VERSION "$Format:%h$"

NS_ :

BS_:

BU_: APB APP APS BCCEN BDY DAS DBG EAS EPAS EPAS2 EPAS3S EPB EPBM ESP GTW GTWU IBST IC MCU OCS PARK PARK3 RADAR RCM RT3000 SCCM SDM SEC TAS TAS2 TAS2DBG TOOL TPMS VCSEATD VCSEATP

BO_ 1497 DAS_carLog: 8 DAS
 SG_ DAS_carLogMultiplexer M : 0|4@1+ (1,0) [0|15] "" GTW
 SG_ DAS_autosteerUnavailableReason m0 : 4|6@1+ (1,0) [0|63] "" GTW
 SG_ DAS_alcBehaviorAbortReason m0 : 10|4@1+ (1,0) [0|15] "" GTW
 SG_ DAS_alcBehaviorState m0 : 14|3@1+ (1,0) [0|7] "" GTW
 SG_ DAS_radarTarget5_dx m1 : 4|12@1+ (0.0625,0) [0|255.9375] "m" GTW
 SG_ DAS_radarTarget1_dx m1 : 16|12@1+ (0.0625,0) [0|255.9375] "m" GTW
 SG_ DAS_radarTarget1_VxRel m1 : 28|8@1+ (0.2,-25.6) [-25.6|25.4] "m/s" GTW
 SG_ DAS_mobileyeVehAebFlag m2 : 4|1@1+ (1,0) [0|1] "" GTW
 SG_ DAS_mobileyePedAebFlag m2 : 5|1@1+ (1,0) [0|1] "" GTW
 SG_ DAS_mobileyeIPSOapproved m2 : 6|1@1+ (1,0) [0|1] "" GTW
 SG_ DAS_fcmSteeringOverride m2 : 7|1@1+ (1,0) [0|1] "" GTW
 SG_ DAS_fcmCollisionStage3Checks m2 : 8|8@1+ (1,0) [0|255] "" GTW
 SG_ DAS_fcmThreatAssesmentMode m2 : 16|3@1+ (1,0) [0|7] "" GTW
 SG_ DAS_constructionArea m2 : 19|2@1+ (1,0) [0|3] "" GTW
 SG_ DAS_associated_rad_object m2 : 22|2@1+ (1,0) [0|3] "" GTW
 SG_ DAS_LC_handsOnReason m2 : 24|6@1+ (1,0) [0|31] "" GTW
 SG_ DAS_ACC_camStatus m2 : 30|2@1+ (1,0) [0|3] "" GTW
 SG_ DAS_aeb_not_activating_reason m2 : 32|5@1+ (1,0) [0|31] "" GTW
 SG_ DAS_handsOnDetected m2 : 38|2@1+ (1,0) [0|2] "" GTW
 SG_ DAS_driveOnNavUnavailableReason m2 : 40|6@1+ (1,0) [0|63] "" GTW
 SG_ DAS_accUnavailableReason m2 : 46|6@1+ (1,0) [0|63] "" GTW
 SG_ DAS_desiredTarget_dx m3 : 16|8@1+ (0.5,0) [0|127] "m" GTW
 SG_ DAS_radarTarget2_dx m3 : 24|12@1+ (0.0625,0) [0|255.9375] "m" GTW
 SG_ DAS_radarTarget3_dx m3 : 36|12@1+ (0.0625,0) [0|255.9375] "m" GTW
 SG_ DAS_radarTarget4_dx m3 : 48|12@1+ (0.0625,0) [0|255.9375] "m" GTW

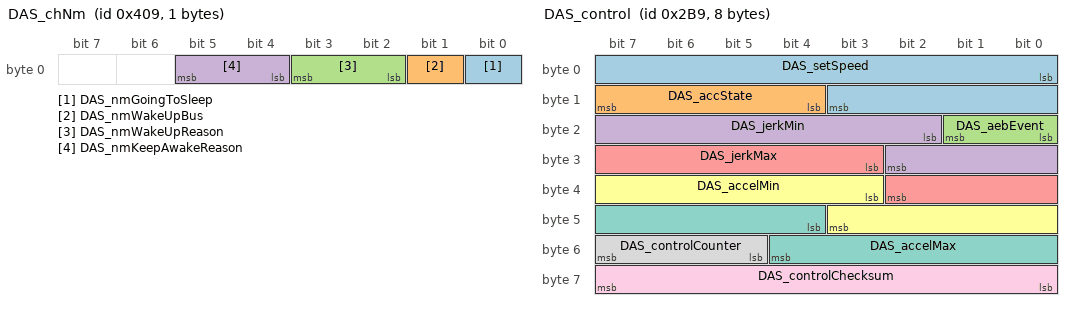
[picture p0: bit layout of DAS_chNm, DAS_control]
BO_ 1033 DAS_chNm: 1 DAS
 SG_ DAS_nmGoingToSleep : 0|1@1+ (1,0) [0|0] "" GTW,APS
 SG_ DAS_nmWakeUpBus : 1|1@1+ (1,0) [0|0] "" GTW,APS
 SG_ DAS_nmWakeUpReason : 2|2@1+ (1,0) [0|0] "" GTW,APS
 SG_ DAS_nmKeepAwakeReason : 4|2@1+ (1,0) [0|0] "" GTW,APS

BO_ 697 DAS_control: 8 DAS
 SG_ DAS_setSpeed : 0|12@1+ (0.1,0) [0|409.4] "kph" GTW,EPB,EPBM,APS
 SG_ DAS_accState : 12|4@1+ (1,0) [0|0] "" GTW,EPB,EPBM,APS
 SG_ DAS_aebEvent : 16|2@1+ (1,0) [0|3] "" GTW,APS
 SG_ DAS_jerkMin : 18|9@1+ (0.03,-15.232) [-15.232|0.098] "m/s^3" GTW,APS
 SG_ DAS_jerkMax : 27|8@1+ (0.059,0) [0|15.045] "m/s^3" GTW,APS
 SG_ DAS_accelMin : 35|9@1+ (0.04,-15) [-15|5.44] "m/s^2" GTW,APS
 SG_ DAS_accelMax : 44|9@1+ (0.04,-15) [-15|5.44] "m/s^2" GTW,APS
 SG_ DAS_controlCounter : 53|3@1+ (1,0) [0|0] "" GTW,APS
 SG_ DAS_controlChecksum : 56|8@1+ (1,0) [0|0] "" GTW,APS

BO_ 1529 DAS_dataLog: 8 DAS
 SG_ DAS_logMltplxr M : 0|8@1+ (1,0) [0|0] "" GTW
 SG_ DAS_init_version m10 : 8|8@1+ (1,0) [0|255] "" Vector__XXX
 SG_ DAS_leftWheel m10 : 16|8@1+ (0.01,0) [0|100] "m" Vector__XXX
 SG_ DAS_RightWheel m10 : 24|8@1+ (0.01,0) [0|100] "m" Vector__XXX
 SG_ DAS_cameraHeight m10 : 32|8@1+ (0.01,0) [0|150] "m" Vector__XXX
 SG_ DAS_focalLength m10 : 40|16@1+ (1,0) [0|500] "" Vector__XXX
 SG_ DAS_horizonFull m10 : 56|8@1+ (1,0) [0|255] "" Vector__XXX
 SG_ DAS_yawFull m11 : 8|8@1- (1,0) [-128|127] "" Vector__XXX
 SG_ DAS_init_autofixHorizon m11 : 16|8@1- (1,0) [-128|127] "" Vector__XXX
 SG_ DAS_init_autofixYaw m11 : 24|8@1- (1,0) [-128|127] "" Vector__XXX
 SG_ DAS_bottom m11 : 32|8@1- (1,0) [-128|127] "" Vector__XXX
 SG_ DAS_top m11 : 40|8@1+ (1,0) [0|255] "" Vector__XXX
 SG_ DAS_minHorizon m11 : 48|8@1- (1,0) [-128|127] "" Vector__XXX
 SG_ DAS_maxHorizon m11 : 56|8@1- (1,0) [-128|127] "" Vector__XXX
 SG_ DAS_maxYaw m12 : 8|8@1+ (1,0) [0|255] "" Vector__XXX
 SG_ DAS_rollAngle m12 : 16|16@1- (0.001,0) [-1500|1500] "rads" Vector__XXX
 SG_ DAS_regionCode m12 : 32|8@1+ (1,0) [0|11] "" Vector__XXX
 SG_ DAS_drivingSide m12 : 40|2@1+ (1,0) [0|3] "" Vector__XXX
 SG_ DAS_refPointX m12 : 48|8@1+ (0.1,0) [0|0] "m" Vector__XXX
 SG_ DAS_refPointY m12 : 56|8@1+ (0.1,0) [0|255] "m" Vector__XXX
 SG_ DAS_roadEdgeWarningEnabled m13 : 8|8@1+ (1,0) [0|255] "" Vector__XXX
 SG_ DAS_detectConstructionArea m13 : 16|8@1+ (1,0) [0|255] "" Vector__XXX
 SG_ DAS_corridor_outer_boundary m13 : 24|8@1+ (0.01,0) [0|255] "m" Vector__XXX
 SG_ DAS_pos_warn_dist_thresh m13 : 32|8@1+ (0.01,0) [0|255] "m" Vector__XXX
 SG_ DAS_outer_dist_term_warn m13 : 40|8@1+ (0.01,0) [0|255] "m" Vector__XXX
 SG_ DAS_narrow_lane_width m13 : 48|8@1+ (0.1,0) [0|255] "m" Vector__XXX
 SG_ DAS_min_lane_width m13 : 56|8@1+ (0.1,0) [0|255] "m" Vector__XXX
 SG_ DAS_speed_turn_off m14 : 8|8@1+ (0.1,0) [0|255] "m/s" Vector__XXX
 SG_ DAS_speed_turn_on m14 : 16|8@1+ (0.1,0) [0|255] "m/s" Vector__XXX
 SG_ DAS_t_max_wrn m14 : 24|8@1+ (1,0) [0|255] "" Vector__XXX
 SG_ DAS_t_min_wrn m14 : 32|8@1+ (1,0) [0|255] "" Vector__XXX
 SG_ DAS_enableLaneCenterPred m14 : 40|8@1+ (1,0) [0|255] "" Vector__XXX
 SG_ DAS_OC_REDUCED_SENSITIVITY m14 : 48|8@1+ (0.1,0) [0|255] "smth" Vector__XXX
 SG_ DAS_Reserved_1 m14 : 56|8@1+ (1,0) [0|255] "" Vector__XXX
 SG_ DAS_HilMode m15 : 8|8@1+ (1,0) [0|255] "" Vector__XXX
 SG_ DAS_StartupFrameIndex m15 : 16|8@1+ (1,0) [0|255] "" Vector__XXX
 SG_ DAS_forcedNonParallel m15 : 24|8@1+ (1,0) [0|255] "" Vector__XXX
 SG_ DAS_disableRectangular m15 : 32|8@1+ (1,0) [0|255] "" Vector__XXX
 SG_ DAS_Reserved_2 m15 : 40|8@1+ (1,0) [0|255] "" Vector__XXX
 SG_ DAS_calib_reply_ret m16 : 8|8@1+ (1,0) [0|255] "" Vector__XXX
 SG_ DAS_calib_reply_ct_type m16 : 16|8@1+ (1,0) [0|255] "" Vector__XXX
 SG_ DAS_calib_reply_ct_ver m16 : 24|8@1+ (1,0) [0|255] "" Vector__XXX
 SG_ DAS_mesp_health_error_code m16 : 32|8@1+ (1,0) [0|255] "" Vector__XXX
 SG_ DAS_mesp_health_error_details m16 : 40|8@1+ (1,0) [0|255] "" Vector__XXX
 SG_ DAS_mesp_health_main_state m16 : 48|8@1+ (1,0) [0|255] "" Vector__XXX
 SG_ DAS_mesp_health_sub_state m16 : 56|8@1+ (1,0) [0|255] "" Vector__XXX
 SG_ DAS_mesp_health_diag_flag_0 m17 : 8|16@1+ (1,0) [0|255] "" Vector__XXX
 SG_ DAS_mesp_health_diag_flag_1 m17 : 24|16@1+ (1,0) [0|255] "" Vector__XXX
 SG_ DAS_mesp_health_state_data_1 m17 : 40|8@1+ (1,0) [0|255] "" Vector__XXX
 SG_ DAS_mesp_health_state_data_2 m17 : 48|8@1+ (1,0) [0|255] "" Vector__XXX
 SG_ DAS_bootmsg_testResults m18 : 8|16@1+ (1,0) [0|255] "" Vector__XXX
 SG_ DAS_bootmsg_EyeQST_Test m18 : 24|32@1+ (1,0) [0|255] "" Vector__XXX
 SG_ DAS_bootmsg_EyeQ_Temp_CPU m18 : 56|8@1- (1,0) [-128|127] "" Vector__XXX
 SG_ DAS_bootmsg_EyeQ_Temp_VMP m19 : 8|8@1+ (1,0) [0|255] "" Vector__XXX
 SG_ DAS_bootmsg_LPDDR2_temp_status m19 : 16|8@1+ (1,0) [0|255] "" Vector__XXX
 SG_ DAS_bootmsg_BootVersion m19 : 24|32@1+ (1,0) [0|255] "" Vector__XXX
 SG_ DAS_bootmsg_BoardRevision m19 : 56|8@1+ (1,0) [0|255] "" Vector__XXX
 SG_ DAS_bootmsg_ApplicationtVersion m20 : 8|32@1+ (1,0) [0|255] "" Vector__XXX
 SG_ DAS_bootmsg_EyeQ_LotNumber m20 : 40|24@1+ (1,0) [0|255] "" Vector__XXX
 SG_ DAS_bootmsg_DDR_MfgCode m21 : 8|8@1+ (1,0) [0|255] "" Vector__XXX
 SG_ DAS_bootmsg_Flash_MfgCode m21 : 16|8@1+ (1,0) [0|255] "" Vector__XXX
 SG_ DAS_bootmsg_BoardProjectCode m21 : 24|8@1+ (1,0) [0|255] "" Vector__XXX
 SG_ DAS_bootmsg_Flash_2_MfgCode m21 : 32|8@1+ (1,0) [0|255] "" Vector__XXX
 SG_ DAS_bootmsg_DDR_Size m21 : 40|8@1+ (1,0) [0|255] "" Vector__XXX
 SG_ DAS_bootmsg_FlashSize m21 : 48|8@1+ (1,0) [0|255] "" Vector__XXX
 SG_ DAS_bootmsg_Flash_2_Size m21 : 56|8@1+ (1,0) [0|255] "" Vector__XXX
 SG_ DAS_scaLogVersion m22 : 8|3@1+ (1,0) [0|15] "" Vector__XXX
 SG_ DAS_scaLogType m22 : 11|3@1+ (1,0) [0|3] "" Vector__XXX
 SG_ DAS_scaLDWstatus m22 : 14|2@1+ (1,0) [0|3] "" Vector__XXX
 SG_ DAS_scaLeftLaneChange m22 : 16|1@1+ (1,0) [0|1] "" Vector__XXX
 SG_ DAS_scaRightLaneChange m22 : 17|1@1+ (1,0) [0|1] "" Vector__XXX
 SG_ DAS_scaMinLeftUltraDist m22 : 18|9@1+ (0.01,0) [0|5.11] "m" Vector__XXX
 SG_ DAS_scaMinRightUltraDist m22 : 27|9@1+ (0.01,0) [0|5.11] "m" Vector__XXX
 SG_ DAS_scaMaxTorsionBarTorque m22 : 36|12@1+ (0.01,-20.5) [-20.5|20.45] "Nm" Vector__XXX
 SG_ DAS_scaMinTTC m22 : 48|4@1+ (0.1,0) [0|1.6] "s" Vector__XXX
 SG_ DAS_scaMaxSteeringWheelAngleRate m22 : 52|7@1+ (1,-63) [-64|63] "deg/s" Vector__XXX
 SG_ DAS_scaOnHighway m22 : 59|1@1+ (1,0) [0|1] "" Vector__XXX
 SG_ DAS_scaTTCDuration m22 : 60|4@1+ (0.1,0) [0|1.6] "s" Vector__XXX
 SG_ DAS_radarTarg5_dx m23 : 8|8@1+ (0.0625,0) [0|15.9375] "m" Vector__XXX
 SG_ DAS_radarTarg1_dx m23 : 16|8@1+ (0.0625,0) [0|15.9375] "m" Vector__XXX
 SG_ DAS_camGenObj_dx m23 : 24|8@1+ (0.05,0) [0|10] "m" Vector__XXX
 SG_ DAS_camCipv_dx m23 : 32|8@1+ (0.2,0) [0|51] "m" Vector__XXX
 SG_ DAS_camPed_dx m23 : 40|8@1+ (0.2,0) [0|51] "m" Vector__XXX
 SG_ DAS_stwAngle m23 : 48|8@1- (1,0) [-128|127] "deg" Vector__XXX
 SG_ DAS_yawRate m23 : 56|8@1+ (0.015625,-2) [-2|2] "rad/s" Vector__XXX

BO_ 1824 DAS_debug: 8 DAS
 SG_ DAS_debugMultiplexer M : 0|8@1+ (1,0) [0|0] "" Vector__XXX
 SG_ DAS_eyeQMode m0 : 8|8@1+ (1,0) [0|0] "" Vector__XXX
 SG_ DAS_absoluteFrame m0 : 16|32@1+ (1,0) [0|0] "" Vector__XXX
 SG_ DAS_pp_offset_desired m0 : 48|8@1- (0.01,0) [-1.28|1.27] "m" Vector__XXX
 SG_ DAS_appMobileyeStatus m0 : 56|8@1+ (1,0) [0|255] "" Vector__XXX
 SG_ DAS_autofixStatus m1 : 8|2@1+ (1,0) [0|0] "" Vector__XXX
 SG_ DAS_calType m1 : 12|4@1+ (1,0) [0|0] "" Vector__XXX
 SG_ DAS_autofixHorizon m1 : 16|8@1- (1,0) [-30|30] "" Vector__XXX
 SG_ DAS_autofixYaw m1 : 24|8@1- (1,0) [-40|40] "" Vector__XXX
 SG_ DAS_freespaceLeftC0 m2 : 8|8@1+ (0.1,-12.8) [-12.8|12.7] "m" Vector__XXX
 SG_ DAS_freespaceLeftC1 m2 : 16|8@1+ (0.0016,-0.2) [-0.2|0.2] "rad" Vector__XXX
 SG_ DAS_freespaceRightC0 m2 : 24|8@1+ (0.1,-12.8) [-12.8|12.7] "m" Vector__XXX
 SG_ DAS_freespaceRightC1 m2 : 32|8@1+ (0.0016,-0.2) [-0.2|0.2] "rad" Vector__XXX
 SG_ DAS_freespaceLeftFarZ m2 : 40|4@1+ (4,0) [0|60] "m" Vector__XXX
 SG_ DAS_freespaceRightFarZ m2 : 44|4@1+ (4,0) [0|60] "m" Vector__XXX
 SG_ DAS_rawLDW m2 : 48|2@1+ (1,0) [0|2] "" Vector__XXX
 SG_ DAS_freespaceLDW m2 : 50|2@1+ (1,0) [0|2] "" Vector__XXX
 SG_ DAS_lanesValid m2 : 52|1@1+ (1,0) [0|1] "" Vector__XXX
 SG_ DAS_eldw m2 : 53|1@1+ (1,0) [0|1] "" Vector__XXX
 SG_ DAS_laneMerge m2 : 54|2@1+ (1,0) [0|4] "" Vector__XXX
 SG_ DAS_freespaceLeftNearZ m2 : 56|4@1+ (4,0) [0|60] "m" Vector__XXX
 SG_ DAS_freespaceRightNearZ m2 : 60|4@1+ (4,0) [0|60] "m" Vector__XXX
 SG_ DAS_highestSeqRcvd m3 : 8|12@1+ (1,0) [0|0] "" Vector__XXX
 SG_ DAS_errorFrameNum m3 : 20|12@1+ (1,0) [0|0] "" Vector__XXX
 SG_ DAS_numOfOldPktErrs m3 : 32|8@1+ (1,0) [0|0] "" Vector__XXX
 SG_ DAS_numOfSeqErrs m3 : 40|8@1+ (1,0) [0|0] "" Vector__XXX
 SG_ DAS_numOfCrcErrs m3 : 48|8@1+ (1,0) [0|0] "" Vector__XXX
 SG_ DAS_unusedW0 m3 : 56|8@1+ (1,0) [0|0] "" Vector__XXX
 SG_ DAS_Stop_Sign_dist m4 : 8|11@1+ (0.1,-50) [-50|102.3] "m" Vector__XXX
 SG_ DAS_Stop_Sign_detected m4 : 19|1@1+ (1,0) [0|1] "" Vector__XXX
 SG_ DAS_Stop_Sign_warning m4 : 20|1@1+ (1,0) [0|1] "" Vector__XXX
 SG_ DAS_TFL_jnc_status m4 : 21|3@1+ (1,0) [0|1] "" Vector__XXX
 SG_ DAS_TFL_jnc_dist m4 : 24|10@1+ (0.25,-50) [-50|205.75] "m" Vector__XXX
 SG_ DAS_TFL_stop_line_dist m4 : 34|11@1+ (0.1,-50) [-50|102.3] "m" Vector__XXX
 SG_ DAS_TFL_ttc m4 : 45|9@1+ (0.01,0) [0|5.11] "seconds" Vector__XXX
 SG_ DAS_TFL_warning m4 : 54|1@1+ (1,0) [0|1] "" Vector__XXX
 SG_ DAS_TFL_mainID m4 : 56|8@1+ (1,0) [0|255] "" Vector__XXX
 SG_ DAS_tbt_filtered m5 : 8|12@1+ (0.01,-20.5) [-20.5|20.45] "Nm" Vector__XXX
 SG_ DAS_apcIntState m6 : 8|4@1+ (1,0) [0|15] "" Vector__XXX
 SG_ DAS_SP_distance m6 : 12|12@1+ (1,0) [0|4095] "cm" Vector__XXX
 SG_ DAS_SP_instruction m6 : 24|4@1+ (1,0) [0|15] "" Vector__XXX
 SG_ DAS_SP_status m6 : 28|4@1+ (1,0) [0|15] "" Vector__XXX
 SG_ DAS_SP_autoSummonRequest m6 : 32|1@1+ (1,0) [0|1] "" Vector__XXX
 SG_ DAS_estimatedSpeedLimitType m6 : 33|3@1+ (1,0) [0|7] "" Vector__XXX
 SG_ DAS_rampType m6 : 39|2@1+ (1,0) [0|3] "" Vector__XXX
 SG_ DAS_estimatedSpeedLimit m6 : 41|10@1+ (0.2,0) [0|102.2] "mph" Vector__XXX
 SG_ DAS_resumeSpeed m6 : 51|10@1+ (0.2,0) [0|102.2] "mph" Vector__XXX
 SG_ DAS_accTimeGap m6 : 61|3@1+ (0.2,0.8) [0.8|2.2] "s" Vector__XXX
 SG_ DAS_SP_cMin m7 : 8|8@1+ (0.0025,-0.32) [-0.32|0.31] "1/m" Vector__XXX
 SG_ DAS_SP_cMax m7 : 16|8@1+ (0.0025,-0.32) [-0.32|0.31] "1/m" Vector__XXX
 SG_ DAS_SP_interCMin m7 : 24|8@1+ (0.0025,-0.32) [-0.32|0.31] "1/m" Vector__XXX
 SG_ DAS_SP_interCMax m7 : 32|8@1+ (0.0025,-0.32) [-0.32|0.31] "1/m" Vector__XXX
 SG_ DAS_SP_cDesired m7 : 40|8@1+ (0.0025,-0.32) [-0.32|0.31] "1/m" Vector__XXX
 SG_ DAS_SP_vehPosX m8 : 8|12@1+ (0.01,-20.48) [-20.48|20.48] "m" Vector__XXX
 SG_ DAS_SP_vehPosY m8 : 20|12@1+ (0.01,-20.48) [-20.48|20.48] "m" Vector__XXX
 SG_ DAS_SP_endPosX m8 : 32|12@1+ (0.01,-20.48) [-20.48|20.48] "m" Vector__XXX
 SG_ DAS_SP_endPosY m8 : 44|12@1+ (0.01,-20.48) [-20.48|20.48] "m" Vector__XXX
 SG_ DAS_SP_sprecordX m9 : 8|12@1+ (0.01,-20.48) [-20.48|20.48] "m" Vector__XXX
 SG_ DAS_SP_sprecordY m9 : 20|12@1+ (0.01,-20.48) [-20.48|20.48] "m" Vector__XXX
 SG_ DAS_SP_collisionDist m9 : 32|12@1+ (0.01,-20.48) [-20.48|20.48] "m" Vector__XXX
 SG_ DAS_dbg_msg_count m10 : 8|8@1+ (1,0) [0|0] "" Vector__XXX
 SG_ DAS_dbg_image_data m10 : 16|48@1+ (1,0) [0|0] "" Vector__XXX
 SG_ DAS_PMM_ussConfidence m11 : 8|8@1+ (1,0) [0|255] "" Vector__XXX
 SG_ DAS_PMM_ussDistance m11 : 16|8@1+ (1,0) [0|255] "cm" Vector__XXX
 SG_ DAS_PMM_radarConfidence m11 : 24|8@1+ (1,0) [0|255] "" Vector__XXX
 SG_ DAS_PMM_radarDistance m11 : 32|8@1+ (1,0) [0|255] "cm" Vector__XXX
 SG_ DAS_PMM_totalThreat m11 : 40|8@1+ (1,0) [0|255] "" Vector__XXX
 SG_ DAS_PMM_frontThreat m11 : 48|2@1+ (1,0) [0|3] "" Vector__XXX
 SG_ DAS_PMM_rearThreat m11 : 50|2@1+ (1,0) [0|3] "" Vector__XXX
 SG_ DAS_i2c_dev_reg m12 : 8|8@1+ (1,0) [0|255] "" Vector__XXX
 SG_ DAS_i2c_dev_data m12 : 16|8@1+ (1,0) [0|255] "" Vector__XXX
 SG_ DAS_i2c_cmd_idx m12 : 24|16@1+ (1,0) [0|255] "" Vector__XXX
 SG_ DAS_i2c_bytes_written m12 : 40|8@1+ (1,0) [0|255] "" Vector__XXX
 SG_ DAS_i2c_sensor_cmd m12 : 48|16@1+ (1,0) [0|255] "" Vector__XXX
 SG_ DAS_ACC_intState m20 : 8|4@1+ (1,0) [0|0] "" Vector__XXX
 SG_ DAS_ACC_camCIPVStatus m20 : 12|3@1+ (1,0) [0|0] "" Vector__XXX
 SG_ DAS_ACC_radCIPVStatus m20 : 15|3@1+ (1,0) [0|0] "" Vector__XXX
 SG_ DAS_ACC_radObstacleRelevant m20 : 18|1@1+ (1,0) [0|0] "" Vector__XXX
 SG_ DAS_ACC_pedestrianStatus m20 : 19|2@1+ (1,0) [0|0] "" Vector__XXX
 SG_ DAS_ACC_drivingOnHighway m20 : 21|1@1+ (1,0) [0|0] "" Vector__XXX
 SG_ DAS_ACC_Ego_speed m20 : 26|10@1+ (0.05,0) [0|51.15] "m/s" Vector__XXX
 SG_ DAS_ACC_Ego_accel m20 : 36|8@1+ (0.06,-10) [-10|5.3] "m/s^2" Vector__XXX
 SG_ DAS_ACC_deadbandMultiplier m20 : 44|7@1+ (0.008,0) [0|1.016] "1" Vector__XXX
 SG_ DAS_ACC_leftLaneExists m20 : 51|1@1+ (1,0) [0|0] "" Vector__XXX
 SG_ DAS_ACC_rightLaneExists m20 : 52|1@1+ (1,0) [0|0] "" Vector__XXX
 SG_ DAS_ACC_camInFrontOfCIPVRel m20 : 53|1@1+ (1,0) [0|0] "" Vector__XXX
 SG_ DAS_ACC_radInFrontOfCIPVRel m20 : 54|1@1+ (1,0) [0|0] "" Vector__XXX
 SG_ DAS_ACC_controlType m20 : 56|3@1+ (1,0) [0|4] "" Vector__XXX
 SG_ DAS_ACC_overtakeMode m20 : 59|2@1+ (1,0) [0|3] "" Vector__XXX
 SG_ DAS_ACC_BCW_decelCheck m20 : 62|1@1+ (1,0) [0|0] "" Vector__XXX
 SG_ DAS_ACC_BCW m20 : 63|1@1+ (1,0) [0|0] "" Vector__XXX
 SG_ DAS_ACC_camCIPVRadObjID m21 : 8|8@1+ (1,0) [0|0] "" Vector__XXX
 SG_ DAS_ACC_camCIPVRadMatchConf m21 : 16|4@1+ (1,0) [0|0] "" Vector__XXX
 SG_ DAS_ACC_camCIPVClass m21 : 20|4@1+ (1,0) [0|0] "" Vector__XXX
 SG_ DAS_ACC_camCIPVRelevancy m21 : 24|4@1+ (1,0) [0|0] "" Vector__XXX
 SG_ DAS_ACC_camCIPVLane m21 : 28|4@1+ (1,0) [0|0] "" Vector__XXX
 SG_ DAS_ACC_camCIPVLaneStatus m21 : 32|4@1+ (1,0) [0|0] "" Vector__XXX
 SG_ DAS_ACC_camCIPVBrakeLight m21 : 36|4@1+ (1,0) [0|0] "" Vector__XXX
 SG_ DAS_ACC_camCIPVMotionStatus m21 : 40|4@1+ (1,0) [0|0] "" Vector__XXX
 SG_ DAS_ACC_camCIPVLost m21 : 44|2@1+ (1,0) [0|0] "" Vector__XXX
 SG_ DAS_ACC_camCIPVFreeSpace m21 : 46|2@1+ (1,0) [0|0] "" Vector__XXX
 SG_ DAS_ACC_camStopAndGoStatus m21 : 48|2@1+ (1,0) [0|0] "" Vector__XXX
 SG_ DAS_ACC_camLeftCloseCutin m21 : 50|1@1+ (1,0) [0|0] "" Vector__XXX
 SG_ DAS_ACC_camRightCloseCutin m21 : 51|1@1+ (1,0) [0|0] "" Vector__XXX
 SG_ DAS_ACC_camPedestriansPresent m21 : 52|1@1+ (1,0) [0|0] "" Vector__XXX
 SG_ DAS_ACC_pathOverlapWTarget m21 : 53|5@1+ (0.2,-2) [-2|4.2] "m" Vector__XXX
 SG_ DAS_ACC_tgt_cipv_dist m22 : 8|10@1+ (0.2,0) [0|204.6] "m" Vector__XXX
 SG_ DAS_ACC_tgt_cipv_camID m22 : 18|6@1+ (1,0) [0|0] "" Vector__XXX
 SG_ DAS_ACC_tgt_cipv_speed m22 : 24|8@1+ (0.2,-5) [-5|46] "m/s" Vector__XXX
 SG_ DAS_ACC_tgt_cipv_radID m22 : 32|6@1+ (1,0) [0|0] "" Vector__XXX
 SG_ DAS_ACC_tgt_cipv_accel m22 : 38|8@1+ (0.06,-10) [-10|5.3] "m/s^2" Vector__XXX
 SG_ DAS_ACC_tgt_cipv_controlState m22 : 46|4@1+ (1,0) [0|0] "" Vector__XXX
 SG_ DAS_ACC_tgt_cipv_type m22 : 50|4@1+ (1,0) [0|0] "" Vector__XXX
 SG_ DAS_ACC_tgt_cipv_valid m22 : 54|1@1+ (1,0) [0|0] "" Vector__XXX
 SG_ DAS_ACC_tgt_cipv_new m22 : 55|1@1+ (1,0) [0|0] "" Vector__XXX
 SG_ DAS_ACC_tgt_cipv_copied m22 : 56|1@1+ (1,0) [0|0] "" Vector__XXX
 SG_ DAS_ACC_tgt_cipv_brakeLights m22 : 57|1@1+ (1,0) [0|0] "" Vector__XXX
 SG_ DAS_ACC_tgt_cipv_blinkerLeft m22 : 58|1@1+ (1,0) [0|0] "" Vector__XXX
 SG_ DAS_ACC_tgt_cipv_blinkerRight m22 : 59|1@1+ (1,0) [0|0] "" Vector__XXX
 SG_ DAS_ACC_tgt_cipv_delay m22 : 60|4@1+ (20,0) [0|300] "ms" Vector__XXX
 SG_ DAS_ACC_tgt_cipv2_dist m23 : 8|10@1+ (0.2,0) [0|204.6] "m" Vector__XXX
 SG_ DAS_ACC_tgt_cipv2_camID m23 : 18|6@1+ (1,0) [0|0] "" Vector__XXX
 SG_ DAS_ACC_tgt_cipv2_speed m23 : 24|8@1+ (0.2,-5) [-5|46] "m/s" Vector__XXX
 SG_ DAS_ACC_tgt_cipv2_radID m23 : 32|6@1+ (1,0) [0|0] "" Vector__XXX
 SG_ DAS_ACC_tgt_cipv2_accel m23 : 38|8@1+ (0.06,-10) [-10|5.3] "m/s^2" Vector__XXX
 SG_ DAS_ACC_tgt_cipv2_controlState m23 : 46|4@1+ (1,0) [0|0] "" Vector__XXX
 SG_ DAS_ACC_tgt_cipv2_type m23 : 50|4@1+ (1,0) [0|0] "" Vector__XXX
 SG_ DAS_ACC_tgt_cipv2_valid m23 : 54|1@1+ (1,0) [0|0] "" Vector__XXX
 SG_ DAS_ACC_tgt_cipv2_new m23 : 55|1@1+ (1,0) [0|0] "" Vector__XXX
 SG_ DAS_ACC_tgt_cipv2_copied m23 : 56|1@1+ (1,0) [0|0] "" Vector__XXX
 SG_ DAS_ACC_tgt_cipv2_brakeLights m23 : 57|1@1+ (1,0) [0|0] "" Vector__XXX
 SG_ DAS_ACC_tgt_cipv2_blinkerLeft m23 : 58|1@1+ (1,0) [0|0] "" Vector__XXX
 SG_ DAS_ACC_tgt_cipv2_blinkerRight m23 : 59|1@1+ (1,0) [0|0] "" Vector__XXX
 SG_ DAS_ACC_tgt_cipv2_delay m23 : 60|4@1+ (20,0) [0|300] "ms" Vector__XXX
 SG_ DAS_ACC_tgt_mcvl_dist m24 : 8|10@1+ (0.2,0) [0|204.6] "m" Vector__XXX
 SG_ DAS_ACC_tgt_mcvl_camID m24 : 18|6@1+ (1,0) [0|0] "" Vector__XXX
 SG_ DAS_ACC_tgt_mcvl_speed m24 : 24|8@1+ (0.2,-5) [-5|46] "m/s" Vector__XXX
 SG_ DAS_ACC_tgt_mcvl_radID m24 : 32|6@1+ (1,0) [0|0] "" Vector__XXX
 SG_ DAS_ACC_tgt_mcvl_accel m24 : 38|8@1+ (0.06,-10) [-10|5.3] "m/s^2" Vector__XXX
 SG_ DAS_ACC_tgt_mcvl_controlState m24 : 46|4@1+ (1,0) [0|0] "" Vector__XXX
 SG_ DAS_ACC_tgt_mcvl_type m24 : 50|4@1+ (1,0) [0|0] "" Vector__XXX
 SG_ DAS_ACC_tgt_mcvl_valid m24 : 54|1@1+ (1,0) [0|0] "" Vector__XXX
 SG_ DAS_ACC_tgt_mcvl_new m24 : 55|1@1+ (1,0) [0|0] "" Vector__XXX
 SG_ DAS_ACC_tgt_mcvl_copied m24 : 56|1@1+ (1,0) [0|0] "" Vector__XXX
 SG_ DAS_ACC_tgt_mcvl_brakeLights m24 : 57|1@1+ (1,0) [0|0] "" Vector__XXX
 SG_ DAS_ACC_tgt_mcvl_blinkerLeft m24 : 58|1@1+ (1,0) [0|0] "" Vector__XXX
 SG_ DAS_ACC_tgt_mcvl_blinkerRight m24 : 59|1@1+ (1,0) [0|0] "" Vector__XXX
 SG_ DAS_ACC_tgt_mcvl_delay m24 : 60|4@1+ (20,0) [0|300] "ms" Vector__XXX
 SG_ DAS_ACC_tgt_mcvr_dist m25 : 8|10@1+ (0.2,0) [0|204.6] "m" Vector__XXX
 SG_ DAS_ACC_tgt_mcvr_camID m25 : 18|6@1+ (1,0) [0|0] "" Vector__XXX
 SG_ DAS_ACC_tgt_mcvr_speed m25 : 24|8@1+ (0.2,-5) [-5|46] "m/s" Vector__XXX
 SG_ DAS_ACC_tgt_mcvr_radID m25 : 32|6@1+ (1,0) [0|0] "" Vector__XXX
 SG_ DAS_ACC_tgt_mcvr_accel m25 : 38|8@1+ (0.06,-10) [-10|5.3] "m/s^2" Vector__XXX
 SG_ DAS_ACC_tgt_mcvr_controlState m25 : 46|4@1+ (1,0) [0|0] "" Vector__XXX
 SG_ DAS_ACC_tgt_mcvr_type m25 : 50|4@1+ (1,0) [0|0] "" Vector__XXX
 SG_ DAS_ACC_tgt_mcvr_valid m25 : 54|1@1+ (1,0) [0|0] "" Vector__XXX
 SG_ DAS_ACC_tgt_mcvr_new m25 : 55|1@1+ (1,0) [0|0] "" Vector__XXX
 SG_ DAS_ACC_tgt_mcvr_copied m25 : 56|1@1+ (1,0) [0|0] "" Vector__XXX
 SG_ DAS_ACC_tgt_mcvr_brakeLights m25 : 57|1@1+ (1,0) [0|0] "" Vector__XXX
 SG_ DAS_ACC_tgt_mcvr_blinkerLeft m25 : 58|1@1+ (1,0) [0|0] "" Vector__XXX
 SG_ DAS_ACC_tgt_mcvr_blinkerRight m25 : 59|1@1+ (1,0) [0|0] "" Vector__XXX
 SG_ DAS_ACC_tgt_mcvr_delay m25 : 60|4@1+ (20,0) [0|300] "ms" Vector__XXX
 SG_ DAS_ACC_tgt_cutin_dist m26 : 8|10@1+ (0.2,0) [0|204.6] "m" Vector__XXX
 SG_ DAS_ACC_tgt_cutin_camID m26 : 18|6@1+ (1,0) [0|0] "" Vector__XXX
 SG_ DAS_ACC_tgt_cutin_speed m26 : 24|8@1+ (0.2,-5) [-5|46] "m/s" Vector__XXX
 SG_ DAS_ACC_tgt_cutin_radID m26 : 32|6@1+ (1,0) [0|0] "" Vector__XXX
 SG_ DAS_ACC_tgt_cutin_accel m26 : 38|8@1+ (0.06,-10) [-10|5.3] "m/s^2" Vector__XXX
 SG_ DAS_ACC_tgt_cutin_controlState m26 : 46|4@1+ (1,0) [0|0] "" Vector__XXX
 SG_ DAS_ACC_tgt_cutin_type m26 : 50|4@1+ (1,0) [0|0] "" Vector__XXX
 SG_ DAS_ACC_tgt_cutin_valid m26 : 54|1@1+ (1,0) [0|0] "" Vector__XXX
 SG_ DAS_ACC_tgt_cutin_new m26 : 55|1@1+ (1,0) [0|0] "" Vector__XXX
 SG_ DAS_ACC_tgt_cutin_copied m26 : 56|1@1+ (1,0) [0|0] "" Vector__XXX
 SG_ DAS_ACC_tgt_cutin_brakeLights m26 : 57|1@1+ (1,0) [0|0] "" Vector__XXX
 SG_ DAS_ACC_tgt_cutin_blinkerLeft m26 : 58|1@1+ (1,0) [0|0] "" Vector__XXX
 SG_ DAS_ACC_tgt_cutin_blinkerRight m26 : 59|1@1+ (1,0) [0|0] "" Vector__XXX
 SG_ DAS_ACC_tgt_cutin_delay m26 : 60|4@1+ (20,0) [0|300] "ms" Vector__XXX
 SG_ DAS_ACC_Target6_dist m27 : 8|10@1+ (0.2,0) [0|204.6] "m" Vector__XXX
 SG_ DAS_ACC_Target6_camID m27 : 18|6@1+ (1,0) [0|0] "" Vector__XXX
 SG_ DAS_ACC_Target6_speed m27 : 24|8@1+ (0.2,-5) [-5|46] "m/s" Vector__XXX
 SG_ DAS_ACC_Target6_radID m27 : 34|6@1+ (1,0) [0|0] "" Vector__XXX
 SG_ DAS_ACC_Target6_accel m27 : 40|8@1+ (0.06,-10) [-10|5.3] "m/s^2" Vector__XXX
 SG_ DAS_ACC_Target6_controlState m27 : 48|4@1+ (1,0) [0|0] "" Vector__XXX
 SG_ DAS_ACC_Target6_type m27 : 52|4@1+ (1,0) [0|0] "" Vector__XXX
 SG_ DAS_ACC_Target6_valid m27 : 56|1@1+ (1,0) [0|0] "" Vector__XXX
 SG_ DAS_ACC_Target6_new m27 : 57|1@1+ (1,0) [0|0] "" Vector__XXX
 SG_ DAS_ACC_Target6_stop_line_raw m27 : 58|1@1+ (1,0) [0|0] "" Vector__XXX
 SG_ DAS_ACC_Target6_delay m27 : 59|4@1+ (20,0) [0|300] "ms" Vector__XXX
 SG_ DAS_ACC_Control_targetID m28 : 8|4@1+ (1,0) [0|0] "" Vector__XXX
 SG_ DAS_ACC_Control_sl_d m28 : 12|10@1+ (0.2,0) [0|204.6] "m" Vector__XXX
 SG_ DAS_ACC_Control_ve_d m28 : 22|10@1+ (0.05,0) [0|51.15] "m/s" Vector__XXX
 SG_ DAS_ACC_Control_severity m28 : 32|10@1+ (0.005,-2.56) [-2.56|2.555] "1" Vector__XXX
 SG_ DAS_ACC_Control_deltaV_deriv m28 : 42|10@1+ (0.01,-5) [-5|5.23] "m/s^2" Vector__XXX
 SG_ DAS_ACC_Activate_healthy m28 : 52|1@1+ (1,0) [0|0] "" Vector__XXX
 SG_ DAS_ACC_Activate_travel_dist m28 : 53|1@1+ (1,0) [0|0] "" Vector__XXX
 SG_ DAS_ACC_Activate_road_class m28 : 54|1@1+ (1,0) [0|0] "" Vector__XXX
 SG_ DAS_ACC_Activate_stw_angle m28 : 55|1@1+ (1,0) [0|0] "" Vector__XXX
 SG_ DAS_ACC_Activate_rad_tar_5 m28 : 56|1@1+ (1,0) [0|0] "" Vector__XXX
 SG_ DAS_ACC_Activate_ultra_obs m28 : 57|1@1+ (1,0) [0|0] "" Vector__XXX
 SG_ DAS_ACC_Activate_freespace m28 : 58|1@1+ (1,0) [0|0] "" Vector__XXX
 SG_ DAS_ACC_Activate_pedestrian m28 : 59|1@1+ (1,0) [0|0] "" Vector__XXX
 SG_ DAS_ACC_Restrict_targetID m29 : 8|4@1+ (1,0) [0|0] "" Vector__XXX
 SG_ DAS_ACC_Restrict_sl_d m29 : 12|10@1+ (0.2,0) [0|204.6] "m" Vector__XXX
 SG_ DAS_ACC_Restrict_ve_d m29 : 22|10@1+ (0.05,0) [0|51.15] "m/s" Vector__XXX
 SG_ DAS_ACC_Restrict_severity m29 : 32|10@1+ (0.005,-2.56) [-2.56|2.555] "1" Vector__XXX
 SG_ DAS_ACC_Restrict_deltaV_deriv m29 : 42|10@1+ (0.01,-5) [-5|5.23] "m/s^2" Vector__XXX
 SG_ DAS_LC_EgoPitchMotionRate m29 : 52|10@1+ (0.05,-25) [-25|25] "deg/s" Vector__XXX
 SG_ DAS_FCM_CIPV_distance m30 : 8|12@1+ (0.0625,0) [0|255.9375] "m" Vector__XXX
 SG_ DAS_FCM_CIPV_latDistance m30 : 20|12@1- (0.05,0) [-102.4|102.35] "m" Vector__XXX
 SG_ DAS_FCM_CIPV_width m30 : 32|7@1+ (0.05,0) [0|6.35] "m" Vector__XXX
 SG_ DAS_FCM_CIPV_relSpeed m30 : 39|12@1+ (0.0625,-128) [-128|127.9375] "m/s" Vector__XXX
 SG_ DAS_FCM_CIPV_relAccel m30 : 51|10@1+ (0.03125,-16) [-16|15.96875] "m/s^2" Vector__XXX
 SG_ DAS_FCM_CIPV_valid m30 : 61|1@1+ (1,0) [0|0] "" Vector__XXX
 SG_ DAS_FCM_CIPV_radarMatchConfOK m30 : 62|1@1+ (1,0) [0|0] "" Vector__XXX
 SG_ DAS_FCM_MCP_distance m31 : 8|12@1+ (0.0625,0) [0|255.9375] "m" Vector__XXX
 SG_ DAS_FCM_MCP_latDistance m31 : 20|12@1- (0.05,0) [-102.4|102.35] "m" Vector__XXX
 SG_ DAS_FCM_MCP_width m31 : 32|7@1+ (0.05,0) [0|6.35] "m" Vector__XXX
 SG_ DAS_FCM_MCP_relSpeed m31 : 39|12@1+ (0.0625,-128) [-128|127.9375] "m/s" Vector__XXX
 SG_ DAS_FCM_MCP_relAccel m31 : 51|10@1+ (0.03125,-16) [-16|15.96875] "m/s^2" Vector__XXX
 SG_ DAS_FCM_MCP_valid m31 : 61|1@1+ (1,0) [0|0] "" Vector__XXX
 SG_ DAS_FCM_MCP_radarMatchConfOK m31 : 62|1@1+ (1,0) [0|0] "" Vector__XXX
 SG_ DAS_FCM_SL_distance m32 : 8|12@1+ (0.0625,0) [0|255.9375] "m" Vector__XXX
 SG_ DAS_FCM_SL_latDistance m32 : 20|12@1- (0.05,0) [-102.4|102.35] "m" Vector__XXX
 SG_ DAS_FCM_SL_width m32 : 32|7@1+ (0.05,0) [0|6.35] "m" Vector__XXX
 SG_ DAS_FCM_SL_relSpeed m32 : 39|12@1+ (0.0625,-128) [-128|127.9375] "m/s" Vector__XXX
 SG_ DAS_FCM_SL_relAccel m32 : 51|10@1+ (0.03125,-16) [-16|15.96875] "m/s^2" Vector__XXX
 SG_ DAS_FCM_SL_valid m32 : 61|1@1+ (1,0) [0|0] "" Vector__XXX
 SG_ DAS_FCM_SL_radarMatchConfOK m32 : 62|1@1+ (1,0) [0|0] "" Vector__XXX
 SG_ DAS_FCM_TA_collisionStage m33 : 8|2@1+ (1,0) [0|0] "" Vector__XXX
 SG_ DAS_FCM_TA_collisionOverlap m33 : 10|6@1+ (0.1,0) [0|6.3] "m" Vector__XXX
 SG_ DAS_FCM_state m33 : 16|8@1+ (1,0) [0|0] "" Vector__XXX
 SG_ DAS_FCM_TA_rstCollStRsn m33 : 24|8@1+ (1,0) [0|255] "" Vector__XXX
 SG_ DAS_FCM_TA_reqAccelDrvr m33 : 32|7@1+ (0.1,-12.7) [-12.7|0] "m/s^2" Vector__XXX
 SG_ DAS_FCM_TA_reqAccelAeb m33 : 39|7@1+ (0.1,-12.7) [-12.7|0] "m/s^2" Vector__XXX
 SG_ DAS_FCM_TA_distDiffSteerDrvr m33 : 46|8@1+ (0.1,0) [0|25.5] "m" Vector__XXX
 SG_ DAS_FCM_TA_distDiffSteerAeb m33 : 54|8@1+ (0.1,0) [0|25.5] "m" Vector__XXX
 SG_ DAS_FCM_TA_mode m33 : 62|2@1+ (1,0) [0|3] "" Vector__XXX
 SG_ DAS_FCM_TA_stage2Checks m34 : 24|8@1+ (1,0) [0|255] "" Vector__XXX
 SG_ DAS_FCM_TA_stage3Checks m34 : 32|8@1+ (1,0) [0|255] "" Vector__XXX
 SG_ DAS_FCM_DBG_suppressed m34 : 40|1@1+ (1,0) [0|1] "" Vector__XXX
 SG_ DAS_FCM_DBG_me_flag m34 : 41|1@1+ (1,0) [0|1] "" Vector__XXX
 SG_ DAS_FCM_DBG_aeb_cancel m34 : 43|1@1+ (1,0) [0|1] "" Vector__XXX
 SG_ DAS_FCM_DBG_aeb_fault m34 : 44|1@1+ (1,0) [0|1] "" Vector__XXX
 SG_ DAS_FCM_DBG_ACC1_fused m34 : 45|1@1+ (1,0) [0|1] "" Vector__XXX
 SG_ DAS_FCM_DBG_ACC5_fused m34 : 46|1@1+ (1,0) [0|1] "" Vector__XXX
 SG_ DAS_FCM_DBG_ID m34 : 47|16@1+ (1,0) [0|65534] "" Vector__XXX
 SG_ DAS_FCM_DBG_cam_dist m35 : 8|12@1+ (0.0625,0) [0|255.9375] "m" Vector__XXX
 SG_ DAS_FCM_DBG_cam_relvel m35 : 20|12@1+ (0.0625,-128) [-128|127.9375] "m/s" Vector__XXX
 SG_ DAS_FCM_DBG_probability m35 : 32|6@1+ (0.05,0) [0|3.15] "prob" Vector__XXX
 SG_ DAS_FCM_DBG_trust m35 : 38|6@1+ (0.05,0) [0|3.15] "prob" Vector__XXX
 SG_ DAS_FCM_DBG_rvl_check m35 : 44|6@1+ (0.05,0) [0|3.15] "prob" Vector__XXX
 SG_ DAS_FCM_DBG_dist_check m35 : 50|6@1+ (0.05,0) [0|3.15] "prob" Vector__XXX
 SG_ DAS_FCM_DBG_ass_age m35 : 56|6@1+ (100,0) [0|6300] "" Vector__XXX
 SG_ DAS_IDF_checkSensors m36 : 8|1@1+ (1,0) [0|1] "" Vector__XXX
 SG_ DAS_IDF_checkClass m36 : 9|1@1+ (1,0) [0|1] "" Vector__XXX
 SG_ DAS_IDF_checkOverlap m36 : 10|1@1+ (1,0) [0|1] "" Vector__XXX
 SG_ DAS_IDF_checkTimeToCollision m36 : 11|1@1+ (1,0) [0|1] "" Vector__XXX
 SG_ DAS_IDF_checkTargetProbability m36 : 12|1@1+ (1,0) [0|1] "" Vector__XXX
 SG_ DAS_IDF_checkSteeringAvoidance m36 : 13|1@1+ (1,0) [0|1] "" Vector__XXX
 SG_ DAS_IDF_checkBrakingAvoidance m36 : 14|1@1+ (1,0) [0|1] "" Vector__XXX
 SG_ DAS_IDF_checkEgoSpeed m36 : 15|1@1+ (1,0) [0|1] "" Vector__XXX
 SG_ DAS_IDF_timeToCollision m36 : 16|8@1+ (10,0) [0|2550] "ms" Vector__XXX
 SG_ DAS_IDF_objectClass m36 : 24|3@1+ (1,0) [0|7] "" Vector__XXX
 SG_ DAS_IDF_predictedImpactVelocity m36 : 27|7@1+ (0.5,0) [0|63.5] "m/s" GTW
 SG_ DAS_IDF_predictedOverlap m36 : 34|8@1+ (0.5,0) [0|127.5] "%" GTW
 SG_ DAS_IDF_checkImpactVelocity m36 : 42|1@1+ (1,0) [0|1] "" Vector__XXX
 SG_ DAS_IDF_checkCameraTTC m36 : 43|1@1+ (1,0) [0|1] "" Vector__XXX
 SG_ DAS_IDF_checkLateralAcceleration m36 : 44|1@1+ (1,0) [0|1] "" Vector__XXX
 SG_ DAS_IDF_measurementState m36 : 45|2@1+ (1,0) [0|3] "" Vector__XXX
 SG_ DAS_LCM_aeb_unavailable_reason m36 : 47|5@1+ (1,0) [0|31] "" Vector__XXX
 SG_ DAS_LCM_fcw_unavailable_reason m36 : 52|5@1+ (1,0) [0|31] "" Vector__XXX
 SG_ DAS_LCM_CIPV_dx m37 : 8|12@1+ (0.0625,0) [0|255.9375] "m" Vector__XXX
 SG_ DAS_LCM_CIPV_dy m37 : 20|12@1- (0.05,0) [-102.4|102.35] "m" Vector__XXX
 SG_ DAS_LCM_CIPV_width m37 : 32|8@1+ (0.05,0) [0|12.7] "m" Vector__XXX
 SG_ DAS_LCM_CIPV_vx m37 : 40|12@1+ (0.0625,-128) [-128|127.9375] "m/s" Vector__XXX
 SG_ DAS_LCM_CIPV_vy m37 : 52|8@1+ (0.1,-12.8) [-12.8|12.7] "m/s" Vector__XXX
 SG_ DAS_LCM_CIPV_type m37 : 60|2@1+ (1,0) [0|3] "" Vector__XXX
 SG_ DAS_LCM_CIPV_valid m37 : 62|1@1+ (1,0) [0|1] "" Vector__XXX
 SG_ DAS_LCM_CIPV_ax m38 : 8|8@1+ (0.1,-12.8) [-12.8|12.7] "m/s^2" Vector__XXX
 SG_ DAS_LCM_CIPV_ay m38 : 16|8@1+ (0.1,-12.8) [-12.8|12.7] "m/s^2" Vector__XXX
 SG_ DAS_LCM_CIPV_id m38 : 24|8@1+ (1,0) [0|255] "" Vector__XXX
 SG_ DAS_LCM_CIPV_track_age m38 : 32|12@1+ (0.01,0) [0|40.95] "s" Vector__XXX
 SG_ DAS_LCM_CIPV_overlap m38 : 44|8@1+ (0.05,-6.3) [-6.3|6.4] "m" Vector__XXX
 SG_ DAS_LCM_CIPV_ttc m38 : 52|6@1+ (0.05,0) [0|3.15] "s" Vector__XXX
 SG_ DAS_LCM_CIPV_headway_time m38 : 58|6@1+ (0.1,0) [0|6.3] "s" Vector__XXX
 SG_ DAS_LCM_driver_reaction_time m39 : 8|4@1+ (0.1,0.8) [0.8|2.3] "s" Vector__XXX
 SG_ DAS_LCM_override_stw_angle m39 : 12|1@1+ (1,0) [0|1] "" Vector__XXX
 SG_ DAS_LCM_override_stw_rate m39 : 13|1@1+ (1,0) [0|1] "" Vector__XXX
 SG_ DAS_LCM_override_accelerator m39 : 14|1@1+ (1,0) [0|1] "" Vector__XXX
 SG_ DAS_LCM_override_brake m39 : 15|1@1+ (1,0) [0|1] "" Vector__XXX
 SG_ DAS_LCM_override_blinker m39 : 16|1@1+ (1,0) [0|1] "" Vector__XXX
 SG_ DAS_LCM_override_accelerator_aeb m39 : 17|1@1+ (1,0) [0|1] "" Vector__XXX
 SG_ DAS_LCM_override_brake_aeb m39 : 18|1@1+ (1,0) [0|1] "" Vector__XXX
 SG_ DAS_LCM_aeb_abs_accel m39 : 19|1@1+ (1,0) [0|1] "" Vector__XXX
 SG_ DAS_LCM_aeb_overlap m39 : 20|1@1+ (1,0) [0|1] "" Vector__XXX
 SG_ DAS_LCM_aeb_current_accel m39 : 21|1@1+ (1,0) [0|1] "" Vector__XXX
 SG_ DAS_LCM_aeb_delayed_accel m39 : 22|1@1+ (1,0) [0|1] "" Vector__XXX
 SG_ DAS_LCM_aeb_evading_dist m39 : 23|1@1+ (1,0) [0|1] "" Vector__XXX
 SG_ DAS_LCM_aeb_rel_vel m39 : 24|1@1+ (1,0) [0|1] "" Vector__XXX
 SG_ DAS_LCM_jerk_abs_accel m39 : 25|1@1+ (1,0) [0|1] "" Vector__XXX
 SG_ DAS_LCM_jerk_overlap m39 : 26|1@1+ (1,0) [0|1] "" Vector__XXX
 SG_ DAS_LCM_jerk_current_accel m39 : 27|1@1+ (1,0) [0|1] "" Vector__XXX
 SG_ DAS_LCM_jerk_delayed_accel m39 : 28|1@1+ (1,0) [0|1] "" Vector__XXX
 SG_ DAS_LCM_jerk_evading_dist m39 : 29|1@1+ (1,0) [0|1] "" Vector__XXX
 SG_ DAS_LCM_jerk_rel_vel m39 : 30|1@1+ (1,0) [0|1] "" Vector__XXX
 SG_ DAS_LCM_fcw_abs_accel m39 : 31|1@1+ (1,0) [0|1] "" Vector__XXX
 SG_ DAS_LCM_fcw_overlap m39 : 32|1@1+ (1,0) [0|1] "" Vector__XXX
 SG_ DAS_LCM_fcw_current_accel m39 : 33|1@1+ (1,0) [0|1] "" Vector__XXX
 SG_ DAS_LCM_fcw_delayed_accel m39 : 34|1@1+ (1,0) [0|1] "" Vector__XXX
 SG_ DAS_LCM_fcw_evading_dist m39 : 35|1@1+ (1,0) [0|1] "" Vector__XXX
 SG_ DAS_LCM_fcw_rel_vel m39 : 36|1@1+ (1,0) [0|1] "" Vector__XXX
 SG_ DAS_LCM_state m39 : 37|4@1+ (1,0) [0|15] "" Vector__XXX
 SG_ DAS_LCM_required_system_accel m39 : 41|7@1+ (0.1,-12.7) [-12.7|0] "m/s^2" Vector__XXX
 SG_ DAS_LCM_aeb_evading_distance m39 : 48|8@1+ (0.1,-12.7) [-12.7|12.8] "m" Vector__XXX
 SG_ DAS_LCM_required_driver_accel m39 : 56|8@1+ (0.1,-12.7) [-12.7|0] "m/s^2" Vector__XXX
 SG_ DAS_LC_VirtualLaneViewRange m40 : 8|10@1+ (0.5,0) [0|511.5] "m" Vector__XXX
 SG_ DAS_LC_VirtualLaneWidth m40 : 18|8@1+ (0.025,0) [0|6.375] "m" Vector__XXX
 SG_ DAS_LC_AutopilotInternalState m40 : 26|4@1+ (1,0) [0|15] "" Vector__XXX
 SG_ DAS_LC_Speed_Ctrl_Active m40 : 30|1@1+ (1,0) [0|1] "" Vector__XXX
 SG_ DAS_LC_Crit_Left_Lane m40 : 31|8@1+ (0.2,-25.5) [-25.5|25.5] "m" Vector__XXX
 SG_ DAS_LC_Crit_Right_Lane m40 : 47|8@1+ (0.2,-25.5) [-25.5|25.5] "m" Vector__XXX
 SG_ DAS_LC_Hands_On_Caused_By_Curve m40 : 63|1@1+ (1,0) [0|1] "" Vector__XXX
 SG_ DAS_HmViewRangeActivationCtr m41 : 8|7@1+ (1,0) [0|127] "" Vector__XXX
 SG_ DAS_HmGeneralActivationCtr m41 : 16|7@1+ (1,0) [0|127] "" Vector__XXX
 SG_ DAS_HmSecondaryVlInput m41 : 23|1@1+ (1,0) [0|1] "" Vector__XXX
 SG_ DAS_PF_Navigation_STW m41 : 24|13@1+ (0.1,-409.6) [-409.6|409.5] "deg" Vector__XXX
 SG_ DAS_PF_VirtualLane_STW m41 : 37|13@1+ (0.1,-409.6) [-409.6|409.5] "deg" Vector__XXX
 SG_ DAS_PF_PercentConsistency m41 : 50|14@1+ (0.01,0) [0|163.83] "%" Vector__XXX
 SG_ DAS_LC_SteeringOffsetEstimate m42 : 8|8@1- (0.1,0) [-12.8|12.7] "deg" Vector__XXX
 SG_ DAS_LC_PathFollowerAngle m42 : 24|13@1- (0.1,0) [-409.6|409.5] "deg" Vector__XXX
 SG_ DAS_HmLaneViewRangeOAL m42 : 40|3@1+ (1,0) [0|5] "" Vector__XXX
 SG_ DAS_HmVlNoInputsOAL m42 : 61|3@1+ (1,0) [0|5] "" Vector__XXX
 SG_ DAS_VWall_Left_ultra_dist m43 : 8|9@1+ (0.01,0) [0|5.11] "m" Vector__XXX
 SG_ DAS_VWall_Right_type m44 : 8|3@1+ (1,0) [0|7] "" Vector__XXX
 SG_ DAS_VWall_Right_ultra_dist m44 : 16|9@1+ (0.01,0) [0|5.11] "m" Vector__XXX
 SG_ DAS_VWall_Right_c0 m44 : 32|8@1+ (0.035,0) [0|7] "m" Vector__XXX
 SG_ DAS_VWall_Right_c1 m44 : 40|8@1+ (0.0016,-0.2) [-0.2|0.2] "rad" Vector__XXX
 SG_ DAS_VWall_Right_c2 m44 : 48|8@1+ (2E-05,-0.0025) [-0.0025|0.0025] "m-1" Vector__XXX
 SG_ DAS_VWall_Right_c3 m44 : 56|8@1+ (2.4E-07,-3E-05) [-3E-05|3E-05] "m-2" Vector__XXX
 SG_ DAS_SCA_state m45 : 8|4@1+ (1,0) [0|15] "" Vector__XXX
 SG_ DAS_SCA_angleActive m45 : 12|1@1+ (1,0) [0|1] "" Vector__XXX
 SG_ DAS_SCA_egoRightOfCenter m45 : 13|1@1+ (1,0) [0|1] "" Vector__XXX
 SG_ DAS_SCA_egoLeftOfCenter m45 : 14|1@1+ (1,0) [0|1] "" Vector__XXX
 SG_ DAS_SCA_egoMovingLeft m45 : 15|1@1+ (1,0) [0|1] "" Vector__XXX
 SG_ DAS_SCA_TWC_Left m45 : 16|8@1+ (0.01,0) [0|2.55] "s" Vector__XXX
 SG_ DAS_SCA_TWC_Right m45 : 24|8@1+ (0.01,0) [0|2.55] "s" Vector__XXX
 SG_ DAS_torque_filt_0p5Hz m45 : 32|12@1+ (0.01,-20.5) [-20.5|20.45] "Nm" Vector__XXX
 SG_ DAS_hands_on_detected m45 : 44|1@1+ (1,0) [0|1] "" Vector__XXX
 SG_ DAS_TBT_offset m45 : 45|11@1+ (0.001,-1) [-1|1] "Nm" Vector__XXX
 SG_ DAS_hands_on_warning_cipv_valid m45 : 59|1@1+ (1,0) [0|1] "" Vector__XXX
 SG_ DAS_SCA_egoMovingRight m45 : 60|1@1+ (1,0) [0|1] "" Vector__XXX
 SG_ DAS_SCA_polyValid m45 : 61|1@1+ (1,0) [0|1] "" Vector__XXX
 SG_ DAS_SCA_egoCentered m45 : 62|1@1+ (1,0) [0|1] "" Vector__XXX
 SG_ DAS_driver_interaction_detected m45 : 63|1@1+ (1,0) [0|1] "" Vector__XXX
 SG_ DAS_Planner_viewRange m46 : 8|9@1+ (0.5,0) [0|255.5] "m" Vector__XXX
 SG_ DAS_Planner_internalstate m46 : 17|4@1+ (1,0) [0|12] "" Vector__XXX
 SG_ DAS_Planner_externalstate m46 : 21|4@1+ (1,0) [0|15] "" Vector__XXX
 SG_ DAS_Planner_c0 m46 : 32|8@1- (0.1,0) [-12.8|12.7] "m" Vector__XXX
 SG_ DAS_Planner_c1 m46 : 40|8@1+ (0.0016,-0.2) [-0.2|0.2] "rad" Vector__XXX
 SG_ DAS_Planner_c2 m46 : 48|8@1+ (2E-05,-0.0025) [-0.0025|0.0025] "m-1" Vector__XXX
 SG_ DAS_Planner_c3 m46 : 56|8@1+ (2.4E-07,-3E-05) [-3E-05|3E-05] "m-2" Vector__XXX
 SG_ DAS_csa_accel_max m47 : 8|8@1+ (0.08,-10.24) [-10.24|10] "m/s^2" Vector__XXX
 SG_ DAS_csa_predictedLatAccel m47 : 16|8@1+ (0.08,-10.24) [-10.24|10] "m/s^2" Vector__XXX
 SG_ DAS_csa_filteredCurvature m47 : 24|16@1- (1E-06,0) [-0.032768|0.032767] "1/m" Vector__XXX
 SG_ DAS_csa_desiredVelPred m47 : 40|8@1+ (0.29,15) [15|88.95] "MPH" Vector__XXX
 SG_ DAS_csa_measuredLatAccel m47 : 48|8@1+ (0.08,-10.24) [-10.24|10] "m/s^2" Vector__XXX
 SG_ DAS_csa_desiredVelMeas m47 : 56|8@1+ (0.29,15) [15|88.95] "MPH" Vector__XXX
 SG_ DAS_csa_internal_state m48 : 8|4@1+ (1,0) [0|7] "" Vector__XXX
 SG_ DAS_pp_lanechange_fwdObst m48 : 12|1@1+ (1,0) [0|1] "" Vector__XXX
 SG_ DAS_pp_lanechange_inputsValid m48 : 13|1@1+ (1,0) [0|1] "" Vector__XXX
 SG_ DAS_pp_lanechange_side m48 : 14|2@1+ (1,0) [0|1] "" Vector__XXX
 SG_ DAS_pp_laneChange_destLanesValid m48 : 16|1@1+ (1,0) [0|1] "" Vector__XXX
 SG_ DAS_pp_laneChange_egoLaneValid m48 : 17|1@1+ (1,0) [0|1] "" Vector__XXX
 SG_ DAS_pp_laneChange_anyObstacle m48 : 18|1@1+ (1,0) [0|1] "" Vector__XXX
 SG_ DAS_pp_laneChange_closeObstacle m48 : 19|1@1+ (1,0) [0|1] "" Vector__XXX
 SG_ DAS_pp_laneChange_LC_healthy m48 : 20|1@1+ (1,0) [0|1] "" Vector__XXX
 SG_ DAS_pp_laneChange_blinkerCheck m48 : 21|1@1+ (1,0) [0|1] "" Vector__XXX
 SG_ DAS_torque_filt_0p05Hz m48 : 22|12@1+ (0.01,-20.5) [-20.5|20.45] "Nm" Vector__XXX
 SG_ DAS_csa_using_offramp m48 : 34|1@1+ (1,0) [0|1] "" Vector__XXX
 SG_ DAS_csa_using_frozen_offramp m48 : 35|1@1+ (1,0) [0|1] "" Vector__XXX
 SG_ DAS_csa_mpp_jumped_up m48 : 36|1@1+ (1,0) [0|1] "" Vector__XXX
 SG_ DAS_csa_mpp_jump_up_distance m48 : 37|8@1+ (10,0) [0|2550] "m" Vector__XXX
 SG_ DAS_csa_offramp_usage_duration m48 : 45|8@1+ (256,0) [0|65535] "" Vector__XXX
 SG_ DAS_pp_laneChange_freesp_avail_l m48 : 61|1@1+ (1,0) [0|1] "" Vector__XXX
 SG_ DAS_pp_laneChange_freesp_avail_r m48 : 62|1@1+ (1,0) [0|1] "" Vector__XXX
 SG_ DAS_pp_offset_objectStateLeft m49 : 16|3@1+ (1,0) [0|7] "" Vector__XXX
 SG_ DAS_pp_offset_objectStateRight m49 : 19|3@1+ (1,0) [0|7] "" Vector__XXX
 SG_ DAS_pp_offset_activeLeft m49 : 22|1@1+ (1,0) [0|1] "" Vector__XXX
 SG_ DAS_pp_offset_activeRight m49 : 23|1@1+ (1,0) [0|1] "" Vector__XXX
 SG_ DAS_pp_offset_offsetObjectLeft m49 : 24|8@1- (0.01,0) [-1.28|1.27] "m" Vector__XXX
 SG_ DAS_pp_offset_offsetObjectRight m49 : 32|8@1- (0.01,0) [-1.28|1.27] "m" Vector__XXX
 SG_ DAS_pp_offset_objDurationLeft m49 : 40|8@1+ (4,0) [0|1000] "s" Vector__XXX
 SG_ DAS_pp_offset_objDurationRight m49 : 48|8@1+ (4,0) [0|1000] "s" Vector__XXX
 SG_ DAS_VL_HPP_rejectCounter m50 : 8|1@1+ (1,0) [0|1] "" Vector__XXX
 SG_ DAS_VL_leftFsParallelLeftLane m50 : 13|1@1+ (1,0) [0|1] "" Vector__XXX
 SG_ DAS_VL_leftFsParallelRightLane m50 : 14|1@1+ (1,0) [0|1] "" Vector__XXX
 SG_ DAS_VL_rightFsParallelLeftLane m50 : 15|1@1+ (1,0) [0|1] "" Vector__XXX
 SG_ DAS_VL_rightFsParallelRightLane m50 : 16|1@1+ (1,0) [0|1] "" Vector__XXX
 SG_ DAS_VL_LL_quality m50 : 17|1@1+ (1,0) [0|1] "" Vector__XXX
 SG_ DAS_VL_RL_quality m50 : 18|1@1+ (1,0) [0|1] "" Vector__XXX
 SG_ DAS_VL_HPP_quality m50 : 19|1@1+ (1,0) [0|1] "" Vector__XXX
 SG_ DAS_VL_NAV_quality m50 : 20|1@1+ (1,0) [0|1] "" Vector__XXX
 SG_ DAS_VL_V1_quality m50 : 21|1@1+ (1,0) [0|1] "" Vector__XXX
 SG_ DAS_VL_WidthMeasType m50 : 22|3@1+ (1,0) [0|1] "" Vector__XXX
 SG_ DAS_VL_Reinitialized m50 : 25|1@1+ (1,0) [0|1] "" Vector__XXX
 SG_ DAS_VL_LL_rejectQuality m50 : 26|1@1+ (1,0) [0|1] "" Vector__XXX
 SG_ DAS_VL_LL_rejectType m50 : 27|1@1+ (1,0) [0|1] "" Vector__XXX
 SG_ DAS_VL_LL_rejectRange m50 : 28|1@1+ (1,0) [0|1] "" Vector__XXX
 SG_ DAS_VL_LL_rejectFreespace m50 : 29|1@1+ (1,0) [0|1] "" Vector__XXX
 SG_ DAS_VL_LL_rejectDyingLine m50 : 30|1@1+ (1,0) [0|1] "" Vector__XXX
 SG_ DAS_VL_LL_rejectLatDiffAtCP m50 : 31|1@1+ (1,0) [0|1] "" Vector__XXX
 SG_ DAS_VL_LL_rejectPrediction m50 : 32|1@1+ (1,0) [0|1] "" Vector__XXX
 SG_ DAS_VL_LL_rejectHWExit m50 : 33|1@1+ (1,0) [0|1] "" Vector__XXX
 SG_ DAS_VL_LL_rejectCounter m50 : 34|1@1+ (1,0) [0|1] "" Vector__XXX
 SG_ DAS_VL_RL_rejectQuality m50 : 35|1@1+ (1,0) [0|1] "" Vector__XXX
 SG_ DAS_VL_RL_rejectType m50 : 36|1@1+ (1,0) [0|1] "" Vector__XXX
 SG_ DAS_VL_RL_rejectRange m50 : 37|1@1+ (1,0) [0|1] "" Vector__XXX
 SG_ DAS_VL_RL_rejectFreespace m50 : 38|1@1+ (1,0) [0|1] "" Vector__XXX
 SG_ DAS_VL_RL_rejectDyingLine m50 : 39|1@1+ (1,0) [0|1] "" Vector__XXX
 SG_ DAS_VL_RL_rejectLatDiffAtCP m50 : 40|1@1+ (1,0) [0|1] "" Vector__XXX
 SG_ DAS_VL_RL_rejectPrediction m50 : 41|1@1+ (1,0) [0|1] "" Vector__XXX
 SG_ DAS_VL_RL_rejectHWExit m50 : 42|1@1+ (1,0) [0|1] "" Vector__XXX
 SG_ DAS_VL_RL_rejectCounter m50 : 43|1@1+ (1,0) [0|1] "" Vector__XXX
 SG_ DAS_VL_HPP_rejectError m50 : 44|1@1+ (1,0) [0|1] "" Vector__XXX
 SG_ DAS_VL_HPP_rejectRange m50 : 45|1@1+ (1,0) [0|1] "" Vector__XXX
 SG_ DAS_VL_HPP_rejectWiper m50 : 46|1@1+ (1,0) [0|1] "" Vector__XXX
 SG_ DAS_VL_HPP_rejectNight m50 : 47|1@1+ (1,0) [0|1] "" Vector__XXX
 SG_ DAS_VL_HPP_rejectCipvClose m50 : 48|1@1+ (1,0) [0|1] "" Vector__XXX
 SG_ DAS_VL_NAV_rejectHealth m50 : 49|1@1+ (1,0) [0|1] "" Vector__XXX
 SG_ DAS_VL_NAV_rejectAge m50 : 50|1@1+ (1,0) [0|1] "" Vector__XXX
 SG_ DAS_VL_NAV_rejectCounter m50 : 51|1@1+ (1,0) [0|1] "" Vector__XXX
 SG_ DAS_VL_V2_quality m50 : 52|1@1+ (1,0) [0|1] "" Vector__XXX
 SG_ DAS_VL_V3_quality m50 : 53|1@1+ (1,0) [0|1] "" Vector__XXX
 SG_ DAS_VL_V4_quality m50 : 54|1@1+ (1,0) [0|1] "" Vector__XXX
 SG_ DAS_VL_V5_quality m50 : 55|1@1+ (1,0) [0|1] "" Vector__XXX
 SG_ DAS_VL_Mode m50 : 56|4@1+ (1,0) [0|15] "" Vector__XXX
 SG_ DAS_VL_LinePreference m50 : 60|3@1+ (1,0) [0|7] "" Vector__XXX
 SG_ DAS_VL_M_LL_crossCheck m51 : 8|1@1+ (1,0) [0|1] "" Vector__XXX
 SG_ DAS_VL_M_RL_crossCheck m51 : 9|1@1+ (1,0) [0|1] "" Vector__XXX
 SG_ DAS_VL_M_HPP_crossCheck m51 : 10|1@1+ (1,0) [0|1] "" Vector__XXX
 SG_ DAS_VL_M_NAV_crossCheck m51 : 11|1@1+ (1,0) [0|1] "" Vector__XXX
 SG_ DAS_VL_M_V1_crossCheck m51 : 12|1@1+ (1,0) [0|1] "" Vector__XXX
 SG_ DAS_VL_M_V2_crossCheck m51 : 13|1@1+ (1,0) [0|1] "" Vector__XXX
 SG_ DAS_VL_M_V3_crossCheck m51 : 14|1@1+ (1,0) [0|1] "" Vector__XXX
 SG_ DAS_VL_M_V4_crossCheck m51 : 15|1@1+ (1,0) [0|1] "" Vector__XXX
 SG_ DAS_VL_M_V5_crossCheck m51 : 16|1@1+ (1,0) [0|1] "" Vector__XXX
 SG_ DAS_VL_LL_RL_crossCheck m51 : 17|1@1+ (1,0) [0|1] "" Vector__XXX
 SG_ DAS_VL_LL_HPP_crossCheck m51 : 18|1@1+ (1,0) [0|1] "" Vector__XXX
 SG_ DAS_VL_LL_NAV_crossCheck m51 : 19|1@1+ (1,0) [0|1] "" Vector__XXX
 SG_ DAS_VL_LL_V1_crossCheck m51 : 20|1@1+ (1,0) [0|1] "" Vector__XXX
 SG_ DAS_VL_LL_V2_crossCheck m51 : 21|1@1+ (1,0) [0|1] "" Vector__XXX
 SG_ DAS_VL_LL_V3_crossCheck m51 : 22|1@1+ (1,0) [0|1] "" Vector__XXX
 SG_ DAS_VL_LL_V4_crossCheck m51 : 23|1@1+ (1,0) [0|1] "" Vector__XXX
 SG_ DAS_VL_LL_V5_crossCheck m51 : 24|1@1+ (1,0) [0|1] "" Vector__XXX
 SG_ DAS_VL_RL_HPP_crossCheck m51 : 25|1@1+ (1,0) [0|1] "" Vector__XXX
 SG_ DAS_VL_RL_NAV_crossCheck m51 : 26|1@1+ (1,0) [0|1] "" Vector__XXX
 SG_ DAS_VL_RL_V1_crossCheck m51 : 27|1@1+ (1,0) [0|1] "" Vector__XXX
 SG_ DAS_VL_RL_V2_crossCheck m51 : 28|1@1+ (1,0) [0|1] "" Vector__XXX
 SG_ DAS_VL_RL_V3_crossCheck m51 : 29|1@1+ (1,0) [0|1] "" Vector__XXX
 SG_ DAS_VL_RL_V4_crossCheck m51 : 30|1@1+ (1,0) [0|1] "" Vector__XXX
 SG_ DAS_VL_RL_V5_crossCheck m51 : 31|1@1+ (1,0) [0|1] "" Vector__XXX
 SG_ DAS_VL_HPP_NAV_crossCheck m51 : 32|1@1+ (1,0) [0|1] "" Vector__XXX
 SG_ DAS_VL_HPP_V1_crossCheck m51 : 33|1@1+ (1,0) [0|1] "" Vector__XXX
 SG_ DAS_VL_HPP_V2_crossCheck m51 : 34|1@1+ (1,0) [0|1] "" Vector__XXX
 SG_ DAS_VL_HPP_V3_crossCheck m51 : 35|1@1+ (1,0) [0|1] "" Vector__XXX
 SG_ DAS_VL_HPP_V4_crossCheck m51 : 36|1@1+ (1,0) [0|1] "" Vector__XXX
 SG_ DAS_VL_HPP_V5_crossCheck m51 : 37|1@1+ (1,0) [0|1] "" Vector__XXX
 SG_ DAS_VL_NAV_V1_crossCheck m51 : 38|1@1+ (1,0) [0|1] "" Vector__XXX
 SG_ DAS_VL_NAV_V2_crossCheck m51 : 39|1@1+ (1,0) [0|1] "" Vector__XXX
 SG_ DAS_VL_NAV_V3_crossCheck m51 : 40|1@1+ (1,0) [0|1] "" Vector__XXX
 SG_ DAS_VL_NAV_V4_crossCheck m51 : 41|1@1+ (1,0) [0|1] "" Vector__XXX
 SG_ DAS_VL_NAV_V5_crossCheck m51 : 42|1@1+ (1,0) [0|1] "" Vector__XXX
 SG_ DAS_VL_V1_V2_crossCheck m51 : 43|1@1+ (1,0) [0|1] "" Vector__XXX
 SG_ DAS_VL_V1_V3_crossCheck m51 : 44|1@1+ (1,0) [0|1] "" Vector__XXX
 SG_ DAS_VL_V1_V4_crossCheck m51 : 45|1@1+ (1,0) [0|1] "" Vector__XXX
 SG_ DAS_VL_V1_V5_crossCheck m51 : 46|1@1+ (1,0) [0|1] "" Vector__XXX
 SG_ DAS_VL_V2_V3_crossCheck m51 : 47|1@1+ (1,0) [0|1] "" Vector__XXX
 SG_ DAS_VL_V2_V4_crossCheck m51 : 48|1@1+ (1,0) [0|1] "" Vector__XXX
 SG_ DAS_VL_V2_V5_crossCheck m51 : 49|1@1+ (1,0) [0|1] "" Vector__XXX
 SG_ DAS_VL_V3_V4_crossCheck m51 : 50|1@1+ (1,0) [0|1] "" Vector__XXX
 SG_ DAS_VL_V3_V5_crossCheck m51 : 51|1@1+ (1,0) [0|1] "" Vector__XXX
 SG_ DAS_VL_V4_V5_crossCheck m51 : 52|1@1+ (1,0) [0|1] "" Vector__XXX
 SG_ DAS_VL_LL_fuse m51 : 53|1@1+ (1,0) [0|1] "" Vector__XXX
 SG_ DAS_VL_RL_fuse m51 : 54|1@1+ (1,0) [0|1] "" Vector__XXX
 SG_ DAS_VL_HPP_fuse m51 : 55|1@1+ (1,0) [0|1] "" Vector__XXX
 SG_ DAS_VL_NAV_fuse m51 : 56|1@1+ (1,0) [0|1] "" Vector__XXX
 SG_ DAS_VL_V1_fuse m51 : 57|1@1+ (1,0) [0|1] "" Vector__XXX
 SG_ DAS_VL_V2_fuse m51 : 58|1@1+ (1,0) [0|1] "" Vector__XXX
 SG_ DAS_VL_V3_fuse m51 : 59|1@1+ (1,0) [0|1] "" Vector__XXX
 SG_ DAS_VL_V4_fuse m51 : 60|1@1+ (1,0) [0|1] "" Vector__XXX
 SG_ DAS_VL_V5_fuse m51 : 61|1@1+ (1,0) [0|1] "" Vector__XXX
 SG_ DAS_VL_egoLaneChange m51 : 62|2@1+ (1,0) [0|2] "" Vector__XXX
 SG_ DAS_VL_exitChecks_EGO_LNE_LEFT m52 : 8|1@1+ (1,0) [0|1] "" Vector__XXX
 SG_ DAS_VL_exitChecks_EGO_LNE_RGHT m52 : 9|1@1+ (1,0) [0|1] "" Vector__XXX
 SG_ DAS_VL_exitChecks_BLINKER_LEFT m52 : 10|1@1+ (1,0) [0|1] "" Vector__XXX
 SG_ DAS_VL_exitChecks_BLINKER_RGHT m52 : 11|1@1+ (1,0) [0|1] "" Vector__XXX
 SG_ DAS_autoWipersNetwork m60 : 8|16@1+ (0.01,0) [0|1] "%" Vector__XXX
 SG_ DAS_autoWipersPerMinute m60 : 24|8@1+ (1,0) [0|100] "" Vector__XXX
 SG_ DAS_autoWipersValid m60 : 32|1@1+ (1,0) [0|1] "" Vector__XXX
 SG_ DAS_SYNC_EyeQGlobalFrameNum m100 : 15|32@0+ (1,0) [0|4294967296] "" Vector__XXX
 SG_ DAS_SYNC_DASLocalTimeStamp m100 : 47|24@0+ (1,0) [0|16777216] "" Vector__XXX

BO_ 1641 DAS_dtcMatrix: 8 DAS
 SG_ DAS_dtcMultiplex M : 0|8@1+ (1,0) [0|255] "" GTW
 SG_ DAS_d001_unused m0 : 8|2@1+ (1,0) [0|0] "" GTW

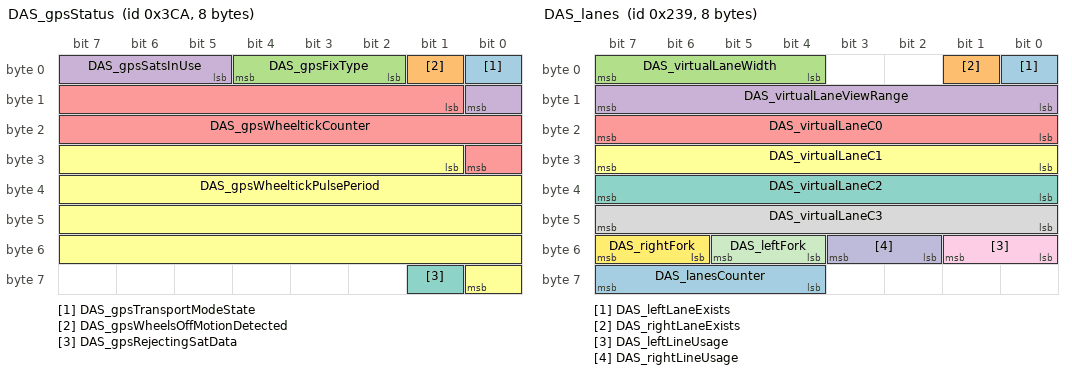
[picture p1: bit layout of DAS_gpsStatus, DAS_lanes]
BO_ 970 DAS_gpsStatus: 8 DAS
 SG_ DAS_gpsTransportModeState : 0|1@1+ (1,0) [0|1] "" GTW
 SG_ DAS_gpsWheelsOffMotionDetected : 1|1@1+ (1,0) [0|1] "" GTW
 SG_ DAS_gpsFixType : 2|3@1+ (1,0) [0|6] "" GTW
 SG_ DAS_gpsSatsInUse : 5|4@1+ (1,0) [0|12] "" GTW
 SG_ DAS_gpsWheeltickCounter : 9|16@1+ (1,0) [0|65535] "" GTW
 SG_ DAS_gpsWheeltickPulsePeriod : 25|32@1+ (1,0) [0|4294967295] "" GTW
 SG_ DAS_gpsRejectingSatData : 57|1@1+ (1,0) [0|1] "" GTW

BO_ 1337 DAS_info: 8 DAS
 SG_ DAS_infoIndex M : 0|8@1+ (1,0) [0|0] "" GTW,GTWU
 SG_ DAS_infoBuildType m10 : 8|8@1+ (1,0) [0|0] "" GTW
 SG_ DAS_infoBuildConfigID m10 : 16|16@1+ (1,0) [0|0] "" GTW
 SG_ DAS_infoHardwareID m10 : 32|16@1+ (1,0) [0|0] "" GTW
 SG_ DAS_infoComponentID m10 : 48|16@1+ (1,0) [0|0] "" GTW
 SG_ DAS_infoPcbaID m11 : 16|8@1+ (1,0) [0|0] "" GTW,GTWU
 SG_ DAS_infoAssemblyID m11 : 24|8@1+ (1,0) [0|255] "" GTW,GTWU
 SG_ DAS_infoUsageID m11 : 32|16@1+ (1,0) [0|65535] "" GTW,GTWU
 SG_ DAS_infoSubUsageID m11 : 48|16@1+ (1,0) [0|65535] "" GTW
 SG_ DAS_infoApplicationCRC m13 : 32|32@1+ (1,0) [0|0] "" GTW,GTWU
 SG_ DAS_infoBootloaderSvnRevision m14 : 8|24@1+ (1,0) [0|0] "" GTW
 SG_ DAS_infoEyeQBootCRC m16 : 16|32@1+ (1,0) [0|0] "" GTW,GTWU
 SG_ DAS_infoAppGitHashBytes m17 : 8|56@1+ (1,0) [0|0] "" GTW
 SG_ DAS_infoBootGitHashBytes m18 : 8|56@1+ (1,0) [0|0] "" GTW
 SG_ DAS_infoPlatformType m19 : 8|8@1+ (1,0) [0|0] "" GTW
 SG_ DAS_infoMajorVersion m19 : 16|8@1+ (1,0) [0|0] "" GTW
 SG_ DAS_infoBranchOrigin m19 : 24|8@1+ (1,0) [0|0] "" GTW
 SG_ DAS_infoMaturity m19 : 32|8@1+ (1,0) [0|0] "" GTW
 SG_ DAS_infoHardwareRevision m19 : 40|8@1+ (1,0) [0|0] "" GTW
 SG_ DAS_infoBootUdsProtoVersion m20 : 8|8@1+ (1,0) [0|0] "" GTW,GTWU
 SG_ DAS_infoBootloaderCRC m20 : 32|32@1+ (1,0) [0|0] "" GTW
 SG_ DAS_infoEyeQAppCRC m23 : 16|32@1+ (1,0) [0|0] "" GTW,GTWU
 SG_ DAS_infoEyeQFfsCRC m24 : 16|32@1+ (1,0) [0|0] "" GTW,GTWU

BO_ 665 DAS_integratedSafetyFront: 8 DAS
 SG_ DAS_safetyFrontChecksum : 0|8@1+ (1,0) [0|255] "" APS,RCM
 SG_ DAS_safetyFrontCounter : 8|4@1+ (1,0) [0|15] "" APS,RCM
 SG_ DAS_timeToImpactFront : 12|9@1+ (1,0) [0|511] "ms" APS,RCM
 SG_ DAS_timeToImpactFrontQF : 21|1@1+ (1,0) [0|1] "" APS,RCM
 SG_ DAS_predictedImpactVelFront : 22|7@1+ (0.5,0) [0|63] "m/s" APS,RCM
 SG_ DAS_predictedImpactVelFrontQF : 29|1@1+ (1,0) [0|1] "" APS,RCM
 SG_ DAS_relativeVelocityFront : 30|6@1+ (1,-32) [-32|31] "m/s" APS,RCM
 SG_ DAS_relativeVelocityFrontQF : 36|1@1+ (1,0) [0|1] "" APS,RCM
 SG_ DAS_targetDistanceFront : 37|7@1+ (0.1,0) [0|12.7] "m" APS,RCM
 SG_ DAS_targetDistanceFrontQF : 44|1@1+ (1,0) [0|1] "" APS,RCM
 SG_ DAS_relativeAccelerationFront : 45|8@1+ (0.1,-12.8) [-12.8|12.7] "m/s^2" APS,RCM
 SG_ DAS_relativeAccelerationFrontQF : 53|1@1+ (1,0) [0|1] "" APS,RCM
 SG_ DAS_imminentCollisionFront : 54|1@1+ (1,0) [0|1] "" APS,RCM
 SG_ DAS_imminentCollisionFrontQF : 55|1@1+ (1,0) [0|1] "" APS,RCM
 SG_ DAS_predictedImpactOvrlapFront : 56|3@1+ (12.5,0) [0|100] "%" APS,RCM
 SG_ DAS_predictedImpactOvrlapFrontQF : 59|1@1+ (1,0) [0|1] "" APS,RCM
 SG_ DAS_idfEnableFlag : 60|1@1+ (1,0) [0|1] "" APS,RCM

BO_ 569 DAS_lanes: 8 DAS
 SG_ DAS_leftLaneExists : 0|1@1+ (1,0) [0|0] "" GTW,APS
 SG_ DAS_rightLaneExists : 1|1@1+ (1,0) [0|0] "" GTW,APS
 SG_ DAS_virtualLaneWidth : 4|4@1+ (0.3125,2) [2|7] "m" GTW,APS
 SG_ DAS_virtualLaneViewRange : 8|8@1+ (1,0) [0|160] "m" GTW,APS
 SG_ DAS_virtualLaneC0 : 16|8@1+ (0.035,-3.5) [-3.5|3.5] "m" GTW,APS
 SG_ DAS_virtualLaneC1 : 24|8@1+ (0.0016,-0.2) [-0.2|0.2] "rad" GTW,APS
 SG_ DAS_virtualLaneC2 : 32|8@1+ (2E-05,-0.0025) [-0.0025|0.0025] "m-1" GTW,APS
 SG_ DAS_virtualLaneC3 : 40|8@1+ (2.4E-07,-3E-05) [-3E-05|3E-05] "m-2" GTW,APS
 SG_ DAS_leftLineUsage : 48|2@1+ (1,0) [0|3] "" GTW,APS
 SG_ DAS_rightLineUsage : 50|2@1+ (1,0) [0|3] "" GTW,APS
 SG_ DAS_leftFork : 52|2@1+ (1,0) [0|3] "" GTW,APS
 SG_ DAS_rightFork : 54|2@1+ (1,0) [0|3] "" GTW,APS
 SG_ DAS_lanesCounter : 60|4@1+ (1,0) [0|0] "" GTW,APS

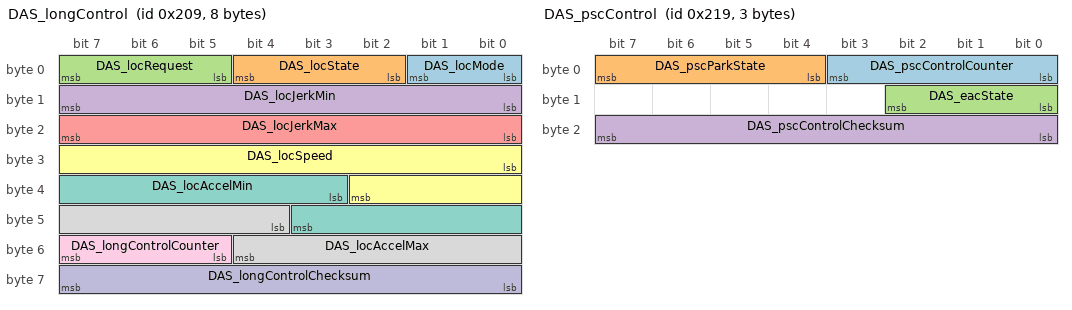
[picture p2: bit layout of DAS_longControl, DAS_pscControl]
BO_ 521 DAS_longControl: 8 DAS
 SG_ DAS_locMode : 0|2@1+ (1,0) [0|0] "" GTW
 SG_ DAS_locState : 2|3@1+ (1,0) [0|0] "" GTW
 SG_ DAS_locRequest : 5|3@1+ (1,0) [0|0] "" GTW
 SG_ DAS_locJerkMin : 8|8@1+ (0.034,-8.67) [-8.67|0] "m/s^3" GTW
 SG_ DAS_locJerkMax : 16|8@1+ (0.034,0) [0|8.67] "m/s^3" GTW
 SG_ DAS_locSpeed : 24|11@1+ (0.1,0) [0|204.7] "kph" GTW
 SG_ DAS_locAccelMin : 35|9@1+ (0.04,-15) [-15|5.44] "m/s^2" GTW
 SG_ DAS_locAccelMax : 44|9@1+ (0.04,-15) [-15|5.44] "m/s^2" GTW
 SG_ DAS_longControlCounter : 53|3@1+ (1,0) [0|0] "" GTW
 SG_ DAS_longControlChecksum : 56|8@1+ (1,0) [0|0] "" GTW

BO_ 777 DAS_object: 8 DAS
 SG_ DAS_objectId M : 0|3@1+ (1,0) [0|7] "" GTW,APS
 SG_ DAS_leadVehType m0 : 3|3@1+ (1,0) [0|7] "" GTW,APS
 SG_ DAS_leadVehRelevantForControl m0 : 7|1@1+ (1,0) [0|1] "" GTW,APS
 SG_ DAS_leadVehDx m0 : 8|8@1+ (0.5,0) [0|127] "m" GTW,APS
 SG_ DAS_leadVehVxRel m0 : 16|4@1+ (4,-30) [-30|26] "m/s" GTW,APS
 SG_ DAS_leadVehDy m0 : 20|7@1+ (0.35,-22.05) [-22.05|22.4] "m" GTW,APS
 SG_ DAS_leadVehId m0 : 27|7@1+ (1,0) [0|126] "" GTW,APS
 SG_ DAS_leadVeh2Type m0 : 34|3@1+ (1,0) [0|7] "" GTW,APS
 SG_ DAS_leadVeh2RelevantForControl m0 : 38|1@1+ (1,0) [0|1] "" GTW,APS
 SG_ DAS_leadVeh2Dx m0 : 39|8@1+ (0.5,0) [0|127] "m" GTW,APS
 SG_ DAS_leadVeh2VxRel m0 : 47|4@1+ (4,-30) [-30|26] "m/s" GTW,APS
 SG_ DAS_leadVeh2Dy m0 : 51|7@1+ (0.35,-22.05) [-22.05|22.4] "m" GTW,APS
 SG_ DAS_leadVeh2Id m0 : 58|6@1+ (1,0) [0|63] "" GTW,APS
 SG_ DAS_leftVehType m1 : 3|3@1+ (1,0) [0|7] "" GTW,APS
 SG_ DAS_leftVehRelevantForControl m1 : 7|1@1+ (1,0) [0|1] "" GTW,APS
 SG_ DAS_leftVehDx m1 : 8|8@1+ (0.5,0) [0|127] "m" GTW
 SG_ DAS_leftVehVxRel m1 : 16|4@1+ (4,-30) [-30|26] "m/s" GTW
 SG_ DAS_leftVehDy m1 : 20|7@1+ (0.35,-22.05) [-22.05|22.4] "m" GTW,APS
 SG_ DAS_leftVehId m1 : 27|7@1+ (1,0) [0|126] "" GTW,APS
 SG_ DAS_leftVeh2Type m1 : 34|3@1+ (1,0) [0|7] "" GTW,APS
 SG_ DAS_leftVeh2RelevantForControl m1 : 38|1@1+ (1,0) [0|1] "" GTW,APS
 SG_ DAS_leftVeh2Dx m1 : 39|8@1+ (0.5,0) [0|127] "m" GTW
 SG_ DAS_leftVeh2VxRel m1 : 47|4@1+ (4,-30) [-30|26] "m/s" GTW
 SG_ DAS_leftVeh2Dy m1 : 51|7@1+ (0.35,-22.05) [-22.05|22.4] "m" GTW,APS
 SG_ DAS_leftVeh2Id m1 : 58|6@1+ (1,0) [0|63] "" GTW,APS
 SG_ DAS_rightVehType m2 : 3|3@1+ (1,0) [0|7] "" GTW,APS
 SG_ DAS_rightVehRelevantForControl m2 : 7|1@1+ (1,0) [0|1] "" GTW,APS
 SG_ DAS_rightVehDx m2 : 8|8@1+ (0.5,0) [0|127] "m" GTW
 SG_ DAS_rightVehVxRel m2 : 16|4@1+ (4,-30) [-30|26] "m/s" GTW
 SG_ DAS_rightVehDy m2 : 20|7@1+ (0.35,-22.05) [-22.05|22.4] "m" GTW,APS
 SG_ DAS_rightVehId m2 : 27|7@1+ (1,0) [0|126] "" GTW,APS
 SG_ DAS_rightVeh2Type m2 : 34|3@1+ (1,0) [0|7] "" GTW,APS
 SG_ DAS_rightVeh2RelevantForControl m2 : 38|1@1+ (1,0) [0|1] "" GTW,APS
 SG_ DAS_rightVeh2Dx m2 : 39|8@1+ (0.5,0) [0|127] "m" GTW
 SG_ DAS_rightVeh2VxRel m2 : 47|4@1+ (4,-30) [-30|26] "m/s" GTW
 SG_ DAS_rightVeh2Dy m2 : 51|7@1+ (0.35,-22.05) [-22.05|22.4] "m" GTW,APS
 SG_ DAS_rightVeh2Id m2 : 58|6@1+ (1,0) [0|63] "" GTW,APS
 SG_ DAS_cutinVehType m3 : 3|3@1+ (1,0) [0|7] "" GTW,APS
 SG_ DAS_cutinVehRelevantForControl m3 : 7|1@1+ (1,0) [0|1] "" GTW,APS
 SG_ DAS_cutinVehDx m3 : 8|8@1+ (0.5,0) [0|127] "m" GTW
 SG_ DAS_cutinVehVxRel m3 : 16|4@1+ (4,-30) [-30|26] "m/s" GTW
 SG_ DAS_cutinVehDy m3 : 20|7@1+ (0.35,-22.05) [-22.05|22.4] "m" GTW,APS
 SG_ DAS_cutinVehId m3 : 27|7@1+ (1,0) [0|126] "" GTW,APS
 SG_ DAS_roadSignColor m4 : 3|3@1+ (1,0) [0|7] "" GTW,APS
 SG_ DAS_roadSignId m4 : 6|8@1+ (1,0) [0|0] "" GTW,APS
 SG_ DAS_roadSignStopLineDist m4 : 14|10@1+ (0.2,-20) [-20|184.4] "m" GTW,APS
 SG_ DAS_roadSignControlActive m4 : 24|1@1+ (1,0) [0|1] "" GTW,APS
 SG_ DAS_roadSignSource m4 : 25|2@1+ (1,0) [0|3] "" GTW,APS
 SG_ DAS_roadSignArrow m4 : 27|3@1+ (1,0) [0|7] "" GTW,APS
 SG_ DAS_roadSignOrientation m4 : 30|2@1+ (1,0) [0|1] "" GTW,APS
 SG_ DAS_leadVehHeading m5 : 8|8@1+ (0.0245437,-3.1415936) [-3.1415936|3.0925062] "rad" GTW,APS
 SG_ DAS_leadVeh2Heading m5 : 16|8@1+ (0.0245437,-3.1415936) [-3.1415936|3.0925062] "rad" GTW,APS
 SG_ DAS_leftVehHeading m5 : 24|8@1+ (0.0245437,-3.1415936) [-3.1415936|3.0925062] "rad" GTW,APS
 SG_ DAS_leftVeh2Heading m5 : 32|8@1+ (0.0245437,-3.1415936) [-3.1415936|3.0925062] "rad" GTW,APS
 SG_ DAS_rightVehHeading m5 : 40|8@1+ (0.0245437,-3.1415936) [-3.1415936|3.0925062] "rad" GTW,APS
 SG_ DAS_rightVeh2Heading m5 : 48|8@1+ (0.0245437,-3.1415936) [-3.1415936|3.0925062] "rad" GTW,APS
 SG_ DAS_cutinVehHeading m5 : 56|8@1+ (0.0245437,-3.1415936) [-3.1415936|3.0925062] "rad" GTW,APS

BO_ 537 DAS_pscControl: 3 DAS
 SG_ DAS_pscControlCounter : 0|4@1+ (1,0) [0|15] "" PARK,APS
 SG_ DAS_pscParkState : 4|4@1+ (1,0) [0|15] "" PARK,EPB,APS
 SG_ DAS_eacState : 8|3@1+ (1,0) [0|3] "" PARK,APS
 SG_ DAS_pscControlChecksum : 16|8@1+ (1,0) [0|255] "" PARK,APS

BO_ 1024 DAS_robDebug: 8 DAS
 SG_ DAS_robDebugMultiplexer M : 0|4@1+ (1,0) [0|15] "" Vector__XXX
 SG_ DAS_eObj00Valid m0 : 4|1@1+ (1,0) [0|1] "" Vector__XXX
 SG_ DAS_eObj00Age m0 : 5|3@1+ (1,0) [0|7] "" Vector__XXX
 SG_ DAS_eObj00PositionX m0 : 8|8@1+ (0.5,0) [0|127.5] "m" Vector__XXX
 SG_ DAS_eObj00PositionY m0 : 16|8@1+ (0.25,-31.875) [-31.875|31.85] "m" Vector__XXX
 SG_ DAS_eObj00Moment0 m0 : 24|8@1+ (0.25,-31.875) [-31.875|31.85] "m" Vector__XXX
 SG_ DAS_eObj00Moment1 m0 : 32|8@1+ (0.25,-31.875) [-31.875|31.85] "m" Vector__XXX
 SG_ DAS_eObj00Moment2 m0 : 40|8@1+ (0.25,-31.875) [-31.875|31.85] "m" Vector__XXX
 SG_ DAS_eObj00Moment3 m0 : 48|8@1+ (0.25,-31.875) [-31.875|31.85] "m" Vector__XXX
 SG_ DAS_eObj00InPath m0 : 56|1@1+ (1,0) [0|1] "" Vector__XXX
 SG_ DAS_eObj00Blacklist m0 : 57|1@1+ (1,0) [0|1] "" Vector__XXX
 SG_ DAS_eObj00Elevated m0 : 58|1@1+ (1,0) [0|1] "" Vector__XXX
 SG_ DAS_eObj01Valid m1 : 4|1@1+ (1,0) [0|1] "" Vector__XXX
 SG_ DAS_eObj01Age m1 : 5|3@1+ (1,0) [0|7] "" Vector__XXX
 SG_ DAS_eObj01PositionX m1 : 8|8@1+ (0.5,0) [0|127.5] "m" Vector__XXX
 SG_ DAS_eObj01PositionY m1 : 16|8@1+ (0.25,-31.875) [-31.875|31.85] "m" Vector__XXX
 SG_ DAS_eObj01Moment0 m1 : 24|8@1+ (0.25,-31.875) [-31.875|31.85] "m" Vector__XXX
 SG_ DAS_eObj01Moment1 m1 : 32|8@1+ (0.25,-31.875) [-31.875|31.85] "m" Vector__XXX
 SG_ DAS_eObj01Moment2 m1 : 40|8@1+ (0.25,-31.875) [-31.875|31.85] "m" Vector__XXX
 SG_ DAS_eObj01Moment3 m1 : 48|8@1+ (0.25,-31.875) [-31.875|31.85] "m" Vector__XXX
 SG_ DAS_eObj01InPath m1 : 56|1@1+ (1,0) [0|1] "" Vector__XXX
 SG_ DAS_eObj01Blacklist m1 : 57|1@1+ (1,0) [0|1] "" Vector__XXX
 SG_ DAS_eObj01Elevated m1 : 58|1@1+ (1,0) [0|1] "" Vector__XXX
 SG_ DAS_eObj02Valid m2 : 4|1@1+ (1,0) [0|1] "" Vector__XXX
 SG_ DAS_eObj02Age m2 : 5|3@1+ (1,0) [0|7] "" Vector__XXX
 SG_ DAS_eObj02PositionX m2 : 8|8@1+ (0.5,0) [0|127.5] "m" Vector__XXX
 SG_ DAS_eObj02PositionY m2 : 16|8@1+ (0.25,-31.875) [-31.875|31.85] "m" Vector__XXX
 SG_ DAS_eObj02Moment0 m2 : 24|8@1+ (0.25,-31.875) [-31.875|31.85] "m" Vector__XXX
 SG_ DAS_eObj02Moment1 m2 : 32|8@1+ (0.25,-31.875) [-31.875|31.85] "m" Vector__XXX
 SG_ DAS_eObj02Moment2 m2 : 40|8@1+ (0.25,-31.875) [-31.875|31.85] "m" Vector__XXX
 SG_ DAS_eObj02Moment3 m2 : 48|8@1+ (0.25,-31.875) [-31.875|31.85] "m" Vector__XXX
 SG_ DAS_eObj02InPath m2 : 56|1@1+ (1,0) [0|1] "" Vector__XXX
 SG_ DAS_eObj02Blacklist m2 : 57|1@1+ (1,0) [0|1] "" Vector__XXX
 SG_ DAS_eObj02Elevated m2 : 58|1@1+ (1,0) [0|1] "" Vector__XXX
 SG_ DAS_eObj03Valid m3 : 4|1@1+ (1,0) [0|1] "" Vector__XXX
 SG_ DAS_eObj03Age m3 : 5|3@1+ (1,0) [0|7] "" Vector__XXX
 SG_ DAS_eObj03PositionX m3 : 8|8@1+ (0.5,0) [0|127.5] "m" Vector__XXX
 SG_ DAS_eObj03PositionY m3 : 16|8@1+ (0.25,-31.875) [-31.875|31.85] "m" Vector__XXX
 SG_ DAS_eObj03Moment0 m3 : 24|8@1+ (0.25,-31.875) [-31.875|31.85] "m" Vector__XXX
 SG_ DAS_eObj03Moment1 m3 : 32|8@1+ (0.25,-31.875) [-31.875|31.85] "m" Vector__XXX
 SG_ DAS_eObj03Moment2 m3 : 40|8@1+ (0.25,-31.875) [-31.875|31.85] "m" Vector__XXX
 SG_ DAS_eObj03Moment3 m3 : 48|8@1+ (0.25,-31.875) [-31.875|31.85] "m" Vector__XXX
 SG_ DAS_eObj03InPath m3 : 56|1@1+ (1,0) [0|1] "" Vector__XXX
 SG_ DAS_eObj03Blacklist m3 : 57|1@1+ (1,0) [0|1] "" Vector__XXX
 SG_ DAS_eObj03Elevated m3 : 58|1@1+ (1,0) [0|1] "" Vector__XXX
 SG_ DAS_robPossibleCollision m4 : 8|1@1+ (1,0) [0|1] "" Vector__XXX
 SG_ DAS_robActiveBraking m4 : 9|1@1+ (1,0) [0|1] "" Vector__XXX
 SG_ DAS_robRequestEventRecorder m4 : 10|2@1+ (1,0) [0|3] "" Vector__XXX
 SG_ DAS_robInfrastructure m4 : 12|1@1+ (1,0) [0|1] "" Vector__XXX
 SG_ DAS_robAEBAlertLatch m4 : 13|1@1+ (1,0) [0|1] "" Vector__XXX
 SG_ DAS_robMapTrusted m4 : 14|1@1+ (1,0) [0|1] "" Vector__XXX
 SG_ DAS_robCollisionConf m4 : 16|4@1+ (1,0) [0|15] "" Vector__XXX
 SG_ DAS_robCriticalObjAge m4 : 20|4@1+ (1,0) [0|15] "" Vector__XXX
 SG_ DAS_robCriticalObjIndex m4 : 24|4@1+ (1,0) [0|15] "" Vector__XXX
 SG_ DAS_robDistanceObstacle m4 : 32|8@1+ (1,0) [0|255] "m" Vector__XXX
 SG_ DAS_robWidthObstacle m4 : 40|8@1+ (0.1,0) [0|25.5] "m" Vector__XXX
 SG_ DAS_robOverlapObstacle m4 : 48|8@1+ (0.1,0) [0|25.5] "m" Vector__XXX
 SG_ DAS_robTimeCollision m4 : 56|8@1+ (0.05,0) [0|12.75] "s" Vector__XXX
 SG_ DAS_robClusterStart m5 : 8|8@1+ (1,-95) [-95|160] "m" Vector__XXX
 SG_ DAS_robClusterEnd m5 : 16|8@1+ (1,0) [0|255] "m" Vector__XXX
 SG_ DAS_robMapTrust m5 : 24|1@1+ (1,0) [0|1] "" Vector__XXX
 SG_ DAS_robEnableBraking m5 : 25|1@1+ (1,0) [0|1] "" Vector__XXX
 SG_ DAS_robGPSHealthy m5 : 26|1@1+ (1,0) [0|1] "" Vector__XXX
 SG_ DAS_robRadarFault m5 : 27|1@1+ (1,0) [0|1] "" Vector__XXX
 SG_ DAS_robRadarBlind m5 : 28|1@1+ (1,0) [0|1] "" Vector__XXX
 SG_ DAS_robActiveLogging m5 : 29|1@1+ (1,0) [0|1] "" Vector__XXX

BO_ 921 DAS_status: 8 DAS
 SG_ DAS_autopilotState : 0|4@1+ (1,0) [0|0] "" GTW,APS,TAS2
 SG_ DAS_blindSpotRearLeft : 4|2@1+ (1,0) [0|0] "" GTW,APS
 SG_ DAS_blindSpotRearRight : 6|2@1+ (1,0) [0|0] "" GTW,APS
 SG_ DAS_fusedSpeedLimit : 8|5@1+ (5,0) [0|150] "kph/mph" GTW,APS
 SG_ DAS_suppressSpeedWarning : 13|1@1+ (1,0) [0|0] "" GTW,APS
 SG_ DAS_summonObstacle : 14|1@1+ (1,0) [0|0] "" GTW,APS
 SG_ DAS_summonClearedGate : 15|1@1+ (1,0) [0|0] "" GTW,APS
 SG_ DAS_visionOnlySpeedLimit : 16|5@1+ (5,0) [0|150] "kph/mph" GTW,APS
 SG_ DAS_heaterState : 21|1@1+ (1,0) [0|0] "" GTW
 SG_ DAS_forwardCollisionWarning : 22|2@1+ (1,0) [0|0] "" GTW,APS
 SG_ DAS_autoparkReady : 24|1@1+ (1,0) [0|1] "" GTW,APS
 SG_ DAS_autoParked : 25|1@1+ (1,0) [0|0] "" GTW,APS
 SG_ DAS_autoparkWaitingForBrake : 26|1@1+ (1,0) [0|1] "" GTW,APS
 SG_ DAS_summonFwdLeashReached : 27|1@1+ (1,0) [0|1] "" GTW,APS
 SG_ DAS_summonRvsLeashReached : 28|1@1+ (1,0) [0|1] "" GTW,APS
 SG_ DAS_lssState : 29|3@1+ (1,0) [0|0] "" GTW,APS,EPB
 SG_ DAS_sideCollisionAvoid : 32|2@1+ (1,0) [0|0] "" GTW,APS
 SG_ DAS_sideCollisionWarning : 34|2@1+ (1,0) [0|0] "" GTW,APS
 SG_ DAS_sideCollisionInhibit : 36|1@1+ (1,0) [0|0] "" GTW,APS
 SG_ DAS_laneDepartureWarning : 37|3@1+ (1,0) [0|0] "" GTW,APS
 SG_ DAS_fleetSpeedState : 40|2@1+ (1,0) [0|0] "" GTW,APS
 SG_ DAS_autopilotHandsOnState : 42|4@1+ (1,0) [0|0] "" GTW,APS
 SG_ DAS_autoLaneChangeState : 46|5@1+ (1,0) [0|0] "" GTW,APS
 SG_ DAS_summonAvailable : 51|1@1+ (1,0) [0|1] "" GTW,APS
 SG_ DAS_statusCounter : 52|4@1+ (1,0) [0|0] "" GTW,APS,TAS2
 SG_ DAS_statusChecksum : 56|8@1+ (1,0) [0|0] "" GTW,APS,TAS2

BO_ 905 DAS_status2: 8 DAS
 SG_ DAS_accSpeedLimit : 0|10@1+ (0.2,0) [0|204.6] "mph" GTW,APS
 SG_ DAS_pmmObstacleSeverity : 10|3@1+ (1,0) [0|7] "" GTW,APS
 SG_ DAS_pmmLoggingRequest : 13|1@1+ (1,0) [0|1] "" GTW,APS
 SG_ DAS_activationFailureStatus : 14|2@1+ (1,0) [0|1] "" GTW,APS
 SG_ DAS_pmmUltrasonicsFaultReason : 16|3@1+ (1,0) [0|7] "" GTW,APS
 SG_ DAS_pmmRadarFaultReason : 19|2@1+ (1,0) [0|3] "" GTW,APS
 SG_ DAS_pmmSysFaultReason : 21|3@1+ (1,0) [0|7] "" GTW,APS
 SG_ DAS_pmmCameraFaultReason : 24|2@1+ (1,0) [0|3] "" GTW,APS
 SG_ DAS_ACC_report : 26|5@1+ (1,0) [0|0] "" GTW,APS
 SG_ DAS_relaxCruiseLimits : 31|1@1+ (1,0) [0|0] "" GTW,APS,APP
 SG_ DAS_csaState : 32|2@1+ (1,0) [0|0] "" GTW,APS
 SG_ DAS_radarTelemetry : 34|2@1+ (1,0) [0|0] "" GTW,APS
 SG_ DAS_robState : 36|2@1+ (1,0) [0|3] "" GTW,APS
 SG_ DAS_driverInteractionLevel : 38|2@1+ (1,0) [0|3] "" GTW,APS
 SG_ DAS_ppOffsetDesiredRamp : 40|8@1+ (0.01,-1.28) [-1.28|1.27] "m" GTW,APS
 SG_ DAS_longCollisionWarning : 48|4@1+ (1,0) [0|15] "" GTW,APS
 SG_ DAS_status2Counter : 52|4@1+ (1,0) [0|0] "" GTW,APS
 SG_ DAS_status2Checksum : 56|8@1+ (1,0) [0|0] "" GTW,APS

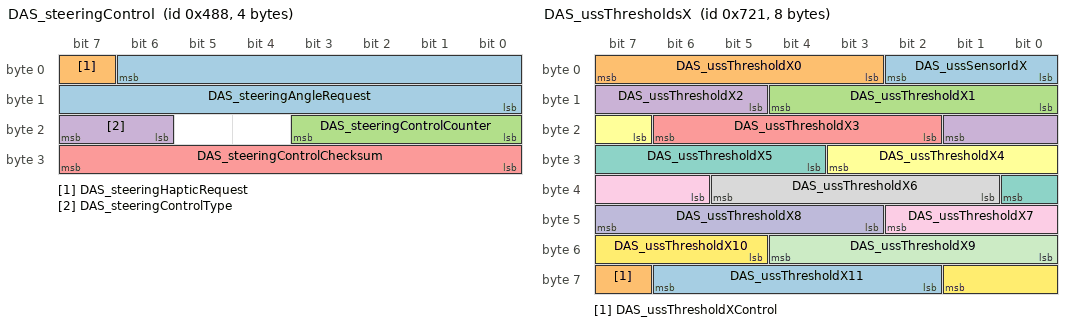
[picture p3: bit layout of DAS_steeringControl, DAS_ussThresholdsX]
BO_ 1160 DAS_steeringControl: 4 DAS
 SG_ DAS_steeringAngleRequest : 6|15@0+ (0.1,-1638.35) [-1638.35|1638.35] "deg" EPAS,EPAS2,EPAS3S,EPB,APS
 SG_ DAS_steeringHapticRequest : 7|1@0+ (1,0) [0|0] "" EPAS,EPAS2,EPAS3S,APS
 SG_ DAS_steeringControlCounter : 19|4@0+ (1,0) [0|0] "" EPAS,EPAS2,EPAS3S,APS
 SG_ DAS_steeringControlType : 23|2@0+ (1,0) [0|0] "" EPAS,EPAS2,EPAS3S,EPB,APS
 SG_ DAS_steeringControlChecksum : 31|8@0+ (1,0) [0|0] "" EPAS,EPAS2,EPAS3S,APS

BO_ 937 DAS_telemetry: 8 DAS
 SG_ DAS_telemetryMultiplexer M : 0|8@1+ (1,0) [0|0] "" GTW
 SG_ DAS_telLeftLaneType m0 : 8|3@1+ (1,0) [0|0] "" GTW
 SG_ DAS_telRightLaneType m0 : 11|3@1+ (1,0) [0|0] "" GTW
 SG_ DAS_telLeftMarkerQuality m0 : 14|2@1+ (1,0) [0|0] "" GTW
 SG_ DAS_telRightMarkerQuality m0 : 16|2@1+ (1,0) [0|0] "" GTW
 SG_ DAS_telLeftMarkerColor m0 : 18|2@1+ (1,0) [0|0] "" GTW
 SG_ DAS_telRightMarkerColor m0 : 20|2@1+ (1,0) [0|0] "" GTW
 SG_ DAS_telLeftLaneCrossing m0 : 22|1@1+ (1,0) [0|0] "" GTW
 SG_ DAS_telRightLaneCrossing m0 : 23|1@1+ (1,0) [0|0] "" GTW
 SG_ DAS_MCPObserved m1 : 8|1@1+ (1,0) [0|1] "" GTW
 SG_ DAS_accReengaged m1 : 9|1@1+ (1,0) [0|1] "" GTW
 SG_ DAS_pedestrianInFOVBeforeIntr m1 : 10|1@1+ (1,0) [0|1] "" GTW
 SG_ DAS_pedestrianInFOVAfterIntr m1 : 11|1@1+ (1,0) [0|1] "" GTW
 SG_ DAS_camFreeSpaceBeforeIntr m1 : 12|1@1+ (1,0) [0|1] "" GTW
 SG_ DAS_camFreeSpaceAfterIntr m1 : 13|1@1+ (1,0) [0|1] "" GTW
 SG_ DAS_timeOfIntervention m1 : 14|6@1+ (0.25,0) [0|16] "s" GTW
 SG_ DAS_timeOfFirstPedestrian m1 : 20|6@1+ (0.25,0) [0|16] "s" GTW
 SG_ DAS_timeOfACCReengaging m1 : 26|6@1+ (0.25,0) [0|16] "s" GTW
 SG_ DAS_durationOfPrevACCStandstill m1 : 32|6@1+ (0.5,0) [0|30] "s" GTW
 SG_ DAS_maxAbsSteeringWheelAngle m1 : 38|7@1+ (2,0) [0|256] "degrees" GTW
 SG_ DAS_targetRelvelAtIntervention m1 : 45|6@1+ (0.25,-2) [-2|13.5] "m/s" GTW
 SG_ DAS_targetDistAtIntervention m1 : 51|6@1+ (0.5,0) [0|32] "m" GTW
 SG_ DAS_egoSpeedAtIntervention m1 : 57|6@1+ (0.5,0) [0|32] "m/s" GTW
 SG_ DAS_stopSignLongitudinalDist m2 : 8|10@1+ (0.1,0) [0|102.2] "m" GTW
 SG_ DAS_stopSignLateralDist m2 : 18|8@1+ (0.25,-32) [-32|31.5] "m" GTW
 SG_ DAS_stopSignHeight m2 : 26|6@1+ (0.1,0) [0|6.2] "m" GTW
 SG_ DAS_stopSignStopLineDistance m2 : 32|10@1+ (0.1,-20) [-20|82.2] "m" GTW
 SG_ DAS_stopSignCIPVDistance m2 : 42|6@1+ (0.5,0) [0|31.5] "m" GTW
 SG_ DAS_stopSignHostAccel m2 : 48|10@1+ (0.01,-5) [-5|5.23] "m/s^2" GTW
 SG_ DAS_stopSignCrossingWarning m2 : 58|1@1+ (1,0) [0|1] "" GTW
 SG_ DAS_stopSignIndex m2 : 59|4@1+ (1,0) [0|15] "" GTW
 SG_ DAS_csaOverride m7 : 10|1@1+ (1,0) [0|0] "" GTW
 SG_ DAS_csaIntState m7 : 11|3@1+ (1,0) [0|3] "" GTW
 SG_ DAS_csaEnableSpeed m7 : 14|12@1+ (0.05,-25) [-25|179.75] "MPH" GTW
 SG_ DAS_csaDisableSpeed m7 : 26|12@1+ (0.05,-25) [-25|179.75] "MPH" GTW
 SG_ DAS_csaFiltCurv m7 : 40|16@1- (1E-06,0) [-0.032768|0.032767] "1/m" GTW
 SG_ DAS_csaMeasLatAccel m7 : 56|8@1+ (0.08,-10.24) [-10.24|10] "m/s^2" GTW
 SG_ DAS_soCamCipvStatus m8 : 8|2@1+ (1,0) [0|3] "" GTW
 SG_ DAS_soRad5Status m8 : 10|2@1+ (1,0) [0|3] "" GTW
 SG_ DAS_soRad1Status m8 : 12|2@1+ (1,0) [0|3] "" GTW
 SG_ DAS_soCamCipvDx m8 : 14|6@1+ (2,0) [0|126] "m" GTW
 SG_ DAS_soRad1Dx m8 : 20|6@1+ (2,0) [0|126] "m" GTW
 SG_ DAS_soRad5Dx m8 : 26|6@1+ (2,0) [0|126] "m" GTW
 SG_ DAS_soCamCipvDy m8 : 32|5@1+ (0.4,-6.4) [-6.4|6] "m" GTW
 SG_ DAS_soRad5Dy m8 : 37|5@1+ (0.4,-6.4) [-6.4|6] "m" GTW
 SG_ DAS_soCamCipvVx m8 : 42|5@1+ (1,0) [0|31] "m/s" GTW
 SG_ DAS_soRad5ObstProb m8 : 47|4@1+ (0.0625,0) [0|0.9375] "probability" GTW
 SG_ DAS_soRad5Dz m8 : 51|6@1+ (0.25,-5) [-5|10.75] "m" GTW
 SG_ DAS_soRad5powerdB m8 : 57|7@1+ (2,0) [0|254] "dB" GTW
 SG_ DAS_assPrevSetSpeed m9 : 8|8@1+ (0.25,0) [0|63.75] "m/s" GTW
 SG_ DAS_assNewSetSpeed m9 : 16|8@1+ (0.25,0) [0|63.75] "m/s" GTW
 SG_ DAS_assFusedSpeedLimit m9 : 24|6@1+ (1,0) [0|63] "m/s" GTW
 SG_ DAS_assAutosteerActive m9 : 30|1@1+ (1,0) [0|1] "" GTW
 SG_ DAS_assSmartSpeedActive m9 : 31|1@1+ (2,0) [0|1] "" GTW

BO_ 985 DAS_telemetryEvent: 8 DAS
 SG_ DAS_TE_multiplexer M : 0|5@1+ (1,0) [0|0] "" GTW
 SG_ DAS_TE_counter m0 : 5|3@1+ (1,0) [0|0] "" GTW
 SG_ DAS_TE_eventID m0 : 8|16@1+ (1,0) [0|0] "" GTW
 SG_ DAS_TE_eventType m0 : 24|6@1+ (1,0) [0|0] "" GTW
 SG_ DAS_TE_lcAbortReason m0 : 32|5@1+ (1,0) [0|0] "" GTW
 SG_ DAS_TE_llCounter m1 : 5|3@1+ (1,0) [0|7] "" GTW
 SG_ DAS_TE_llC0 m1 : 8|10@1- (0.02,0) [-10.24|10.22] "m" GTW
 SG_ DAS_TE_llC1 m1 : 18|9@1- (0.001953125,0) [-0.5|0.498046875] "rad" GTW
 SG_ DAS_TE_llC2 m1 : 27|14@1- (4E-06,0) [-0.032768|0.032764] "1/m" GTW
 SG_ DAS_TE_llC3 m1 : 41|14@1- (1.6E-08,0) [-0.000131072|0.000131056] "1/m2" GTW
 SG_ DAS_TE_llQlty m1 : 55|1@1+ (1,0) [0|1] "" GTW
 SG_ DAS_TE_llRange m1 : 56|7@1+ (1,0) [0|127] "m" GTW
 SG_ DAS_TE_llFuse m1 : 63|1@1+ (1,0) [0|1] "" GTW
 SG_ DAS_TE_rlCounter m2 : 5|3@1+ (1,0) [0|7] "" GTW
 SG_ DAS_TE_rlC0 m2 : 8|10@1- (0.02,0) [-10.24|10.22] "m" GTW
 SG_ DAS_TE_rlC1 m2 : 18|9@1- (0.001953125,0) [-0.5|0.498046875] "rad" GTW
 SG_ DAS_TE_rlC2 m2 : 27|14@1- (4E-06,0) [-0.032768|0.032764] "1/m" GTW
 SG_ DAS_TE_rlC3 m2 : 41|14@1- (1.6E-08,0) [-0.000131072|0.000131056] "1/m2" GTW
 SG_ DAS_TE_rlQlty m2 : 55|1@1+ (1,0) [0|1] "" GTW
 SG_ DAS_TE_rlRange m2 : 56|7@1+ (1,0) [0|127] "m" GTW
 SG_ DAS_TE_rlFuse m2 : 63|1@1+ (1,0) [0|1] "" GTW
 SG_ DAS_TE_hppCounter m3 : 5|3@1+ (1,0) [0|7] "" GTW
 SG_ DAS_TE_hppC0 m3 : 8|10@1- (0.02,0) [-10.24|10.22] "m" GTW
 SG_ DAS_TE_hppC1 m3 : 18|9@1- (0.001953125,0) [-0.5|0.498046875] "rad" GTW
 SG_ DAS_TE_hppC2 m3 : 27|14@1- (4E-06,0) [-0.032768|0.032764] "1/m" GTW
 SG_ DAS_TE_hppC3 m3 : 41|14@1- (1.6E-08,0) [-0.000131072|0.000131056] "1/m2" GTW
 SG_ DAS_TE_hppQlty m3 : 55|1@1+ (1,0) [0|1] "" GTW
 SG_ DAS_TE_hppRange m3 : 56|7@1+ (1,0) [0|127] "m" GTW
 SG_ DAS_TE_hppFuse m3 : 63|1@1+ (1,0) [0|1] "" GTW
 SG_ DAS_TE_navCounter m4 : 5|3@1+ (1,0) [0|7] "" GTW
 SG_ DAS_TE_navC0 m4 : 8|10@1- (0.02,0) [-10.24|10.22] "m" GTW
 SG_ DAS_TE_navC1 m4 : 18|9@1- (0.001953125,0) [-0.5|0.498046875] "rad" GTW
 SG_ DAS_TE_navC2 m4 : 27|14@1- (4E-06,0) [-0.032768|0.032764] "1/m" GTW
 SG_ DAS_TE_navC3 m4 : 41|14@1- (1.6E-08,0) [-0.000131072|0.000131056] "1/m2" GTW
 SG_ DAS_TE_navQlty m4 : 55|1@1+ (1,0) [0|1] "" GTW
 SG_ DAS_TE_navRange m4 : 56|7@1+ (1,0) [0|127] "m" GTW
 SG_ DAS_TE_navFuse m4 : 63|1@1+ (1,0) [0|1] "" GTW
 SG_ DAS_TE_vlCounter m5 : 5|3@1+ (1,0) [0|7] "" GTW
 SG_ DAS_TE_vlC0 m5 : 8|10@1- (0.02,0) [-10.24|10.22] "m" GTW
 SG_ DAS_TE_vlC1 m5 : 18|9@1- (0.001953125,0) [-0.5|0.498046875] "rad" GTW
 SG_ DAS_TE_vlC2 m5 : 27|14@1- (4E-06,0) [-0.032768|0.032764] "1/m" GTW
 SG_ DAS_TE_vlC3 m5 : 41|14@1- (1.6E-08,0) [-0.000131072|0.000131056] "1/m2" GTW
 SG_ DAS_TE_vlQlty m5 : 55|1@1+ (1,0) [0|1] "" GTW
 SG_ DAS_TE_vlRange m5 : 56|7@1+ (1,0) [0|127] "m" GTW
 SG_ DAS_TE_vlFuse m5 : 63|1@1+ (1,0) [0|1] "" GTW
 SG_ DAS_TE_accCounter m6 : 5|3@1+ (1,0) [0|7] "" GTW
 SG_ DAS_TE_accTargetDx m6 : 8|6@1+ (2,0) [0|126] "m" GTW
 SG_ DAS_TE_accTargetDy m6 : 14|6@1+ (0.2,-6.4) [-6.4|6.2] "m" GTW
 SG_ DAS_TE_accTargetRelVel m6 : 20|7@1- (0.25,0) [-31.75|0] "m/s" GTW
 SG_ DAS_TE_accTargetRelA m6 : 27|5@1- (0.5,0) [-15.5|0] "m/s^2" GTW
 SG_ DAS_TE_accMinAccel m6 : 32|5@1- (0.5,0) [-15.5|0] "m/s^2" GTW
 SG_ DAS_TE_accMinJ m6 : 37|5@1- (0.5,0) [-15.5|0] "m/s^3" GTW
 SG_ DAS_TE_fcmCounter m7 : 5|3@1+ (1,0) [0|7] "" GTW
 SG_ DAS_TE_fcmTargetDx m7 : 8|8@1+ (0.25,0) [0|63.75] "m" GTW
 SG_ DAS_TE_fcmTargetDy m7 : 16|5@1+ (0.2,0) [-3.2|3] "m" GTW
 SG_ DAS_TE_fcmTargetVRel m7 : 21|7@1+ (0.25,-31.75) [-31.75|0] "m/s" GTW
 SG_ DAS_TE_fcmTargetAccel m7 : 28|5@1+ (0.5,-15.5) [-15.5|0] "m/s^2" GTW
 SG_ DAS_TE_fcmTargetProb m7 : 33|5@1+ (5,0) [0|160] "%" GTW
 SG_ DAS_TE_fcmDecelReqInstant m7 : 38|7@1- (0.1,0) [-12.7|0] "m/s^2" GTW
 SG_ DAS_TE_fcmDecelReqAeb m7 : 45|7@1- (0.1,0) [-12.7|0] "m/s^2" GTW
 SG_ DAS_TE_meAebFlag m7 : 52|1@1+ (1,0) [0|1] "" GTW
 SG_ DAS_TE_accControlType m8 : 44|4@1+ (1,0) [0|7] "" GTW
 SG_ DAS_TE_brakeCapacityWarning m8 : 48|1@1+ (1,0) [0|1] "" GTW
 SG_ DAS_TE_emergencyBrake m8 : 49|1@1+ (1,0) [0|1] "" GTW
 SG_ DAS_TE_extendedAccLimits m8 : 50|1@1+ (1,0) [0|1] "" GTW
 SG_ DAS_TE_crashFront m8 : 51|1@1+ (1,0) [0|1] "" GTW
 SG_ DAS_TE_crashLeft m8 : 52|1@1+ (1,0) [0|1] "" GTW
 SG_ DAS_TE_crashRear m8 : 53|1@1+ (1,0) [0|1] "" GTW
 SG_ DAS_TE_crashRight m8 : 54|1@1+ (1,0) [0|1] "" GTW
 SG_ DAS_TE_crashRollover m8 : 55|1@1+ (1,0) [0|1] "" GTW
 SG_ DAS_TE_crashPedPro m8 : 56|1@1+ (1,0) [0|1] "" GTW
 SG_ DAS_TE_meIpsoValid m8 : 57|1@1+ (1,0) [0|1] "" GTW
 SG_ DAS_TE_robCounter m9 : 5|3@1+ (1,0) [0|7] "" GTW
 SG_ DAS_TE_robExceptionStart m9 : 16|8@1+ (1,-95) [-95|160] "m" GTW
 SG_ DAS_TE_robExceptionEnd m9 : 24|8@1+ (1,0) [0|255] "m" GTW
 SG_ DAS_TE_robDistanceEllipse m9 : 32|8@1+ (0.5,0) [0|127.5] "m" GTW
 SG_ DAS_TE_robEllipseOverlap m9 : 40|8@1+ (0.1,-12.5) [-12.5|12.5] "m" GTW
 SG_ DAS_TE_robEllipseAge m9 : 48|3@1+ (1,0) [0|7] "" GTW
 SG_ DAS_TE_robInfrastructure m9 : 51|1@1+ (1,0) [0|1] "" GTW
 SG_ DAS_TE_robTrustRadarMap m9 : 52|1@1+ (1,0) [0|1] "" GTW
 SG_ DAS_TE_robActiveBraking m9 : 53|1@1+ (1,0) [0|1] "" GTW

BO_ 945 DAS_telemetryFurniture: 8 DAS
 SG_ DAS_TF_multiplexer M : 0|5@1+ (1,0) [0|0] "" GTW
 SG_ DAS_TF_furnitureIndex0 m0 : 5|8@1+ (1,0) [0|255] "" GTW
 SG_ DAS_TF_distTraveled m0 : 13|11@1+ (0.1,0) [0|204.7] "m" GTW
 SG_ DAS_TF_llType m0 : 24|3@1+ (1,0) [0|7] "" GTW
 SG_ DAS_TF_rlType m0 : 27|3@1+ (1,0) [0|7] "" GTW
 SG_ DAS_TF_cipvDist m0 : 30|9@1+ (0.1,0) [0|51.1] "m" GTW
 SG_ DAS_TF_timeOfDay m0 : 39|3@1+ (1,0) [0|7] "" GTW
 SG_ DAS_TF_furnitureType m0 : 42|3@1+ (1,0) [0|7] "" GTW
 SG_ DAS_TF_furnitureIndex1 m1 : 5|8@1+ (1,0) [0|255] "" GTW
 SG_ DAS_TF_longitudinalDist m1 : 13|12@1+ (0.1,0) [0|409.5] "m" GTW
 SG_ DAS_TF_lateralDist m1 : 25|12@1+ (0.1,-204.8) [-204.8|204.7] "m" GTW
 SG_ DAS_TF_height m1 : 37|12@1+ (0.05,0) [0|204.75] "m" GTW
 SG_ DAS_TF_color m1 : 49|3@1+ (1,0) [0|7] "" GTW
 SG_ DAS_TF_shape m1 : 52|3@1+ (1,0) [0|7] "" GTW
 SG_ DAS_TF_orientation m1 : 55|2@1+ (1,0) [0|3] "" GTW
 SG_ DAS_TF_transmissionStatus m1 : 57|2@1+ (1,0) [0|3] "" GTW
 SG_ DAS_TF_isMain m1 : 59|1@1+ (1,0) [0|1] "" GTW
 SG_ DAS_TF_isTeslaMain m1 : 60|1@1+ (1,0) [0|1] "" GTW
 SG_ DAS_TF_furnitureIndex2 m2 : 5|8@1+ (1,0) [0|255] "" GTW
 SG_ DAS_TF_juncStatus m2 : 13|4@1+ (1,0) [0|7] "" GTW
 SG_ DAS_TF_juncDist m2 : 17|11@1+ (0.2,-20) [-20|389.4] "m" GTW
 SG_ DAS_TF_stopLineDist m2 : 28|11@1+ (0.1,-10) [-10|194.7] "m" GTW
 SG_ DAS_TF_ttc m2 : 39|7@1+ (0.1,0) [0|12.7] "s" GTW

BO_ 889 DAS_telemetryPeriodic: 8 DAS
 SG_ DAS_TP_multiplexer M : 0|5@1+ (1,0) [0|0] "" GTW
 SG_ DAS_TP_counter m0 : 5|3@1+ (1,0) [0|7] "" GTW
 SG_ DAS_TP_vlWidth m0 : 8|8@1+ (0.05,0) [0|12.75] "m" GTW
 SG_ DAS_TP_hppError m0 : 16|6@1+ (0.05,0) [0|3.15] "m" GTW
 SG_ DAS_TP_wipersActive m0 : 22|1@1+ (1,0) [0|1] "" GTW
 SG_ DAS_TP_handsOn m0 : 23|1@1+ (1,0) [0|1] "" GTW
 SG_ DAS_TP_sonicDistL m0 : 24|9@1+ (0.01,0) [0|5.11] "m" GTW
 SG_ DAS_TP_sonicDistR m0 : 33|9@1+ (0.01,0) [0|5.11] "m" GTW
 SG_ DAS_TP_hppValid m0 : 42|1@1+ (1,0) [0|1] "" GTW
 SG_ DAS_TP_restrictedAccess m0 : 43|1@1+ (1,0) [0|1] "" GTW
 SG_ DAS_TP_vehFuse m0 : 44|1@1+ (1,0) [0|1] "" GTW
 SG_ DAS_TP_accRestricted m0 : 46|1@1+ (1,0) [0|1] "" GTW
 SG_ DAS_TP_laneChange m0 : 48|2@1+ (1,0) [0|3] "" GTW
 SG_ DAS_TP_llType m0 : 50|3@1+ (1,0) [0|3] "" GTW
 SG_ DAS_TP_rlType m0 : 53|3@1+ (1,0) [0|3] "" GTW
 SG_ DAS_TP_plannerState m0 : 56|4@1+ (1,0) [0|15] "" GTW
 SG_ DAS_TP_lcState m0 : 60|4@1+ (1,0) [0|15] "" GTW
 SG_ DAS_TP_llCounter m1 : 5|3@1+ (1,0) [0|7] "" GTW
 SG_ DAS_TP_llC0 m1 : 8|10@1- (0.02,0) [-10.24|10.22] "m" GTW
 SG_ DAS_TP_llC1 m1 : 18|9@1- (0.001953125,0) [-0.5|0.498046875] "rad" GTW
 SG_ DAS_TP_llC2 m1 : 27|14@1- (4E-06,0) [-0.032768|0.032764] "1/m" GTW
 SG_ DAS_TP_llC3 m1 : 41|14@1- (1.6E-08,0) [-0.000131072|0.000131056] "1/m2" GTW
 SG_ DAS_TP_llQlty m1 : 55|1@1+ (1,0) [0|1] "" GTW
 SG_ DAS_TP_llRange m1 : 56|7@1+ (1,0) [0|127] "m" GTW
 SG_ DAS_TP_llFuse m1 : 63|1@1+ (1,0) [0|1] "" GTW
 SG_ DAS_TP_rlCounter m2 : 5|3@1+ (1,0) [0|7] "" GTW
 SG_ DAS_TP_rlC0 m2 : 8|10@1- (0.02,0) [-10.24|10.22] "m" GTW
 SG_ DAS_TP_rlC1 m2 : 18|9@1- (0.001953125,0) [-0.5|0.498046875] "rad" GTW
 SG_ DAS_TP_rlC2 m2 : 27|14@1- (4E-06,0) [-0.032768|0.032764] "1/m" GTW
 SG_ DAS_TP_rlC3 m2 : 41|14@1- (1.6E-08,0) [-0.000131072|0.000131056] "1/m2" GTW
 SG_ DAS_TP_rlQlty m2 : 55|1@1+ (1,0) [0|1] "" GTW
 SG_ DAS_TP_rlRange m2 : 56|7@1+ (1,0) [0|127] "m" GTW
 SG_ DAS_TP_rlFuse m2 : 63|1@1+ (1,0) [0|1] "" GTW
 SG_ DAS_TP_hppCounter m3 : 5|3@1+ (1,0) [0|7] "" GTW
 SG_ DAS_TP_hppC0 m3 : 8|10@1- (0.02,0) [-10.24|10.22] "m" GTW
 SG_ DAS_TP_hppC1 m3 : 18|9@1- (0.001953125,0) [-0.5|0.498046875] "rad" GTW
 SG_ DAS_TP_hppC2 m3 : 27|14@1- (4E-06,0) [-0.032768|0.032764] "1/m" GTW
 SG_ DAS_TP_hppC3 m3 : 41|14@1- (1.6E-08,0) [-0.000131072|0.000131056] "1/m2" GTW
 SG_ DAS_TP_hppQlty m3 : 55|1@1+ (1,0) [0|1] "" GTW
 SG_ DAS_TP_hppRange m3 : 56|7@1+ (1,0) [0|127] "m" GTW
 SG_ DAS_TP_hppFuse m3 : 63|1@1+ (1,0) [0|1] "" GTW
 SG_ DAS_TP_navCounter m4 : 5|3@1+ (1,0) [0|7] "" GTW
 SG_ DAS_TP_navC0 m4 : 8|10@1- (0.02,0) [-10.24|10.22] "m" GTW
 SG_ DAS_TP_navC1 m4 : 18|9@1- (0.001953125,0) [-0.5|0.498046875] "rad" GTW
 SG_ DAS_TP_navC2 m4 : 27|14@1- (4E-06,0) [-0.032768|0.032764] "1/m" GTW
 SG_ DAS_TP_navC3 m4 : 41|14@1- (1.6E-08,0) [-0.000131072|0.000131056] "1/m2" GTW
 SG_ DAS_TP_navQlty m4 : 55|1@1+ (1,0) [0|1] "" GTW
 SG_ DAS_TP_navRange m4 : 56|7@1+ (1,0) [0|127] "m" GTW
 SG_ DAS_TP_navFuse m4 : 63|1@1+ (1,0) [0|1] "" GTW
 SG_ DAS_TP_vlCounter m5 : 5|3@1+ (1,0) [0|7] "" GTW
 SG_ DAS_TP_vlC0 m5 : 8|10@1- (0.02,0) [-10.24|10.22] "m" GTW
 SG_ DAS_TP_vlC1 m5 : 18|9@1- (0.001953125,0) [-0.5|0.498046875] "rad" GTW
 SG_ DAS_TP_vlC2 m5 : 27|14@1- (4E-06,0) [-0.032768|0.032764] "1/m" GTW
 SG_ DAS_TP_vlC3 m5 : 41|14@1- (1.6E-08,0) [-0.000131072|0.000131056] "1/m2" GTW
 SG_ DAS_TP_vlQlty m5 : 55|1@1+ (1,0) [0|1] "" GTW
 SG_ DAS_TP_vlRange m5 : 56|7@1+ (1,0) [0|127] "m" GTW
 SG_ DAS_TP_vlFuse m5 : 63|1@1+ (1,0) [0|1] "" GTW
 SG_ DAS_TP_bdlCounter m6 : 5|3@1+ (1,0) [0|7] "" GTW
 SG_ DAS_TP_bdlC0 m6 : 8|10@1- (0.02,0) [-10.24|10.22] "m" GTW
 SG_ DAS_TP_bdlC1 m6 : 18|9@1- (0.001953125,0) [-0.5|0.498046875] "rad" GTW
 SG_ DAS_TP_bdlC2 m6 : 27|14@1- (4E-06,0) [-0.032768|0.032764] "1/m" GTW
 SG_ DAS_TP_bdlC3 m6 : 41|14@1- (1.6E-08,0) [-0.000131072|0.000131056] "1/m2" GTW
 SG_ DAS_TP_bdlQlty m6 : 55|1@1+ (1,0) [0|1] "" GTW
 SG_ DAS_TP_bdlRange m6 : 56|7@1+ (1,0) [0|127] "m" GTW
 SG_ DAS_TP_bdlFuse m6 : 63|1@1+ (1,0) [0|1] "" GTW
 SG_ DAS_TP_bdrCounter m7 : 5|3@1+ (1,0) [0|7] "" GTW
 SG_ DAS_TP_bdrC0 m7 : 8|10@1- (0.02,0) [-10.24|10.22] "m" GTW
 SG_ DAS_TP_bdrC1 m7 : 18|9@1- (0.001953125,0) [-0.5|0.498046875] "rad" GTW
 SG_ DAS_TP_bdrC2 m7 : 27|14@1- (4E-06,0) [-0.032768|0.032764] "1/m" GTW
 SG_ DAS_TP_bdrC3 m7 : 41|14@1- (1.6E-08,0) [-0.000131072|0.000131056] "1/m2" GTW
 SG_ DAS_TP_bdrQlty m7 : 55|1@1+ (1,0) [0|1] "" GTW
 SG_ DAS_TP_bdrRange m7 : 56|7@1+ (1,0) [0|127] "m" GTW
 SG_ DAS_TP_bdrFuse m7 : 63|1@1+ (1,0) [0|1] "" GTW
 SG_ DAS_TP_laneCounter m8 : 5|3@1+ (1,0) [0|7] "" GTW
 SG_ DAS_TP_llSegQ1 m8 : 8|4@1+ (10,0) [0|150] "%" GTW
 SG_ DAS_TP_llSegQ2 m8 : 12|4@1+ (10,0) [0|150] "%" GTW
 SG_ DAS_TP_llSegQ3 m8 : 16|4@1+ (10,0) [0|150] "%" GTW
 SG_ DAS_TP_llSegQ4 m8 : 20|4@1+ (10,0) [0|150] "%" GTW
 SG_ DAS_TP_rlSegQ1 m8 : 24|4@1+ (10,0) [0|150] "%" GTW
 SG_ DAS_TP_rlSegQ2 m8 : 28|4@1+ (10,0) [0|150] "%" GTW
 SG_ DAS_TP_rlSegQ3 m8 : 32|4@1+ (10,0) [0|150] "%" GTW
 SG_ DAS_TP_rlSegQ4 m8 : 36|4@1+ (10,0) [0|150] "%" GTW
 SG_ DAS_TP_llExist m8 : 40|4@1+ (10,0) [0|150] "%" GTW
 SG_ DAS_TP_rlExist m8 : 44|4@1+ (10,0) [0|150] "%" GTW
 SG_ DAS_TP_nllProb m8 : 48|4@1+ (0.1,0) [0|1.5] "1" GTW
 SG_ DAS_TP_nrlProb m8 : 52|4@1+ (0.1,0) [0|1.5] "1" GTW
 SG_ DAS_TP_llQltyME m8 : 56|2@1+ (1,0) [0|3] "" GTW
 SG_ DAS_TP_rlQltyME m8 : 58|2@1+ (1,0) [0|3] "" GTW
 SG_ DAS_TP_bdlQltyME m8 : 60|2@1+ (1,0) [0|3] "" GTW
 SG_ DAS_TP_bdrQltyME m8 : 62|2@1+ (1,0) [0|3] "" GTW
 SG_ DAS_TP_llrCounter m9 : 5|3@1+ (1,0) [0|7] "" GTW
 SG_ DAS_TP_numLanes m9 : 8|3@1+ (1,0) [0|7] "" GTW
 SG_ DAS_TP_lane1LLR m9 : 11|6@1+ (0.3125,-10) [-10|9.6875] "1" GTW
 SG_ DAS_TP_lane2LLR m9 : 17|6@1+ (0.3125,-10) [-10|9.6875] "1" GTW
 SG_ DAS_TP_lane3LLR m9 : 23|6@1+ (0.3125,-10) [-10|9.6875] "1" GTW
 SG_ DAS_TP_lane4LLR m9 : 29|6@1+ (0.3125,-10) [-10|9.6875] "1" GTW
 SG_ DAS_TP_lane5LLR m9 : 35|6@1+ (0.3125,-10) [-10|9.6875] "1" GTW
 SG_ DAS_TP_lane6LLR m9 : 41|6@1+ (0.3125,-10) [-10|9.6875] "1" GTW
 SG_ DAS_TP_lane7LLR m9 : 47|6@1+ (0.3125,-10) [-10|9.6875] "1" GTW
 SG_ DAS_TP_lane8LLR m9 : 53|6@1+ (0.3125,-10) [-10|9.6875] "1" GTW
 SG_ DAS_TP_egoLane m9 : 59|3@1+ (1,0) [0|7] "" GTW

BO_ 1545 DAS_telemetryRadar: 8 DAS
 SG_ DAS_TR_ObjIndex M : 0|5@1+ (1,0) [0|31] "" GTW
 SG_ DAS_TR_Counter : 54|2@1+ (1,0) [0|3] "" GTW
 SG_ DAS_TR_Obj00_Class m0 : 5|3@1+ (1,0) [0|7] "" GTW
 SG_ DAS_TR_Obj00_Dx m0 : 8|10@1+ (0.15625,0) [0|159.84375] "m" GTW
 SG_ DAS_TR_Obj00_Dy m0 : 18|6@1+ (0.5,-15.5) [-15.5|16] "m" GTW
 SG_ DAS_TR_Obj00_Vx m0 : 24|8@1+ (0.5,-63.5) [-63.5|64] "m/s" GTW
 SG_ DAS_TR_Obj00_RCS m0 : 32|8@1+ (0.25,-14) [-14|49.75] "dB" GTW
 SG_ DAS_TR_Obj00_Length m0 : 40|6@1+ (0.125,0) [0|7.875] "m" GTW
 SG_ DAS_TR_Obj00_MovingState m0 : 46|2@1+ (1,0) [0|3] "" GTW
 SG_ DAS_TR_Obj00_Dz m0 : 48|6@1+ (0.25,-5) [-5|10.75] "m" GTW
 SG_ DAS_TR_Obj00_Exist m0 : 56|5@1+ (3.125,0) [0|96.875] "%" GTW
 SG_ DAS_TR_Obj01_Class m1 : 5|3@1+ (1,0) [0|7] "" GTW
 SG_ DAS_TR_Obj01_Dx m1 : 8|10@1+ (0.15625,0) [0|159.84375] "m" GTW
 SG_ DAS_TR_Obj01_Dy m1 : 18|6@1+ (0.5,-15.5) [-15.5|16] "m" GTW
 SG_ DAS_TR_Obj01_Vx m1 : 24|8@1+ (0.5,-63.5) [-63.5|64] "m/s" GTW
 SG_ DAS_TR_Obj01_RCS m1 : 32|8@1+ (0.25,-14) [-14|49.75] "dB" GTW
 SG_ DAS_TR_Obj01_Length m1 : 40|6@1+ (0.125,0) [0|7.875] "m" GTW
 SG_ DAS_TR_Obj01_MovingState m1 : 46|2@1+ (1,0) [0|3] "" GTW
 SG_ DAS_TR_Obj01_Dz m1 : 48|6@1+ (0.25,-5) [-5|10.75] "m" GTW
 SG_ DAS_TR_Obj01_Exist m1 : 56|5@1+ (3.125,0) [0|96.875] "%" GTW
 SG_ DAS_TR_Obj02_Class m2 : 5|3@1+ (1,0) [0|7] "" GTW
 SG_ DAS_TR_Obj02_Dx m2 : 8|10@1+ (0.15625,0) [0|159.84375] "m" GTW
 SG_ DAS_TR_Obj02_Dy m2 : 18|6@1+ (0.5,-15.5) [-15.5|16] "m" GTW
 SG_ DAS_TR_Obj02_Vx m2 : 24|8@1+ (0.5,-63.5) [-63.5|64] "m/s" GTW
 SG_ DAS_TR_Obj02_RCS m2 : 32|8@1+ (0.25,-14) [-14|49.75] "dB" GTW
 SG_ DAS_TR_Obj02_Length m2 : 40|6@1+ (0.125,0) [0|7.875] "m" GTW
 SG_ DAS_TR_Obj02_MovingState m2 : 46|2@1+ (1,0) [0|3] "" GTW
 SG_ DAS_TR_Obj02_Dz m2 : 48|6@1+ (0.25,-5) [-5|10.75] "m" GTW
 SG_ DAS_TR_Obj02_Exist m2 : 56|5@1+ (3.125,0) [0|96.875] "%" GTW
 SG_ DAS_TR_Obj03_Class m3 : 5|3@1+ (1,0) [0|7] "" GTW
 SG_ DAS_TR_Obj03_Dx m3 : 8|10@1+ (0.15625,0) [0|159.84375] "m" GTW
 SG_ DAS_TR_Obj03_Dy m3 : 18|6@1+ (0.5,-15.5) [-15.5|16] "m" GTW
 SG_ DAS_TR_Obj03_Vx m3 : 24|8@1+ (0.5,-63.5) [-63.5|64] "m/s" GTW
 SG_ DAS_TR_Obj03_RCS m3 : 32|8@1+ (0.25,-14) [-14|49.75] "dB" GTW
 SG_ DAS_TR_Obj03_Length m3 : 40|6@1+ (0.125,0) [0|7.875] "m" GTW
 SG_ DAS_TR_Obj03_MovingState m3 : 46|2@1+ (1,0) [0|3] "" GTW
 SG_ DAS_TR_Obj03_Dz m3 : 48|6@1+ (0.25,-5) [-5|10.75] "m" GTW
 SG_ DAS_TR_Obj03_Exist m3 : 56|5@1+ (3.125,0) [0|96.875] "%" GTW
 SG_ DAS_TR_Obj04_Class m4 : 5|3@1+ (1,0) [0|7] "" GTW
 SG_ DAS_TR_Obj04_Dx m4 : 8|10@1+ (0.15625,0) [0|159.84375] "m" GTW
 SG_ DAS_TR_Obj04_Dy m4 : 18|6@1+ (0.5,-15.5) [-15.5|16] "m" GTW
 SG_ DAS_TR_Obj04_Vx m4 : 24|8@1+ (0.5,-63.5) [-63.5|64] "m/s" GTW
 SG_ DAS_TR_Obj04_RCS m4 : 32|8@1+ (0.25,-14) [-14|49.75] "dB" GTW
 SG_ DAS_TR_Obj04_Length m4 : 40|6@1+ (0.125,0) [0|7.875] "m" GTW
 SG_ DAS_TR_Obj04_MovingState m4 : 46|2@1+ (1,0) [0|3] "" GTW
 SG_ DAS_TR_Obj04_Dz m4 : 48|6@1+ (0.25,-5) [-5|10.75] "m" GTW
 SG_ DAS_TR_Obj04_Exist m4 : 56|5@1+ (3.125,0) [0|96.875] "%" GTW
 SG_ DAS_TR_Obj05_Class m5 : 5|3@1+ (1,0) [0|7] "" GTW
 SG_ DAS_TR_Obj05_Dx m5 : 8|10@1+ (0.15625,0) [0|159.84375] "m" GTW
 SG_ DAS_TR_Obj05_Dy m5 : 18|6@1+ (0.5,-15.5) [-15.5|16] "m" GTW
 SG_ DAS_TR_Obj05_Vx m5 : 24|8@1+ (0.5,-63.5) [-63.5|64] "m/s" GTW
 SG_ DAS_TR_Obj05_RCS m5 : 32|8@1+ (0.25,-14) [-14|49.75] "dB" GTW
 SG_ DAS_TR_Obj05_Length m5 : 40|6@1+ (0.125,0) [0|7.875] "m" GTW
 SG_ DAS_TR_Obj05_MovingState m5 : 46|2@1+ (1,0) [0|3] "" GTW
 SG_ DAS_TR_Obj05_Dz m5 : 48|6@1+ (0.25,-5) [-5|10.75] "m" GTW
 SG_ DAS_TR_Obj05_Exist m5 : 56|5@1+ (3.125,0) [0|96.875] "%" GTW
 SG_ DAS_TR_Obj06_Class m6 : 5|3@1+ (1,0) [0|7] "" GTW
 SG_ DAS_TR_Obj06_Dx m6 : 8|10@1+ (0.15625,0) [0|159.84375] "m" GTW
 SG_ DAS_TR_Obj06_Dy m6 : 18|6@1+ (0.5,-15.5) [-15.5|16] "m" GTW
 SG_ DAS_TR_Obj06_Vx m6 : 24|8@1+ (0.5,-63.5) [-63.5|64] "m/s" GTW
 SG_ DAS_TR_Obj06_RCS m6 : 32|8@1+ (0.25,-14) [-14|49.75] "dB" GTW
 SG_ DAS_TR_Obj06_Length m6 : 40|6@1+ (0.125,0) [0|7.875] "m" GTW
 SG_ DAS_TR_Obj06_MovingState m6 : 46|2@1+ (1,0) [0|3] "" GTW
 SG_ DAS_TR_Obj06_Dz m6 : 48|6@1+ (0.25,-5) [-5|10.75] "m" GTW
 SG_ DAS_TR_Obj06_Exist m6 : 56|5@1+ (3.125,0) [0|96.875] "%" GTW
 SG_ DAS_TR_Obj07_Class m7 : 5|3@1+ (1,0) [0|7] "" GTW
 SG_ DAS_TR_Obj07_Dx m7 : 8|10@1+ (0.15625,0) [0|159.84375] "m" GTW
 SG_ DAS_TR_Obj07_Dy m7 : 18|6@1+ (0.5,-15.5) [-15.5|16] "m" GTW
 SG_ DAS_TR_Obj07_Vx m7 : 24|8@1+ (0.5,-63.5) [-63.5|64] "m/s" GTW
 SG_ DAS_TR_Obj07_RCS m7 : 32|8@1+ (0.25,-14) [-14|49.75] "dB" GTW
 SG_ DAS_TR_Obj07_Length m7 : 40|6@1+ (0.125,0) [0|7.875] "m" GTW
 SG_ DAS_TR_Obj07_MovingState m7 : 46|2@1+ (1,0) [0|3] "" GTW
 SG_ DAS_TR_Obj07_Dz m7 : 48|6@1+ (0.25,-5) [-5|10.75] "m" GTW
 SG_ DAS_TR_Obj07_Exist m7 : 56|5@1+ (3.125,0) [0|96.875] "%" GTW
 SG_ DAS_TR_Obj08_Class m8 : 5|3@1+ (1,0) [0|7] "" GTW
 SG_ DAS_TR_Obj08_Dx m8 : 8|10@1+ (0.15625,0) [0|159.84375] "m" GTW
 SG_ DAS_TR_Obj08_Dy m8 : 18|6@1+ (0.5,-15.5) [-15.5|16] "m" GTW
 SG_ DAS_TR_Obj08_Vx m8 : 24|8@1+ (0.5,-63.5) [-63.5|64] "m/s" GTW
 SG_ DAS_TR_Obj08_RCS m8 : 32|8@1+ (0.25,-14) [-14|49.75] "dB" GTW
 SG_ DAS_TR_Obj08_Length m8 : 40|6@1+ (0.125,0) [0|7.875] "m" GTW
 SG_ DAS_TR_Obj08_MovingState m8 : 46|2@1+ (1,0) [0|3] "" GTW
 SG_ DAS_TR_Obj08_Dz m8 : 48|6@1+ (0.25,-5) [-5|10.75] "m" GTW
 SG_ DAS_TR_Obj08_Exist m8 : 56|5@1+ (3.125,0) [0|96.875] "%" GTW
 SG_ DAS_TR_Obj09_Class m9 : 5|3@1+ (1,0) [0|7] "" GTW
 SG_ DAS_TR_Obj09_Dx m9 : 8|10@1+ (0.15625,0) [0|159.84375] "m" GTW
 SG_ DAS_TR_Obj09_Dy m9 : 18|6@1+ (0.5,-15.5) [-15.5|16] "m" GTW
 SG_ DAS_TR_Obj09_Vx m9 : 24|8@1+ (0.5,-63.5) [-63.5|64] "m/s" GTW
 SG_ DAS_TR_Obj09_RCS m9 : 32|8@1+ (0.25,-14) [-14|49.75] "dB" GTW
 SG_ DAS_TR_Obj09_Length m9 : 40|6@1+ (0.125,0) [0|7.875] "m" GTW
 SG_ DAS_TR_Obj09_MovingState m9 : 46|2@1+ (1,0) [0|3] "" GTW
 SG_ DAS_TR_Obj09_Dz m9 : 48|6@1+ (0.25,-5) [-5|10.75] "m" GTW
 SG_ DAS_TR_Obj09_Exist m9 : 56|5@1+ (3.125,0) [0|96.875] "%" GTW
 SG_ DAS_TR_Obj10_Class m10 : 5|3@1+ (1,0) [0|7] "" GTW
 SG_ DAS_TR_Obj10_Dx m10 : 8|10@1+ (0.15625,0) [0|159.84375] "m" GTW
 SG_ DAS_TR_Obj10_Dy m10 : 18|6@1+ (0.5,-15.5) [-15.5|16] "m" GTW
 SG_ DAS_TR_Obj10_Vx m10 : 24|8@1+ (0.5,-63.5) [-63.5|64] "m/s" GTW
 SG_ DAS_TR_Obj10_RCS m10 : 32|8@1+ (0.25,-14) [-14|49.75] "dB" GTW
 SG_ DAS_TR_Obj10_Length m10 : 40|6@1+ (0.125,0) [0|7.875] "m" GTW
 SG_ DAS_TR_Obj10_MovingState m10 : 46|2@1+ (1,0) [0|3] "" GTW
 SG_ DAS_TR_Obj10_Dz m10 : 48|6@1+ (0.25,-5) [-5|10.75] "m" GTW
 SG_ DAS_TR_Obj10_Exist m10 : 56|5@1+ (3.125,0) [0|96.875] "%" GTW
 SG_ DAS_TR_Obj11_Class m11 : 5|3@1+ (1,0) [0|7] "" GTW
 SG_ DAS_TR_Obj11_Dx m11 : 8|10@1+ (0.15625,0) [0|159.84375] "m" GTW
 SG_ DAS_TR_Obj11_Dy m11 : 18|6@1+ (0.5,-15.5) [-15.5|16] "m" GTW
 SG_ DAS_TR_Obj11_Vx m11 : 24|8@1+ (0.5,-63.5) [-63.5|64] "m/s" GTW
 SG_ DAS_TR_Obj11_RCS m11 : 32|8@1+ (0.25,-14) [-14|49.75] "dB" GTW
 SG_ DAS_TR_Obj11_Length m11 : 40|6@1+ (0.125,0) [0|7.875] "m" GTW
 SG_ DAS_TR_Obj11_MovingState m11 : 46|2@1+ (1,0) [0|3] "" GTW
 SG_ DAS_TR_Obj11_Dz m11 : 48|6@1+ (0.25,-5) [-5|10.75] "m" GTW
 SG_ DAS_TR_Obj11_Exist m11 : 56|5@1+ (3.125,0) [0|96.875] "%" GTW
 SG_ DAS_TR_Obj12_Class m12 : 5|3@1+ (1,0) [0|7] "" GTW
 SG_ DAS_TR_Obj12_Dx m12 : 8|10@1+ (0.15625,0) [0|159.84375] "m" GTW
 SG_ DAS_TR_Obj12_Dy m12 : 18|6@1+ (0.5,-15.5) [-15.5|16] "m" GTW
 SG_ DAS_TR_Obj12_Vx m12 : 24|8@1+ (0.5,-63.5) [-63.5|64] "m/s" GTW
 SG_ DAS_TR_Obj12_RCS m12 : 32|8@1+ (0.25,-14) [-14|49.75] "dB" GTW
 SG_ DAS_TR_Obj12_Length m12 : 40|6@1+ (0.125,0) [0|7.875] "m" GTW
 SG_ DAS_TR_Obj12_MovingState m12 : 46|2@1+ (1,0) [0|3] "" GTW
 SG_ DAS_TR_Obj12_Dz m12 : 48|6@1+ (0.25,-5) [-5|10.75] "m" GTW
 SG_ DAS_TR_Obj12_Exist m12 : 56|5@1+ (3.125,0) [0|96.875] "%" GTW
 SG_ DAS_TR_Obj13_Class m13 : 5|3@1+ (1,0) [0|7] "" GTW
 SG_ DAS_TR_Obj13_Dx m13 : 8|10@1+ (0.15625,0) [0|159.84375] "m" GTW
 SG_ DAS_TR_Obj13_Dy m13 : 18|6@1+ (0.5,-15.5) [-15.5|16] "m" GTW
 SG_ DAS_TR_Obj13_Vx m13 : 24|8@1+ (0.5,-63.5) [-63.5|64] "m/s" GTW
 SG_ DAS_TR_Obj13_RCS m13 : 32|8@1+ (0.25,-14) [-14|49.75] "dB" GTW
 SG_ DAS_TR_Obj13_Length m13 : 40|6@1+ (0.125,0) [0|7.875] "m" GTW
 SG_ DAS_TR_Obj13_MovingState m13 : 46|2@1+ (1,0) [0|3] "" GTW
 SG_ DAS_TR_Obj13_Dz m13 : 48|6@1+ (0.25,-5) [-5|10.75] "m" GTW
 SG_ DAS_TR_Obj13_Exist m13 : 56|5@1+ (3.125,0) [0|96.875] "%" GTW
 SG_ DAS_TR_Obj14_Class m14 : 5|3@1+ (1,0) [0|7] "" GTW
 SG_ DAS_TR_Obj14_Dx m14 : 8|10@1+ (0.15625,0) [0|159.84375] "m" GTW
 SG_ DAS_TR_Obj14_Dy m14 : 18|6@1+ (0.5,-15.5) [-15.5|16] "m" GTW
 SG_ DAS_TR_Obj14_Vx m14 : 24|8@1+ (0.5,-63.5) [-63.5|64] "m/s" GTW
 SG_ DAS_TR_Obj14_RCS m14 : 32|8@1+ (0.25,-14) [-14|49.75] "dB" GTW
 SG_ DAS_TR_Obj14_Length m14 : 40|6@1+ (0.125,0) [0|7.875] "m" GTW
 SG_ DAS_TR_Obj14_MovingState m14 : 46|2@1+ (1,0) [0|3] "" GTW
 SG_ DAS_TR_Obj14_Dz m14 : 48|6@1+ (0.25,-5) [-5|10.75] "m" GTW
 SG_ DAS_TR_Obj14_Exist m14 : 56|5@1+ (3.125,0) [0|96.875] "%" GTW
 SG_ DAS_TR_Obj15_Class m15 : 5|3@1+ (1,0) [0|7] "" GTW
 SG_ DAS_TR_Obj15_Dx m15 : 8|10@1+ (0.15625,0) [0|159.84375] "m" GTW
 SG_ DAS_TR_Obj15_Dy m15 : 18|6@1+ (0.5,-15.5) [-15.5|16] "m" GTW
 SG_ DAS_TR_Obj15_Vx m15 : 24|8@1+ (0.5,-63.5) [-63.5|64] "m/s" GTW
 SG_ DAS_TR_Obj15_RCS m15 : 32|8@1+ (0.25,-14) [-14|49.75] "dB" GTW
 SG_ DAS_TR_Obj15_Length m15 : 40|6@1+ (0.125,0) [0|7.875] "m" GTW
 SG_ DAS_TR_Obj15_MovingState m15 : 46|2@1+ (1,0) [0|3] "" GTW
 SG_ DAS_TR_Obj15_Dz m15 : 48|6@1+ (0.25,-5) [-5|10.75] "m" GTW
 SG_ DAS_TR_Obj15_Exist m15 : 56|5@1+ (3.125,0) [0|96.875] "%" GTW
 SG_ DAS_TR_Obj16_Class m16 : 5|3@1+ (1,0) [0|7] "" GTW
 SG_ DAS_TR_Obj16_Dx m16 : 8|10@1+ (0.15625,0) [0|159.84375] "m" GTW
 SG_ DAS_TR_Obj16_Dy m16 : 18|6@1+ (0.5,-15.5) [-15.5|16] "m" GTW
 SG_ DAS_TR_Obj16_Vx m16 : 24|8@1+ (0.5,-63.5) [-63.5|64] "m/s" GTW
 SG_ DAS_TR_Obj16_RCS m16 : 32|8@1+ (0.25,-14) [-14|49.75] "dB" GTW
 SG_ DAS_TR_Obj16_Length m16 : 40|6@1+ (0.125,0) [0|7.875] "m" GTW
 SG_ DAS_TR_Obj16_MovingState m16 : 46|2@1+ (1,0) [0|3] "" GTW
 SG_ DAS_TR_Obj16_Dz m16 : 48|6@1+ (0.25,-5) [-5|10.75] "m" GTW
 SG_ DAS_TR_Obj16_Exist m16 : 56|5@1+ (3.125,0) [0|96.875] "%" GTW
 SG_ DAS_TR_Obj17_Class m17 : 5|3@1+ (1,0) [0|7] "" GTW
 SG_ DAS_TR_Obj17_Dx m17 : 8|10@1+ (0.15625,0) [0|159.84375] "m" GTW
 SG_ DAS_TR_Obj17_Dy m17 : 18|6@1+ (0.5,-15.5) [-15.5|16] "m" GTW
 SG_ DAS_TR_Obj17_Vx m17 : 24|8@1+ (0.5,-63.5) [-63.5|64] "m/s" GTW
 SG_ DAS_TR_Obj17_RCS m17 : 32|8@1+ (0.25,-14) [-14|49.75] "dB" GTW
 SG_ DAS_TR_Obj17_Length m17 : 40|6@1+ (0.125,0) [0|7.875] "m" GTW
 SG_ DAS_TR_Obj17_MovingState m17 : 46|2@1+ (1,0) [0|3] "" GTW
 SG_ DAS_TR_Obj17_Dz m17 : 48|6@1+ (0.25,-5) [-5|10.75] "m" GTW
 SG_ DAS_TR_Obj17_Exist m17 : 56|5@1+ (3.125,0) [0|96.875] "%" GTW
 SG_ DAS_TR_Obj18_Class m18 : 5|3@1+ (1,0) [0|7] "" GTW
 SG_ DAS_TR_Obj18_Dx m18 : 8|10@1+ (0.15625,0) [0|159.84375] "m" GTW
 SG_ DAS_TR_Obj18_Dy m18 : 18|6@1+ (0.5,-15.5) [-15.5|16] "m" GTW
 SG_ DAS_TR_Obj18_Vx m18 : 24|8@1+ (0.5,-63.5) [-63.5|64] "m/s" GTW
 SG_ DAS_TR_Obj18_RCS m18 : 32|8@1+ (0.25,-14) [-14|49.75] "dB" GTW
 SG_ DAS_TR_Obj18_Length m18 : 40|6@1+ (0.125,0) [0|7.875] "m" GTW
 SG_ DAS_TR_Obj18_MovingState m18 : 46|2@1+ (1,0) [0|3] "" GTW
 SG_ DAS_TR_Obj18_Dz m18 : 48|6@1+ (0.25,-5) [-5|10.75] "m" GTW
 SG_ DAS_TR_Obj18_Exist m18 : 56|5@1+ (3.125,0) [0|96.875] "%" GTW
 SG_ DAS_TR_Obj19_Class m19 : 5|3@1+ (1,0) [0|7] "" GTW
 SG_ DAS_TR_Obj19_Dx m19 : 8|10@1+ (0.15625,0) [0|159.84375] "m" GTW
 SG_ DAS_TR_Obj19_Dy m19 : 18|6@1+ (0.5,-15.5) [-15.5|16] "m" GTW
 SG_ DAS_TR_Obj19_Vx m19 : 24|8@1+ (0.5,-63.5) [-63.5|64] "m/s" GTW
 SG_ DAS_TR_Obj19_RCS m19 : 32|8@1+ (0.25,-14) [-14|49.75] "dB" GTW
 SG_ DAS_TR_Obj19_Length m19 : 40|6@1+ (0.125,0) [0|7.875] "m" GTW
 SG_ DAS_TR_Obj19_MovingState m19 : 46|2@1+ (1,0) [0|3] "" GTW
 SG_ DAS_TR_Obj19_Dz m19 : 48|6@1+ (0.25,-5) [-5|10.75] "m" GTW
 SG_ DAS_TR_Obj19_Exist m19 : 56|5@1+ (3.125,0) [0|96.875] "%" GTW
 SG_ DAS_TR_Obj20_Class m20 : 5|3@1+ (1,0) [0|7] "" GTW
 SG_ DAS_TR_Obj20_Dx m20 : 8|10@1+ (0.15625,0) [0|159.84375] "m" GTW
 SG_ DAS_TR_Obj20_Dy m20 : 18|6@1+ (0.5,-15.5) [-15.5|16] "m" GTW
 SG_ DAS_TR_Obj20_Vx m20 : 24|8@1+ (0.5,-63.5) [-63.5|64] "m/s" GTW
 SG_ DAS_TR_Obj20_RCS m20 : 32|8@1+ (0.25,-14) [-14|49.75] "dB" GTW
 SG_ DAS_TR_Obj20_Length m20 : 40|6@1+ (0.125,0) [0|7.875] "m" GTW
 SG_ DAS_TR_Obj20_MovingState m20 : 46|2@1+ (1,0) [0|3] "" GTW
 SG_ DAS_TR_Obj20_Dz m20 : 48|6@1+ (0.25,-5) [-5|10.75] "m" GTW
 SG_ DAS_TR_Obj20_Exist m20 : 56|5@1+ (3.125,0) [0|96.875] "%" GTW
 SG_ DAS_TR_Obj21_Class m21 : 5|3@1+ (1,0) [0|7] "" GTW
 SG_ DAS_TR_Obj21_Dx m21 : 8|10@1+ (0.15625,0) [0|159.84375] "m" GTW
 SG_ DAS_TR_Obj21_Dy m21 : 18|6@1+ (0.5,-15.5) [-15.5|16] "m" GTW
 SG_ DAS_TR_Obj21_Vx m21 : 24|8@1+ (0.5,-63.5) [-63.5|64] "m/s" GTW
 SG_ DAS_TR_Obj21_RCS m21 : 32|8@1+ (0.25,-14) [-14|49.75] "dB" GTW
 SG_ DAS_TR_Obj21_Length m21 : 40|6@1+ (0.125,0) [0|7.875] "m" GTW
 SG_ DAS_TR_Obj21_MovingState m21 : 46|2@1+ (1,0) [0|3] "" GTW
 SG_ DAS_TR_Obj21_Dz m21 : 48|6@1+ (0.25,-5) [-5|10.75] "m" GTW
 SG_ DAS_TR_Obj21_Exist m21 : 56|5@1+ (3.125,0) [0|96.875] "%" GTW
 SG_ DAS_TR_Obj22_Class m22 : 5|3@1+ (1,0) [0|7] "" GTW
 SG_ DAS_TR_Obj22_Dx m22 : 8|10@1+ (0.15625,0) [0|159.84375] "m" GTW
 SG_ DAS_TR_Obj22_Dy m22 : 18|6@1+ (0.5,-15.5) [-15.5|16] "m" GTW
 SG_ DAS_TR_Obj22_Vx m22 : 24|8@1+ (0.5,-63.5) [-63.5|64] "m/s" GTW
 SG_ DAS_TR_Obj22_RCS m22 : 32|8@1+ (0.25,-14) [-14|49.75] "dB" GTW
 SG_ DAS_TR_Obj22_Length m22 : 40|6@1+ (0.125,0) [0|7.875] "m" GTW
 SG_ DAS_TR_Obj22_MovingState m22 : 46|2@1+ (1,0) [0|3] "" GTW
 SG_ DAS_TR_Obj22_Dz m22 : 48|6@1+ (0.25,-5) [-5|10.75] "m" GTW
 SG_ DAS_TR_Obj22_Exist m22 : 56|5@1+ (3.125,0) [0|96.875] "%" GTW
 SG_ DAS_TR_Obj23_Class m23 : 5|3@1+ (1,0) [0|7] "" GTW
 SG_ DAS_TR_Obj23_Dx m23 : 8|10@1+ (0.15625,0) [0|159.84375] "m" GTW
 SG_ DAS_TR_Obj23_Dy m23 : 18|6@1+ (0.5,-15.5) [-15.5|16] "m" GTW
 SG_ DAS_TR_Obj23_Vx m23 : 24|8@1+ (0.5,-63.5) [-63.5|64] "m/s" GTW
 SG_ DAS_TR_Obj23_RCS m23 : 32|8@1+ (0.25,-14) [-14|49.75] "dB" GTW
 SG_ DAS_TR_Obj23_Length m23 : 40|6@1+ (0.125,0) [0|7.875] "m" GTW
 SG_ DAS_TR_Obj23_MovingState m23 : 46|2@1+ (1,0) [0|3] "" GTW
 SG_ DAS_TR_Obj23_Dz m23 : 48|6@1+ (0.25,-5) [-5|10.75] "m" GTW
 SG_ DAS_TR_Obj23_Exist m23 : 56|5@1+ (3.125,0) [0|96.875] "%" GTW
 SG_ DAS_TR_Obj24_Class m24 : 5|3@1+ (1,0) [0|7] "" GTW
 SG_ DAS_TR_Obj24_Dx m24 : 8|10@1+ (0.15625,0) [0|159.84375] "m" GTW
 SG_ DAS_TR_Obj24_Dy m24 : 18|6@1+ (0.5,-15.5) [-15.5|16] "m" GTW
 SG_ DAS_TR_Obj24_Vx m24 : 24|8@1+ (0.5,-63.5) [-63.5|64] "m/s" GTW
 SG_ DAS_TR_Obj24_RCS m24 : 32|8@1+ (0.25,-14) [-14|49.75] "dB" GTW
 SG_ DAS_TR_Obj24_Length m24 : 40|6@1+ (0.125,0) [0|7.875] "m" GTW
 SG_ DAS_TR_Obj24_MovingState m24 : 46|2@1+ (1,0) [0|3] "" GTW
 SG_ DAS_TR_Obj24_Dz m24 : 48|6@1+ (0.25,-5) [-5|10.75] "m" GTW
 SG_ DAS_TR_Obj24_Exist m24 : 56|5@1+ (3.125,0) [0|96.875] "%" GTW
 SG_ DAS_TR_Obj25_Class m25 : 5|3@1+ (1,0) [0|7] "" GTW
 SG_ DAS_TR_Obj25_Dx m25 : 8|10@1+ (0.15625,0) [0|159.84375] "m" GTW
 SG_ DAS_TR_Obj25_Dy m25 : 18|6@1+ (0.5,-15.5) [-15.5|16] "m" GTW
 SG_ DAS_TR_Obj25_Vx m25 : 24|8@1+ (0.5,-63.5) [-63.5|64] "m/s" GTW
 SG_ DAS_TR_Obj25_RCS m25 : 32|8@1+ (0.25,-14) [-14|49.75] "dB" GTW
 SG_ DAS_TR_Obj25_Length m25 : 40|6@1+ (0.125,0) [0|7.875] "m" GTW
 SG_ DAS_TR_Obj25_MovingState m25 : 46|2@1+ (1,0) [0|3] "" GTW
 SG_ DAS_TR_Obj25_Dz m25 : 48|6@1+ (0.25,-5) [-5|10.75] "m" GTW
 SG_ DAS_TR_Obj25_Exist m25 : 56|5@1+ (3.125,0) [0|96.875] "%" GTW
 SG_ DAS_TR_Obj26_Class m26 : 5|3@1+ (1,0) [0|7] "" GTW
 SG_ DAS_TR_Obj26_Dx m26 : 8|10@1+ (0.15625,0) [0|159.84375] "m" GTW
 SG_ DAS_TR_Obj26_Dy m26 : 18|6@1+ (0.5,-15.5) [-15.5|16] "m" GTW
 SG_ DAS_TR_Obj26_Vx m26 : 24|8@1+ (0.5,-63.5) [-63.5|64] "m/s" GTW
 SG_ DAS_TR_Obj26_RCS m26 : 32|8@1+ (0.25,-14) [-14|49.75] "dB" GTW
 SG_ DAS_TR_Obj26_Length m26 : 40|6@1+ (0.125,0) [0|7.875] "m" GTW
 SG_ DAS_TR_Obj26_MovingState m26 : 46|2@1+ (1,0) [0|3] "" GTW
 SG_ DAS_TR_Obj26_Dz m26 : 48|6@1+ (0.25,-5) [-5|10.75] "m" GTW
 SG_ DAS_TR_Obj26_Exist m26 : 56|5@1+ (3.125,0) [0|96.875] "%" GTW
 SG_ DAS_TR_Obj27_Class m27 : 5|3@1+ (1,0) [0|7] "" GTW
 SG_ DAS_TR_Obj27_Dx m27 : 8|10@1+ (0.15625,0) [0|159.84375] "m" GTW
 SG_ DAS_TR_Obj27_Dy m27 : 18|6@1+ (0.5,-15.5) [-15.5|16] "m" GTW
 SG_ DAS_TR_Obj27_Vx m27 : 24|8@1+ (0.5,-63.5) [-63.5|64] "m/s" GTW
 SG_ DAS_TR_Obj27_RCS m27 : 32|8@1+ (0.25,-14) [-14|49.75] "dB" GTW
 SG_ DAS_TR_Obj27_Length m27 : 40|6@1+ (0.125,0) [0|7.875] "m" GTW
 SG_ DAS_TR_Obj27_MovingState m27 : 46|2@1+ (1,0) [0|3] "" GTW
 SG_ DAS_TR_Obj27_Dz m27 : 48|6@1+ (0.25,-5) [-5|10.75] "m" GTW
 SG_ DAS_TR_Obj27_Exist m27 : 56|5@1+ (3.125,0) [0|96.875] "%" GTW
 SG_ DAS_TR_Obj28_Class m28 : 5|3@1+ (1,0) [0|7] "" GTW
 SG_ DAS_TR_Obj28_Dx m28 : 8|10@1+ (0.15625,0) [0|159.84375] "m" GTW
 SG_ DAS_TR_Obj28_Dy m28 : 18|6@1+ (0.5,-15.5) [-15.5|16] "m" GTW
 SG_ DAS_TR_Obj28_Vx m28 : 24|8@1+ (0.5,-63.5) [-63.5|64] "m/s" GTW
 SG_ DAS_TR_Obj28_RCS m28 : 32|8@1+ (0.25,-14) [-14|49.75] "dB" GTW
 SG_ DAS_TR_Obj28_Length m28 : 40|6@1+ (0.125,0) [0|7.875] "m" GTW
 SG_ DAS_TR_Obj28_MovingState m28 : 46|2@1+ (1,0) [0|3] "" GTW
 SG_ DAS_TR_Obj28_Dz m28 : 48|6@1+ (0.25,-5) [-5|10.75] "m" GTW
 SG_ DAS_TR_Obj28_Exist m28 : 56|5@1+ (3.125,0) [0|96.875] "%" GTW
 SG_ DAS_TR_Obj29_Class m29 : 5|3@1+ (1,0) [0|7] "" GTW
 SG_ DAS_TR_Obj29_Dx m29 : 8|10@1+ (0.15625,0) [0|159.84375] "m" GTW
 SG_ DAS_TR_Obj29_Dy m29 : 18|6@1+ (0.5,-15.5) [-15.5|16] "m" GTW
 SG_ DAS_TR_Obj29_Vx m29 : 24|8@1+ (0.5,-63.5) [-63.5|64] "m/s" GTW
 SG_ DAS_TR_Obj29_RCS m29 : 32|8@1+ (0.25,-14) [-14|49.75] "dB" GTW
 SG_ DAS_TR_Obj29_Length m29 : 40|6@1+ (0.125,0) [0|7.875] "m" GTW
 SG_ DAS_TR_Obj29_MovingState m29 : 46|2@1+ (1,0) [0|3] "" GTW
 SG_ DAS_TR_Obj29_Dz m29 : 48|6@1+ (0.25,-5) [-5|10.75] "m" GTW
 SG_ DAS_TR_Obj29_Exist m29 : 56|5@1+ (3.125,0) [0|96.875] "%" GTW
 SG_ DAS_TR_Obj30_Class m30 : 5|3@1+ (1,0) [0|7] "" GTW
 SG_ DAS_TR_Obj30_Dx m30 : 8|10@1+ (0.15625,0) [0|159.84375] "m" GTW
 SG_ DAS_TR_Obj30_Dy m30 : 18|6@1+ (0.5,-15.5) [-15.5|16] "m" GTW
 SG_ DAS_TR_Obj30_Vx m30 : 24|8@1+ (0.5,-63.5) [-63.5|64] "m/s" GTW
 SG_ DAS_TR_Obj30_RCS m30 : 32|8@1+ (0.25,-14) [-14|49.75] "dB" GTW
 SG_ DAS_TR_Obj30_Length m30 : 40|6@1+ (0.125,0) [0|7.875] "m" GTW
 SG_ DAS_TR_Obj30_MovingState m30 : 46|2@1+ (1,0) [0|3] "" GTW
 SG_ DAS_TR_Obj30_Dz m30 : 48|6@1+ (0.25,-5) [-5|10.75] "m" GTW
 SG_ DAS_TR_Obj30_Exist m30 : 56|5@1+ (3.125,0) [0|96.875] "%" GTW
 SG_ DAS_TR_Obj31_Class m31 : 5|3@1+ (1,0) [0|7] "" GTW
 SG_ DAS_TR_Obj31_Dx m31 : 8|10@1+ (0.15625,0) [0|159.84375] "m" GTW
 SG_ DAS_TR_Obj31_Dy m31 : 18|6@1+ (0.5,-15.5) [-15.5|16] "m" GTW
 SG_ DAS_TR_Obj31_Vx m31 : 24|8@1+ (0.5,-63.5) [-63.5|64] "m/s" GTW
 SG_ DAS_TR_Obj31_RCS m31 : 32|8@1+ (0.25,-14) [-14|49.75] "dB" GTW
 SG_ DAS_TR_Obj31_Length m31 : 40|6@1+ (0.125,0) [0|7.875] "m" GTW
 SG_ DAS_TR_Obj31_MovingState m31 : 46|2@1+ (1,0) [0|3] "" GTW
 SG_ DAS_TR_Obj31_Dz m31 : 48|6@1+ (0.25,-5) [-5|10.75] "m" GTW
 SG_ DAS_TR_Obj31_Exist m31 : 56|5@1+ (3.125,0) [0|96.875] "%" GTW

BO_ 1625 DAS_udsResponse: 8 DAS
 SG_ DAS_udsResponseData : 7|64@0+ (1,0) [0|0] "" GTW,GTWU

BO_ 1825 DAS_ussThresholdsX: 8 DAS
 SG_ DAS_ussSensorIdX : 0|3@1+ (1,0) [0|7] "" PARK
 SG_ DAS_ussThresholdX0 : 3|5@1+ (1,0) [0|31] "" PARK
 SG_ DAS_ussThresholdX1 : 8|5@1+ (1,0) [0|31] "" PARK
 SG_ DAS_ussThresholdX2 : 13|5@1+ (1,0) [0|31] "" PARK
 SG_ DAS_ussThresholdX3 : 18|5@1+ (1,0) [0|31] "" PARK
 SG_ DAS_ussThresholdX4 : 23|5@1+ (1,0) [0|31] "" PARK
 SG_ DAS_ussThresholdX5 : 28|5@1+ (1,0) [0|31] "" PARK
 SG_ DAS_ussThresholdX6 : 33|5@1+ (1,0) [0|31] "" PARK
 SG_ DAS_ussThresholdX7 : 38|5@1+ (1,0) [0|31] "" PARK
 SG_ DAS_ussThresholdX8 : 43|5@1+ (1,0) [0|31] "" PARK
 SG_ DAS_ussThresholdX9 : 48|5@1+ (1,0) [0|31] "" PARK
 SG_ DAS_ussThresholdX10 : 53|5@1+ (1,0) [0|31] "" PARK
 SG_ DAS_ussThresholdX11 : 58|5@1+ (1,0) [0|31] "" PARK
 SG_ DAS_ussThresholdXControl : 63|1@1+ (1,0) [0|1] "" PARK

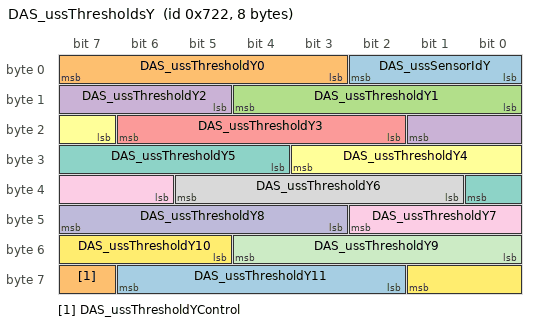
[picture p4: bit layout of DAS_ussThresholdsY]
BO_ 1826 DAS_ussThresholdsY: 8 DAS
 SG_ DAS_ussSensorIdY : 0|3@1+ (1,0) [0|7] "" PARK
 SG_ DAS_ussThresholdY0 : 3|5@1+ (1,0) [0|31] "" PARK
 SG_ DAS_ussThresholdY1 : 8|5@1+ (1,0) [0|31] "" PARK
 SG_ DAS_ussThresholdY2 : 13|5@1+ (1,0) [0|31] "" PARK
 SG_ DAS_ussThresholdY3 : 18|5@1+ (1,0) [0|31] "" PARK
 SG_ DAS_ussThresholdY4 : 23|5@1+ (1,0) [0|31] "" PARK
 SG_ DAS_ussThresholdY5 : 28|5@1+ (1,0) [0|31] "" PARK
 SG_ DAS_ussThresholdY6 : 33|5@1+ (1,0) [0|31] "" PARK
 SG_ DAS_ussThresholdY7 : 38|5@1+ (1,0) [0|31] "" PARK
 SG_ DAS_ussThresholdY8 : 43|5@1+ (1,0) [0|31] "" PARK
 SG_ DAS_ussThresholdY9 : 48|5@1+ (1,0) [0|31] "" PARK
 SG_ DAS_ussThresholdY10 : 53|5@1+ (1,0) [0|31] "" PARK
 SG_ DAS_ussThresholdY11 : 58|5@1+ (1,0) [0|31] "" PARK
 SG_ DAS_ussThresholdYControl : 63|1@1+ (1,0) [0|1] "" PARK

BO_ 585 DAS_visualDebug: 8 DAS
 SG_ DAS_autosteerVehiclesUsage : 4|2@1+ (1,0) [0|3] "" GTW,APS
 SG_ DAS_autosteerHPPUsage : 6|2@1+ (1,0) [0|3] "" GTW,APS
 SG_ DAS_autosteerNavigationUsage : 8|2@1+ (1,0) [0|3] "" GTW,APS
 SG_ DAS_autosteerModelUsage : 10|2@1+ (1,0) [0|3] "" GTW,APS
 SG_ DAS_autosteerBottsDotsUsage : 12|2@1+ (1,0) [0|3] "" GTW,APS
 SG_ DAS_offsetSide : 14|2@1+ (1,0) [0|3] "" GTW,APS
 SG_ DAS_roadSurfaceType : 16|2@1+ (1,0) [0|3] "" GTW,APS
 SG_ DAS_autosteerHealthAnomalyLevel : 18|3@1+ (1,0) [0|5] "" GTW,APS
 SG_ DAS_autosteerHealthState : 21|3@1+ (1,0) [0|5] "" GTW,APS
 SG_ DAS_lastLinePreferenceReason : 24|4@1+ (1,0) [0|15] "" GTW,APS
 SG_ DAS_plannerState : 28|4@1+ (1,0) [0|15] "" GTW,APS
 SG_ DAS_lastAutosteerAbortReason : 32|6@1+ (1,0) [0|63] "" GTW,APS
 SG_ DAS_devAppInterfaceEnabled : 38|1@1+ (1,0) [0|1] "" GTW,APS
 SG_ DAS_navAvailable : 39|1@1+ (1,0) [0|1] "" GTW,APS
 SG_ DAS_navDistance : 40|8@1+ (100,0) [0|25500] "" GTW,APS
 SG_ DAS_accSmartSpeedActive : 48|1@1+ (1,0) [0|1] "" GTW,APS
 SG_ DAS_accSmartSpeedState : 49|3@1+ (1,0) [0|7] "" GTW,APS
 SG_ DAS_ulcInProgress : 52|1@1+ (1,0) [0|0] "" GTW,APS
 SG_ DAS_behaviorType : 56|2@1+ (1,0) [0|3] "" GTW,APS
 SG_ DAS_ulcType : 58|2@1+ (1,0) [0|2] "" GTW,APS
 SG_ DAS_rearVehDetectedThisCycle : 60|1@1+ (1,0) [0|1] "" GTW,APS
 SG_ DAS_rearLeftVehDetectedCurrent : 61|1@1+ (1,0) [0|1] "" GTW,APS
 SG_ DAS_rearRightVehDetectedTrip : 62|1@1+ (1,0) [0|1] "" GTW,APS
 SG_ DAS_rearLeftVehDetectedTrip : 63|1@1+ (1,0) [0|1] "" GTW,APS

BO_ 809 DAS_warningMatrix0: 8 DAS
 SG_ DAS_w002_ldwDisabled : 1|1@1+ (1,0) [0|1] "" GTW,MCU
 SG_ DAS_w003_isaDisabled : 2|1@1+ (1,0) [0|1] "" GTW,MCU
 SG_ DAS_w004_accDisabled : 3|1@1+ (1,0) [0|1] "" GTW,MCU
 SG_ DAS_w005_fcwCancelled : 4|1@1+ (1,0) [0|1] "" GTW,MCU
 SG_ DAS_w006_aebCancelled : 5|1@1+ (1,0) [0|1] "" GTW,MCU
 SG_ DAS_w007_ahlbDisabled : 6|1@1+ (1,0) [0|1] "" GTW,MCU
 SG_ DAS_w008_parkDisabled : 7|1@1+ (1,0) [0|1] "" GTW,MCU
 SG_ DAS_w009_aebFault : 8|1@1+ (1,0) [0|1] "" GTW,MCU
 SG_ DAS_w010_radcCalibIssue : 9|1@1+ (1,0) [0|0] "" GTW,MCU
 SG_ DAS_w011_scaEvent : 10|1@1+ (1,0) [0|0] "" GTW,MCU
 SG_ DAS_w012_Cam_BootFailure : 11|1@1+ (1,0) [0|0] "" GTW,MCU
 SG_ DAS_w013_Cam_Watchdog : 12|1@1+ (1,0) [0|0] "" GTW,MCU
 SG_ DAS_w014_swAssert : 13|1@1+ (1,0) [0|0] "" GTW,MCU
 SG_ DAS_w015_Camera_Failsafes : 14|1@1+ (1,0) [0|0] "" GTW,MCU
 SG_ DAS_w016_aeb_e_event : 15|1@1+ (1,0) [0|0] "" GTW,MCU
 SG_ DAS_w017_Cam_Msg_MIA : 16|1@1+ (1,0) [0|0] "" GTW,MCU
 SG_ DAS_w018_ECU_Power_Issue : 17|1@1+ (1,0) [0|0] "" GTW,MCU
 SG_ DAS_w019_ECU_Stack_Overflow : 18|1@1+ (1,0) [0|0] "" GTW,MCU
 SG_ DAS_w020_ECU_checkstopError : 19|1@1+ (1,0) [0|0] "" GTW,MCU
 SG_ DAS_w021_ECU_Temperature_Issue : 20|1@1+ (1,0) [0|0] "" GTW,MCU
 SG_ DAS_w022_ECU_EEPROM_Failure : 21|1@1+ (1,0) [0|0] "" GTW,MCU
 SG_ DAS_w023_ECU_Cam_Statemismatc : 22|1@1+ (1,0) [0|0] "" GTW,MCU
 SG_ DAS_w024_ECU_Watchdog_Reset : 23|1@1+ (1,0) [0|0] "" GTW,MCU
 SG_ DAS_w025_LC_Steering_Override : 24|1@1+ (1,0) [0|0] "" GTW,MCU
 SG_ DAS_w026_ECU_timingIssue : 25|1@1+ (1,0) [0|0] "" GTW,MCU
 SG_ DAS_w027_ECU_Reset_Fault : 26|1@1+ (1,0) [0|0] "" GTW,MCU
 SG_ DAS_w028_spi_rx_error : 27|1@1+ (1,0) [0|0] "" GTW,MCU
 SG_ DAS_w029_spi_tx_error : 28|1@1+ (1,0) [0|0] "" GTW,MCU
 SG_ DAS_w030_Heater_Issue : 29|1@1+ (1,0) [0|0] "" GTW,MCU
 SG_ DAS_w031_canRxError : 30|1@1+ (1,0) [0|0] "" GTW,MCU
 SG_ DAS_w032_canTxError : 31|1@1+ (1,0) [0|0] "" GTW,MCU
 SG_ DAS_w033_gtwMia : 32|1@1+ (1,0) [0|0] "" GTW,MCU
 SG_ DAS_w034_sccmMia : 33|1@1+ (1,0) [0|0] "" GTW,MCU
 SG_ DAS_w035_espMia : 34|1@1+ (1,0) [0|0] "" GTW,MCU
 SG_ DAS_w036_bdyMia : 35|1@1+ (1,0) [0|0] "" GTW,MCU
 SG_ DAS_w037_camTacIssue : 36|1@1+ (1,0) [0|0] "" GTW,MCU
 SG_ DAS_w038_camFailure : 37|1@1+ (1,0) [0|0] "" GTW,MCU
 SG_ DAS_w039_sdm_rcm_Mia : 38|1@1+ (1,0) [0|0] "" GTW,MCU
 SG_ DAS_w040_autopilotAngleSaturated : 39|1@1+ (1,0) [0|0] "" GTW,MCU
 SG_ DAS_w041_autopilotRateSaturated : 40|1@1+ (1,0) [0|0] "" GTW,MCU
 SG_ DAS_w042_autopilotAborting : 41|1@1+ (1,0) [0|1] "" GTW,MCU
 SG_ DAS_w043_camLongRunTime : 42|1@1+ (1,0) [0|1] "" GTW,MCU
 SG_ DAS_w044_appMobileyeFailure : 43|1@1+ (1,0) [0|0] "" GTW,MCU
 SG_ DAS_w045_radMia : 44|1@1+ (1,0) [0|0] "" GTW,MCU
 SG_ DAS_w046_eepromRecordAbsent : 45|1@1+ (1,0) [0|1] "" GTW,MCU
 SG_ DAS_w047_edrEvent : 46|1@1+ (1,0) [0|0] "" GTW,MCU
 SG_ DAS_w048_DAS_Features_Disabled : 47|1@1+ (1,0) [0|0] "" GTW,MCU
 SG_ DAS_w049_eyeqVersionMismatch : 48|1@1+ (1,0) [0|1] "" GTW,MCU
 SG_ DAS_w050_aeb_event : 49|1@1+ (1,0) [0|1] "" GTW,MCU
 SG_ DAS_w051_radcEcuIssue : 50|1@1+ (1,0) [0|1] "" GTW,MCU
 SG_ DAS_w052_radcSensorIssue : 51|1@1+ (1,0) [0|1] "" GTW,MCU
 SG_ DAS_w053_radcCommIssue : 52|1@1+ (1,0) [0|1] "" GTW,MCU
 SG_ DAS_w054_camAutofix : 53|1@1+ (1,0) [0|1] "" GTW,MCU
 SG_ DAS_w055_radcVersionMismatch : 54|1@1+ (1,0) [0|1] "" GTW,MCU
 SG_ DAS_w056_diMia : 55|1@1+ (1,0) [0|1] "" GTW,MCU
 SG_ DAS_w057_mcuMia : 56|1@1+ (1,0) [0|1] "" GTW,MCU
 SG_ DAS_w058_epbMia : 57|1@1+ (1,0) [0|1] "" GTW,MCU
 SG_ DAS_w059_parkMia : 58|1@1+ (1,0) [0|1] "" GTW,MCU
 SG_ DAS_w060_fcw_event : 59|1@1+ (1,0) [0|1] "" GTW,MCU
 SG_ DAS_w061_airSuspensionMia : 60|1@1+ (1,0) [0|1] "" GTW,MCU
 SG_ DAS_w062_radcAlignment : 61|1@1+ (1,0) [0|1] "" GTW,MCU
 SG_ DAS_w063_parkVersionMismatch : 62|1@1+ (1,0) [0|1] "" GTW,MCU
 SG_ DAS_w064_epasMia : 63|1@1+ (1,0) [0|1] "" GTW,MCU

BO_ 873 DAS_warningMatrix1: 8 DAS
 SG_ DAS_w065_deserializerOvercurrent : 0|1@1+ (1,0) [0|1] "" GTW,MCU
 SG_ DAS_w066_deserializerLockLost : 1|1@1+ (1,0) [0|1] "" GTW,MCU
 SG_ DAS_w067_steeringAlignment : 2|1@1+ (1,0) [0|1] "" GTW,MCU
 SG_ DAS_w068_vlInconsistency : 3|1@1+ (1,0) [0|1] "" GTW,MCU
 SG_ DAS_w069_apcSpaceMasked : 4|1@1+ (1,0) [0|1] "" GTW,MCU
 SG_ DAS_w070_apcIncompleteCal : 5|1@1+ (1,0) [0|1] "" GTW,MCU
 SG_ DAS_w071_selfparkStarted : 6|1@1+ (1,0) [0|1] "" GTW,MCU
 SG_ DAS_w072_selfparkComplete : 7|1@1+ (1,0) [0|1] "" GTW,MCU
 SG_ DAS_w073_issueEscalatedLDW : 8|1@1+ (1,0) [0|1] "" GTW,MCU
 SG_ DAS_w074_inPathStationaryObst : 9|1@1+ (1,0) [0|1] "" GTW,MCU
 SG_ DAS_w075_scMia : 10|1@1+ (1,0) [0|1] "" GTW,MCU
 SG_ DAS_w076_mobilEyeSetC : 11|1@1+ (1,0) [0|1] "" GTW,MCU
 SG_ DAS_w077_pmmActive : 12|1@1+ (1,0) [0|1] "" GTW,MCU
 SG_ DAS_w078_pmmActive2 : 13|1@1+ (1,0) [0|1] "" GTW,MCU
 SG_ DAS_w079_edrAvailable : 14|1@1+ (1,0) [0|1] "" GTW,MCU
 SG_ DAS_w080_accFailedActivation : 15|1@1+ (1,0) [0|1] "" GTW,MCU
 SG_ DAS_w081_pmmActiveBraking : 16|1@1+ (1,0) [0|1] "" GTW,MCU
 SG_ DAS_w082_inPathFSviolation : 17|1@1+ (1,0) [0|1] "" GTW,MCU
 SG_ DAS_w083_inPathRADObject : 18|1@1+ (1,0) [0|1] "" GTW,MCU
 SG_ DAS_w084_pmmIPSO : 19|1@1+ (1,0) [0|1] "" GTW,MCU
 SG_ DAS_w085_pmmSteering : 20|1@1+ (1,0) [0|1] "" GTW,MCU
 SG_ DAS_w086_robCollision : 21|1@1+ (1,0) [0|1] "" GTW,MCU
 SG_ DAS_w087_DEPRECATED : 22|1@1+ (1,0) [0|1] "" GTW,MCU
 SG_ DAS_w088_DEPRECATED : 23|1@1+ (1,0) [0|1] "" GTW,MCU
 SG_ DAS_w089_DEPRECATED : 24|1@1+ (1,0) [0|1] "" GTW,MCU
 SG_ DAS_w090_DEPRECATED : 25|1@1+ (1,0) [0|1] "" GTW,MCU
 SG_ DAS_w091_DEPRECATED : 26|1@1+ (1,0) [0|1] "" GTW,MCU
 SG_ DAS_w092_DEPRECATED : 27|1@1+ (1,0) [0|1] "" GTW,MCU
 SG_ DAS_w093_DEPRECATED : 28|1@1+ (1,0) [0|1] "" GTW,MCU
 SG_ DAS_w094_DEPRECATED : 29|1@1+ (1,0) [0|1] "" GTW,MCU
 SG_ DAS_w095_DEPRECATED : 30|1@1+ (1,0) [0|1] "" GTW,MCU
 SG_ DAS_w096_DEPRECATED : 31|1@1+ (1,0) [0|1] "" GTW,MCU
 SG_ DAS_w097_DEPRECATED : 32|1@1+ (1,0) [0|1] "" GTW,MCU
 SG_ DAS_w098_DEPRECATED : 33|1@1+ (1,0) [0|1] "" GTW,MCU
 SG_ DAS_w099_DEPRECATED : 34|1@1+ (1,0) [0|1] "" GTW,MCU
 SG_ DAS_w100_DEPRECATED : 35|1@1+ (1,0) [0|1] "" GTW,MCU
 SG_ DAS_w101_DEPRECATED : 36|1@1+ (1,0) [0|1] "" GTW,MCU
 SG_ DAS_w102_DEPRECATED : 37|1@1+ (1,0) [0|1] "" GTW,MCU
 SG_ DAS_w103_robExperimentalAEB : 38|1@1+ (1,0) [0|1] "" GTW,MCU
 SG_ DAS_w104_DEPRECATED : 39|1@1+ (1,0) [0|1] "" GTW,MCU
 SG_ DAS_w105_DEPRECATED : 40|1@1+ (1,0) [0|1] "" GTW,MCU
 SG_ DAS_w106_torsionBarCalibrated : 41|1@1+ (1,0) [0|1] "" GTW,MCU

CM_ BO_ 1160 "The message sent to the EPAS to control the haptic feedback requests and external torque/angle control.";
CM_ SG_ 697 DAS_accState "State of traffic-aware cruise control (ACC/TACC).";
CM_ SG_ 697 DAS_controlChecksum "Checksum method for DAS_control: sum of all bytes in message + originating CAN ID (0x2 + 0xb9 = 0xbb).";
CM_ SG_ 1824 DAS_SYNC_EyeQGlobalFrameNum "Mobileye global frame number";
CM_ SG_ 1824 DAS_SYNC_DASLocalTimeStamp "DAS time stamp in millisecond";
CM_ SG_ 665 DAS_safetyFrontChecksum "Checksum method for DAS_safetyFront: sum of all bytes in message + originating CAN ID (0x2 + 0x99 = 0x9b).";
CM_ SG_ 665 DAS_timeToImpactFrontQF "Time to Impact the Front target Qualifier from DAS";
CM_ SG_ 665 DAS_predictedImpactVelFrontQF "The predicted impact velocity or 'closing velocity' Qualifier from DAS";
CM_ SG_ 665 DAS_relativeVelocityFrontQF "Relative Velocity between the Host vehicle and Front target Qualifier from DAS";
CM_ SG_ 665 DAS_targetDistanceFrontQF "Distance between the Host vehicle and Front target Qualifier from DAS";
CM_ SG_ 665 DAS_relativeAccelerationFrontQF "Relative Acceleration between the Host vehicle and Front target Qualifier from DAS";
CM_ SG_ 537 DAS_pscControlChecksum "Message checksum for message: sum of all bytes in message + originating CAN ID (0x2 + 0x19 = 0x1B)";
CM_ SG_ 921 DAS_fusedSpeedLimit "Speed limit unit depends on the current country";
CM_ SG_ 921 DAS_visionOnlySpeedLimit "Speed limit unit depends on the current country";
CM_ SG_ 921 DAS_statusChecksum "Checksum method for DAS_status: sum of all bytes in message + originating CAN ID (0x3 + 0x99 = 0x9c).";
CM_ SG_ 905 DAS_ppOffsetDesiredRamp "Positive value indicates that car should be laterally offset to the right of the lane center. Negative value indicates that car should be laterally offset to the left of the lane center.";
CM_ SG_ 937 DAS_MCPObserved "Was the mobileye Most Critical Pedestrian observed during the monitoring window";
CM_ SG_ 937 DAS_accReengaged "Was ACC re-engaged shortly after the driver cancelled";
CM_ SG_ 937 DAS_pedestrianInFOVBeforeIntr "Did the camera report a pedestrian in the field of view before the intervention";
CM_ SG_ 937 DAS_pedestrianInFOVAfterIntr "Did the camera detect a pedestrian in the field of view after the intervention";
CM_ SG_ 937 DAS_camFreeSpaceBeforeIntr "Did the camera report free-space before the intervention";
CM_ SG_ 937 DAS_camFreeSpaceAfterIntr "Did the camera report free-space after the intervention";
CM_ SG_ 937 DAS_timeOfIntervention "Time of intervention since the auto-resume";
CM_ SG_ 937 DAS_timeOfFirstPedestrian "Time when the first pedestrian was observed since the auto-resume";
CM_ SG_ 937 DAS_timeOfACCReengaging "Time when ACC was reengaged since the auto-resume";
CM_ SG_ 937 DAS_durationOfPrevACCStandstill "How long were we in standstill before we resumed";
CM_ SG_ 937 DAS_maxAbsSteeringWheelAngle "Maximum absolute steering wheel angle since auto-resume";
CM_ SG_ 937 DAS_targetRelvelAtIntervention "Relative velocity of target at intervention";
CM_ SG_ 937 DAS_targetDistAtIntervention "Distance of target at intervention";
CM_ SG_ 937 DAS_egoSpeedAtIntervention "Ego speed at intervention";
BA_DEF_ BO_ "AlertLogSubSystemId" INT 0 0;
BA_DEF_ BO_ "AlertType" INT 0 4;
BA_DEF_ BO_ "AppBotschaft" ENUM "nein","ja";
BA_DEF_ BO_ "DiagRequest" ENUM "No","Yes";
BA_DEF_ BO_ "DiagResponse" ENUM "No","Yes";
BA_DEF_ BO_ "ETHGatewayMessageSendType" ENUM "UseGenMsgSendType","onWrite","noAutoCode";
BA_DEF_ BO_ "ETHId" STRING ;
BA_DEF_ BO_ "GatewayHandlerEnum" ENUM "noHandler","uds","alertLog","messageLogOnReception","udsClient";
BA_DEF_ BO_ "GatewayMessageAtomic" ENUM "No","Yes";
BA_DEF_ BO_ "GatewayMessageSendType" ENUM "UseGenMsgSendType","onWrite","noAutoCode";
BA_DEF_ BO_ "GenMsgCycleTime" INT 0 0;
BA_DEF_ BO_ "GenMsgCycleTimeFast" INT 0 0;
BA_DEF_ BO_ "GenMsgDelayTime" INT 0 0;
BA_DEF_ BO_ "GenMsgForceMiaCheck" ENUM "No","Yes";
BA_DEF_ BO_ "GenMsgGatewayNotification" STRING ;
BA_DEF_ BO_ "GenMsgILSupport" ENUM "No","Yes";
BA_DEF_ BO_ "GenMsgSaltingFunction" ENUM "No","Yes";
BA_DEF_ BO_ "GenMsgSendType" ENUM "Cyclic","NotUsed","NotUsed","NotUsed","NotUsed","NotUsed","NotUsed","IfActive","NoMsgSendType","Sporadic";
BA_DEF_ BO_ "GenMsgStartValue" STRING ;
BA_DEF_ BO_ "GenMsgTimeOut" INT 0 0;
BA_DEF_ BO_ "MessageIdType" ENUM "normal","udsRequest","udsResponse","udsReserved","udsFunctionalRequest","networkManagement","bootloader","xcp","dtc","diagnostic","vendorExempt";
BA_DEF_ BO_ "NWMBotschaft" ENUM "nein","ja";
BA_DEF_ BO_ "NmMessage" ENUM "No","Yes";
BA_DEF_ BO_ "SubSystemId" INT 0 256;
BA_DEF_ BO_ "UsesChecksum" ENUM "No","Yes";
BA_DEF_ SG_ "FieldType" STRING ;
BA_DEF_ SG_ "FlexKomComment" STRING ;
BA_DEF_ SG_ "FlexKomIsMotorola" ENUM "nein","ja";
BA_DEF_ SG_ "FlexKomSID" INT 0 2147483647;
BA_DEF_ SG_ "FlexKomSigLaenge" INT 0 64;
BA_DEF_ SG_ "FlexKomSigName" STRING ;
BA_DEF_ SG_ "FlexKomSigStartPos" INT 0 63;
BA_DEF_ SG_ "FlexKomSigStartValue" STRING ;
BA_DEF_ SG_ "Gatewaysignal" INT 0 1;
BA_DEF_ SG_ "GenSigCycleTime" INT 0 0;
BA_DEF_ SG_ "GenSigCycleTimeActive" INT 0 0;
BA_DEF_ SG_ "GenSigPersistent" ENUM "No","Yes";
BA_DEF_ SG_ "GenSigSNA" STRING ;
BA_DEF_ SG_ "GenSigSendType" ENUM "Cyclic","OnWrite","OnWriteWithRepetition","OnChange","OnChangeWithRepetition","IfActive","IfActiveWithRepetition","NoSigSendType","NotUsed","NotUsed","NotUsed","NotUsed","NotUsed";
BA_DEF_ SG_ "GenSigStartValue" INT 0 0;
BA_DEF_ SG_ "GenSigTimeout_CGW" INT 0 65535;
BA_DEF_ SG_ "GenSigTimeout_DRVU" INT 0 65535;
BA_DEF_ SG_ "GenSigTimeout_ECM" INT 0 65535;
BA_DEF_ SG_ "GenSigTimeout_EIS" INT 0 65535;
BA_DEF_ SG_ "GenSigTimeout_EPS" INT 0 65535;
BA_DEF_ SG_ "GenSigTimeout_ESP_ABR" INT 0 65535;
BA_DEF_ SG_ "GenSigTimeout_IC" INT 0 65535;
BA_DEF_ SG_ "GenSigTimeout_MPC" INT 0 65535;
BA_DEF_ SG_ "GenSigTimeout_NV" INT 0 65535;
BA_DEF_ SG_ "GenSigTimeout_ORC" INT 0 65535;
BA_DEF_ SG_ "GenSigTimeout_PTS" INT 0 65535;
BA_DEF_ SG_ "GenSigTimeout_RBTM_FL" INT 0 65535;
BA_DEF_ SG_ "GenSigTimeout_RBTM_FR" INT 0 65535;
BA_DEF_ SG_ "GenSigTimeout_RDU" INT 0 65535;
BA_DEF_ SG_ "GenSigTimeout_SCCM" INT 0 65535;
BA_DEF_ SG_ "GenSigTimeout_SPC" INT 0 65535;
BA_DEF_ SG_ "GenSigTimeout_TPM" INT 0 65535;
BA_DEF_ SG_ "LogSignal" STRING ;
BA_DEF_ SG_ "PektronUpdateBitType" ENUM "Not used","Has update bit","Is update bit";
BA_DEF_REL_ BU_SG_REL_ "GenSigTimeoutTime" INT 0 0;

BA_DEF_DEF_ "AlertLogSubSystemId" 0;
BA_DEF_DEF_ "AlertType" 4;
BA_DEF_DEF_ "AppBotschaft" "nein";
BA_DEF_DEF_ "DiagRequest" "No";
BA_DEF_DEF_ "DiagResponse" "No";
BA_DEF_DEF_ "ETHGatewayMessageSendType" "UseGenMsgSendType";
BA_DEF_DEF_ "ETHId" "";
BA_DEF_DEF_ "FieldType" "";
BA_DEF_DEF_ "FlexKomComment" "";
BA_DEF_DEF_ "FlexKomIsMotorola" "";
BA_DEF_DEF_ "FlexKomSID" 0;
BA_DEF_DEF_ "FlexKomSigLaenge" 0;
BA_DEF_DEF_ "FlexKomSigName" "";
BA_DEF_DEF_ "FlexKomSigStartPos" 0;
BA_DEF_DEF_ "FlexKomSigStartValue" "";
BA_DEF_DEF_ "GatewayHandlerEnum" "noHandler";
BA_DEF_DEF_ "GatewayMessageAtomic" "No";
BA_DEF_DEF_ "GatewayMessageSendType" "UseGenMsgSendType";
BA_DEF_DEF_ "Gatewaysignal" 0;
BA_DEF_DEF_ "GenMsgCycleTime" 0;
BA_DEF_DEF_ "GenMsgCycleTimeFast" 0;
BA_DEF_DEF_ "GenMsgDelayTime" 0;
BA_DEF_DEF_ "GenMsgForceMiaCheck" "No";
BA_DEF_DEF_ "GenMsgGatewayNotification" "";
BA_DEF_DEF_ "GenMsgILSupport" "Yes";
BA_DEF_DEF_ "GenMsgSaltingFunction" "No";
BA_DEF_DEF_ "GenMsgSendType" "Cyclic";
BA_DEF_DEF_ "GenMsgStartValue" "";
BA_DEF_DEF_ "GenMsgTimeOut" 0;
BA_DEF_DEF_ "GenSigCycleTime" 0;
BA_DEF_DEF_ "GenSigCycleTimeActive" 0;
BA_DEF_DEF_ "GenSigPersistent" "No";
BA_DEF_DEF_ "GenSigSNA" "";
BA_DEF_DEF_ "GenSigSendType" "Cyclic";
BA_DEF_DEF_ "GenSigStartValue" 0;
BA_DEF_DEF_ "GenSigTimeout_CGW" 0;
BA_DEF_DEF_ "GenSigTimeout_DRVU" 0;
BA_DEF_DEF_ "GenSigTimeout_ECM" 0;
BA_DEF_DEF_ "GenSigTimeout_EIS" 0;
BA_DEF_DEF_ "GenSigTimeout_EPS" 0;
BA_DEF_DEF_ "GenSigTimeout_ESP_ABR" 0;
BA_DEF_DEF_ "GenSigTimeout_IC" 0;
BA_DEF_DEF_ "GenSigTimeout_MPC" 0;
BA_DEF_DEF_ "GenSigTimeout_NV" 0;
BA_DEF_DEF_ "GenSigTimeout_ORC" 0;
BA_DEF_DEF_ "GenSigTimeout_PTS" 0;
BA_DEF_DEF_ "GenSigTimeout_RBTM_FL" 0;
BA_DEF_DEF_ "GenSigTimeout_RBTM_FR" 0;
BA_DEF_DEF_ "GenSigTimeout_RDU" 0;
BA_DEF_DEF_ "GenSigTimeout_SCCM" 0;
BA_DEF_DEF_ "GenSigTimeout_SPC" 0;
BA_DEF_DEF_ "GenSigTimeout_TPM" 0;
BA_DEF_DEF_ "LogSignal" "";
BA_DEF_DEF_ "MessageIdType" "normal";
BA_DEF_DEF_ "NWMBotschaft" "nein";
BA_DEF_DEF_ "NmMessage" "No";
BA_DEF_DEF_ "PektronUpdateBitType" "Not used";
BA_DEF_DEF_ "SubSystemId" 0;
BA_DEF_DEF_ "UsesChecksum" "No";
BA_DEF_DEF_REL_ "GenSigTimeoutTime" 0;
BA_ "GenMsgCycleTime" BO_ 1497 333;
BA_ "GenMsgCycleTime" BO_ 1033 100;
BA_ "GatewayMessageSendType" BO_ 697 1;
BA_ "GenMsgCycleTime" BO_ 697 40;
BA_ "GenMsgForceMiaCheck" BO_ 697 1;
BA_ "GatewayHandlerEnum" BO_ 1529 3;
BA_ "GenMsgCycleTime" BO_ 1641 1000;
BA_ "GenMsgCycleTime" BO_ 970 1000;
BA_ "GenMsgCycleTime" BO_ 1337 1000;
BA_ "GenMsgTimeOut" BO_ 1337 1000;
BA_ "GatewayMessageSendType" BO_ 665 1;
BA_ "GenMsgCycleTime" BO_ 665 20;
BA_ "GenMsgCycleTime" BO_ 569 100;
BA_ "GenMsgCycleTime" BO_ 521 40;
BA_ "GenMsgForceMiaCheck" BO_ 521 1;
BA_ "GatewayMessageSendType" BO_ 777 1;
BA_ "GenMsgCycleTime" BO_ 777 30;
BA_ "GenMsgCycleTime" BO_ 537 40;
BA_ "GatewayMessageSendType" BO_ 921 1;
BA_ "GenMsgCycleTime" BO_ 921 500;
BA_ "GatewayMessageSendType" BO_ 905 1;
BA_ "GenMsgCycleTime" BO_ 905 500;
BA_ "GenMsgCycleTime" BO_ 1160 20;
BA_ "GenMsgCycleTime" BO_ 937 100;
BA_ "GenMsgCycleTime" BO_ 985 100;
BA_ "GenMsgCycleTime" BO_ 945 40;
BA_ "GenMsgCycleTime" BO_ 889 40;
BA_ "GenMsgCycleTime" BO_ 1545 5;
BA_ "DiagResponse" BO_ 1625 1;
BA_ "GatewayHandlerEnum" BO_ 1625 4;
BA_ "GenMsgSendType" BO_ 1625 8;
BA_ "MessageIdType" BO_ 1625 2;
BA_ "GenMsgSendType" BO_ 1825 8;
BA_ "GenMsgSendType" BO_ 1826 8;
BA_ "GatewayMessageSendType" BO_ 585 1;
BA_ "GenMsgCycleTime" BO_ 585 100;
BA_ "AlertType" BO_ 809 0;
BA_ "ETHId" BO_ 809 "RETAIN_ID";
BA_ "GatewayMessageSendType" BO_ 809 1;
BA_ "GenMsgCycleTime" BO_ 809 1000;
BA_ "AlertType" BO_ 873 0;
BA_ "ETHId" BO_ 873 "RETAIN_ID";
BA_ "GatewayMessageSendType" BO_ 873 1;
BA_ "GenMsgCycleTime" BO_ 873 1000;
BA_ "FieldType" SG_ 1497 DAS_autosteerUnavailableReason "DAS_autosteerUnavailableReason";
BA_ "LogSignal" SG_ 1497 DAS_autosteerUnavailableReason "onChange";
BA_ "FieldType" SG_ 1497 DAS_alcBehaviorAbortReason "DAS_alcBehaviorAbortReason";
BA_ "LogSignal" SG_ 1497 DAS_alcBehaviorAbortReason "onChange";
BA_ "FieldType" SG_ 1497 DAS_alcBehaviorState "DAS_alcBehaviorState";
BA_ "LogSignal" SG_ 1497 DAS_alcBehaviorState "onChange";
BA_ "LogSignal" SG_ 1497 DAS_radarTarget5_dx "periodic ONE_SECOND driveModeModelS";
BA_ "LogSignal" SG_ 1497 DAS_radarTarget1_dx "periodic ONE_SECOND driveModeModelS";
BA_ "LogSignal" SG_ 1497 DAS_radarTarget1_VxRel "periodic ONE_SECOND driveModeModelS";
BA_ "LogSignal" SG_ 1497 DAS_mobileyeVehAebFlag "onChange";
BA_ "LogSignal" SG_ 1497 DAS_mobileyePedAebFlag "onChange";
BA_ "LogSignal" SG_ 1497 DAS_mobileyeIPSOapproved "onChange";
BA_ "LogSignal" SG_ 1497 DAS_fcmSteeringOverride "onChange";
BA_ "LogSignal" SG_ 1497 DAS_fcmCollisionStage3Checks "onChange";
BA_ "LogSignal" SG_ 1497 DAS_fcmThreatAssesmentMode "onChange";
BA_ "LogSignal" SG_ 1497 DAS_constructionArea "onChange";
BA_ "LogSignal" SG_ 1497 DAS_associated_rad_object "onChange";
BA_ "FieldType" SG_ 1497 DAS_LC_handsOnReason "LC_handsOnReason";
BA_ "LogSignal" SG_ 1497 DAS_LC_handsOnReason "onChange";
BA_ "FieldType" SG_ 1497 DAS_ACC_camStatus "ACC_camStatus";
BA_ "LogSignal" SG_ 1497 DAS_ACC_camStatus "onChange";
BA_ "FieldType" SG_ 1497 DAS_aeb_not_activating_reason "DAS_aeb_not_activating_reason";
BA_ "LogSignal" SG_ 1497 DAS_aeb_not_activating_reason "onChange";
BA_ "FieldType" SG_ 1497 DAS_handsOnDetected "DAS_handsOnDetected";
BA_ "GenSigSNA" SG_ 1497 DAS_handsOnDetected "0";
BA_ "FieldType" SG_ 1497 DAS_driveOnNavUnavailableReason "DON_unavailableReason";
BA_ "LogSignal" SG_ 1497 DAS_driveOnNavUnavailableReason "onChange";
BA_ "FieldType" SG_ 1497 DAS_accUnavailableReason "ACC_unavailableReason";
BA_ "LogSignal" SG_ 1497 DAS_accUnavailableReason "onChange";
BA_ "GenSigSNA" SG_ 1497 DAS_desiredTarget_dx "255";
BA_ "LogSignal" SG_ 1497 DAS_desiredTarget_dx "periodic ONE_SECOND driveModeModelS";
BA_ "LogSignal" SG_ 1497 DAS_radarTarget2_dx "periodic ONE_SECOND driveModeModelS";
BA_ "LogSignal" SG_ 1497 DAS_radarTarget3_dx "periodic ONE_SECOND driveModeModelS";
BA_ "LogSignal" SG_ 1497 DAS_radarTarget4_dx "periodic ONE_SECOND driveModeModelS";
BA_ "FieldType" SG_ 1033 DAS_nmKeepAwakeReason "DAS_NM_keepAwakeReason";
BA_ "GenSigSNA" SG_ 1033 DAS_nmKeepAwakeReason "0";
BA_ "LogSignal" SG_ 1033 DAS_nmKeepAwakeReason "onChange";
BA_ "GenSigSNA" SG_ 697 DAS_setSpeed "4095";
BA_ "GenSigStartValue" SG_ 697 DAS_setSpeed 4095;
BA_ "LogSignal" SG_ 697 DAS_setSpeed "periodic ONE_SECOND driveModeModelS";
BA_ "GenSigSNA" SG_ 697 DAS_accState "15";
BA_ "LogSignal" SG_ 697 DAS_accState "onChange";
BA_ "FieldType" SG_ 697 DAS_aebEvent "DAS_aebEvent";
BA_ "GenSigSNA" SG_ 697 DAS_aebEvent "3";
BA_ "GenSigSNA" SG_ 697 DAS_jerkMin "511";
BA_ "GenSigStartValue" SG_ 697 DAS_jerkMin 511;
BA_ "LogSignal" SG_ 697 DAS_jerkMin "periodic ONE_SECOND driveModeModelS";
BA_ "GenSigSNA" SG_ 697 DAS_jerkMax "255";
BA_ "GenSigStartValue" SG_ 697 DAS_jerkMax 255;
BA_ "LogSignal" SG_ 697 DAS_jerkMax "periodic ONE_SECOND driveModeModelS";
BA_ "GenSigSNA" SG_ 697 DAS_accelMin "511";
BA_ "GenSigStartValue" SG_ 697 DAS_accelMin 511;
BA_ "LogSignal" SG_ 697 DAS_accelMin "periodic ONE_SECOND driveModeModelS";
BA_ "GenSigSNA" SG_ 697 DAS_accelMax "511";
BA_ "GenSigStartValue" SG_ 697 DAS_accelMax 511;
BA_ "LogSignal" SG_ 697 DAS_accelMax "periodic ONE_SECOND driveModeModelS";
BA_ "FieldType" SG_ 1529 DAS_logMltplxr "DAS_logMltplxr";
BA_ "GenSigSNA" SG_ 1824 DAS_SP_instruction "15";
BA_ "GenSigSNA" SG_ 1824 DAS_ACC_tgt_cipv_camID "0";
BA_ "GenSigSNA" SG_ 1824 DAS_ACC_tgt_cipv_radID "63";
BA_ "GenSigSNA" SG_ 1824 DAS_ACC_tgt_cipv2_camID "0";
BA_ "GenSigSNA" SG_ 1824 DAS_ACC_tgt_cipv2_radID "63";
BA_ "GenSigSNA" SG_ 1824 DAS_ACC_tgt_mcvl_camID "0";
BA_ "GenSigSNA" SG_ 1824 DAS_ACC_tgt_mcvl_radID "63";
BA_ "GenSigSNA" SG_ 1824 DAS_ACC_tgt_mcvr_camID "0";
BA_ "GenSigSNA" SG_ 1824 DAS_ACC_tgt_mcvr_radID "63";
BA_ "GenSigSNA" SG_ 1824 DAS_ACC_tgt_cutin_camID "0";
BA_ "GenSigSNA" SG_ 1824 DAS_ACC_tgt_cutin_radID "63";
BA_ "GenSigSNA" SG_ 1824 DAS_ACC_Target6_camID "0";
BA_ "GenSigSNA" SG_ 1824 DAS_ACC_Target6_radID "63";
BA_ "FieldType" SG_ 1824 DAS_LCM_aeb_unavailable_reason "DAS_LCM_aeb_unavailable_reason";
BA_ "GenSigSNA" SG_ 1824 DAS_LCM_aeb_unavailable_reason "4";
BA_ "FieldType" SG_ 1824 DAS_LCM_fcw_unavailable_reason "DAS_LCM_fcw_unavailable_reason";
BA_ "GenSigSNA" SG_ 1824 DAS_LCM_fcw_unavailable_reason "7";
BA_ "FieldType" SG_ 1824 DAS_LCM_CIPV_type "DAS_LCM_CIPV_type";
BA_ "FieldType" SG_ 1824 DAS_LCM_state "DAS_LCM_state";
BA_ "GenSigStartValue" SG_ 1824 DAS_PF_Navigation_STW 4096;
BA_ "GenSigStartValue" SG_ 1824 DAS_PF_VirtualLane_STW 4096;
BA_ "GenSigSNA" SG_ 1824 DAS_VL_Mode "0";
BA_ "FieldType" SG_ 970 DAS_gpsTransportModeState "DAS_gpsTransportModeState";
BA_ "LogSignal" SG_ 970 DAS_gpsTransportModeState "onChange";
BA_ "FieldType" SG_ 970 DAS_gpsWheelsOffMotionDetected "DAS_gpsWheelsOffMotionDetected";
BA_ "LogSignal" SG_ 970 DAS_gpsWheelsOffMotionDetected "onChange";
BA_ "FieldType" SG_ 970 DAS_gpsFixType "DAS_gpsFixType";
BA_ "LogSignal" SG_ 970 DAS_gpsFixType "onChange";
BA_ "LogSignal" SG_ 970 DAS_gpsSatsInUse "onChange";
BA_ "LogSignal" SG_ 970 DAS_gpsWheeltickCounter "onChange";
BA_ "LogSignal" SG_ 970 DAS_gpsWheeltickPulsePeriod "onChange";
BA_ "LogSignal" SG_ 970 DAS_gpsRejectingSatData "onChange";
BA_ "FieldType" SG_ 1337 DAS_infoIndex "DAS_infoIndex";
BA_ "GenSigCycleTime" SG_ 1337 DAS_infoIndex 1000;
BA_ "GenSigStartValue" SG_ 1337 DAS_infoApplicationCRC 4294967295;
BA_ "GenSigCycleTime" SG_ 1337 DAS_infoEyeQBootCRC 1000;
BA_ "GenSigStartValue" SG_ 1337 DAS_infoEyeQBootCRC 4294967295;
BA_ "GenSigStartValue" SG_ 1337 DAS_infoPlatformType 255;
BA_ "GenSigCycleTime" SG_ 1337 DAS_infoEyeQAppCRC 1000;
BA_ "GenSigStartValue" SG_ 1337 DAS_infoEyeQAppCRC 4294967295;
BA_ "GenSigCycleTime" SG_ 1337 DAS_infoEyeQFfsCRC 1000;
BA_ "GenSigStartValue" SG_ 1337 DAS_infoEyeQFfsCRC 4294967295;
BA_ "GenSigSNA" SG_ 665 DAS_timeToImpactFront "511";
BA_ "FieldType" SG_ 569 DAS_leftFork "DAS_fork";
BA_ "LogSignal" SG_ 569 DAS_leftFork "onChange";
BA_ "FieldType" SG_ 569 DAS_rightFork "DAS_fork";
BA_ "LogSignal" SG_ 569 DAS_rightFork "onChange";
BA_ "FieldType" SG_ 521 DAS_locMode "DAS_locMode";
BA_ "FieldType" SG_ 521 DAS_locState "DAS_locState";
BA_ "GenSigSNA" SG_ 521 DAS_locState "7";
BA_ "FieldType" SG_ 521 DAS_locRequest "DAS_locRequest";
BA_ "GenSigSNA" SG_ 521 DAS_locJerkMin "255";
BA_ "GenSigStartValue" SG_ 521 DAS_locJerkMin 255;
BA_ "GenSigSNA" SG_ 521 DAS_locJerkMax "255";
BA_ "GenSigStartValue" SG_ 521 DAS_locJerkMax 255;
BA_ "GenSigSNA" SG_ 521 DAS_locSpeed "2047";
BA_ "GenSigStartValue" SG_ 521 DAS_locSpeed 2047;
BA_ "GenSigSNA" SG_ 521 DAS_locAccelMin "511";
BA_ "GenSigStartValue" SG_ 521 DAS_locAccelMin 511;
BA_ "GenSigSNA" SG_ 521 DAS_locAccelMax "511";
BA_ "GenSigStartValue" SG_ 521 DAS_locAccelMax 511;
BA_ "GenSigSNA" SG_ 777 DAS_leadVehDx "255";
BA_ "LogSignal" SG_ 777 DAS_leadVehDx "periodic ONE_SECOND driveModeModelS";
BA_ "GenSigSNA" SG_ 777 DAS_leadVehVxRel "15";
BA_ "GenSigSNA" SG_ 777 DAS_leadVehId "127";
BA_ "GenSigSNA" SG_ 777 DAS_leadVeh2Dx "255";
BA_ "GenSigSNA" SG_ 777 DAS_leadVeh2VxRel "15";
BA_ "GenSigSNA" SG_ 777 DAS_leadVeh2Id "0";
BA_ "GenSigSNA" SG_ 777 DAS_leftVehDx "255";
BA_ "GenSigSNA" SG_ 777 DAS_leftVehVxRel "15";
BA_ "GenSigSNA" SG_ 777 DAS_leftVehId "127";
BA_ "GenSigSNA" SG_ 777 DAS_leftVeh2Dx "255";
BA_ "GenSigSNA" SG_ 777 DAS_leftVeh2VxRel "15";
BA_ "GenSigSNA" SG_ 777 DAS_leftVeh2Id "0";
BA_ "GenSigSNA" SG_ 777 DAS_rightVehDx "255";
BA_ "GenSigSNA" SG_ 777 DAS_rightVehVxRel "15";
BA_ "GenSigSNA" SG_ 777 DAS_rightVehId "127";
BA_ "GenSigSNA" SG_ 777 DAS_rightVeh2Dx "255";
BA_ "GenSigSNA" SG_ 777 DAS_rightVeh2VxRel "15";
BA_ "GenSigSNA" SG_ 777 DAS_rightVeh2Id "0";
BA_ "GenSigSNA" SG_ 777 DAS_cutinVehDx "255";
BA_ "GenSigSNA" SG_ 777 DAS_cutinVehVxRel "15";
BA_ "GenSigSNA" SG_ 777 DAS_cutinVehId "127";
BA_ "GenSigSNA" SG_ 777 DAS_roadSignId "255";
BA_ "GenSigSNA" SG_ 777 DAS_roadSignStopLineDist "1023";
BA_ "GenSigSNA" SG_ 777 DAS_leadVehHeading "255";
BA_ "GenSigSNA" SG_ 777 DAS_leadVeh2Heading "255";
BA_ "GenSigSNA" SG_ 777 DAS_leftVehHeading "255";
BA_ "GenSigSNA" SG_ 777 DAS_leftVeh2Heading "255";
BA_ "GenSigSNA" SG_ 777 DAS_rightVehHeading "255";
BA_ "GenSigSNA" SG_ 777 DAS_rightVeh2Heading "255";
BA_ "GenSigSNA" SG_ 777 DAS_cutinVehHeading "255";
BA_ "GenSigSNA" SG_ 537 DAS_pscParkState "15";
BA_ "GenSigSNA" SG_ 537 DAS_eacState "4";
BA_ "GenSigSNA" SG_ 921 DAS_autopilotState "15";
BA_ "LogSignal" SG_ 921 DAS_autopilotState "onChange";
BA_ "GenSigSNA" SG_ 921 DAS_blindSpotRearLeft "3";
BA_ "LogSignal" SG_ 921 DAS_blindSpotRearLeft "onChange";
BA_ "GenSigSNA" SG_ 921 DAS_blindSpotRearRight "3";
BA_ "LogSignal" SG_ 921 DAS_blindSpotRearRight "onChange";
BA_ "GenSigSNA" SG_ 921 DAS_fusedSpeedLimit "0";
BA_ "GenSigSNA" SG_ 921 DAS_visionOnlySpeedLimit "0";
BA_ "GenSigSNA" SG_ 921 DAS_heaterState "0";
BA_ "LogSignal" SG_ 921 DAS_heaterState "onChange";
BA_ "GenSigSNA" SG_ 921 DAS_forwardCollisionWarning "3";
BA_ "LogSignal" SG_ 921 DAS_autoparkReady "periodic ONE_SECOND driveModeModelS";
BA_ "FieldType" SG_ 921 DAS_lssState "DAS_lssState";
BA_ "GenSigSNA" SG_ 921 DAS_sideCollisionAvoid "3";
BA_ "LogSignal" SG_ 921 DAS_sideCollisionAvoid "onChange";
BA_ "LogSignal" SG_ 921 DAS_sideCollisionWarning "onChange";
BA_ "GenSigSNA" SG_ 921 DAS_laneDepartureWarning "5";
BA_ "LogSignal" SG_ 921 DAS_fleetSpeedState "onChange";
BA_ "FieldType" SG_ 921 DAS_autopilotHandsOnState "LC_autopilotHandsOnState";
BA_ "GenSigSNA" SG_ 921 DAS_autopilotHandsOnState "15";
BA_ "LogSignal" SG_ 921 DAS_autopilotHandsOnState "onChange";
BA_ "FieldType" SG_ 921 DAS_autoLaneChangeState "TP_autoLaneChangeState";
BA_ "GenSigSNA" SG_ 921 DAS_autoLaneChangeState "31";
BA_ "LogSignal" SG_ 921 DAS_autoLaneChangeState "onChange";
BA_ "GenSigSNA" SG_ 905 DAS_accSpeedLimit "1023";
BA_ "LogSignal" SG_ 905 DAS_accSpeedLimit "onChange";
BA_ "FieldType" SG_ 905 DAS_pmmObstacleSeverity "PMM_obstacleSeverity";
BA_ "GenSigSNA" SG_ 905 DAS_pmmObstacleSeverity "7";
BA_ "FieldType" SG_ 905 DAS_activationFailureStatus "LC_Activation";
BA_ "FieldType" SG_ 905 DAS_pmmUltrasonicsFaultReason "PMM_ultrasonicsFaultReason";
BA_ "LogSignal" SG_ 905 DAS_pmmUltrasonicsFaultReason "periodic HALF_SECOND parkOocValid";
BA_ "FieldType" SG_ 905 DAS_pmmRadarFaultReason "PMM_radarFaultReason";
BA_ "LogSignal" SG_ 905 DAS_pmmRadarFaultReason "periodic HALF_SECOND parkOocValid";
BA_ "FieldType" SG_ 905 DAS_pmmSysFaultReason "PMM_sysFaultReason";
BA_ "LogSignal" SG_ 905 DAS_pmmSysFaultReason "periodic HALF_SECOND parkOocValid";
BA_ "FieldType" SG_ 905 DAS_pmmCameraFaultReason "PMM_cameraFaultReason";
BA_ "LogSignal" SG_ 905 DAS_pmmCameraFaultReason "periodic HALF_SECOND parkOocValid";
BA_ "FieldType" SG_ 905 DAS_ACC_report "ACC_Report";
BA_ "LogSignal" SG_ 905 DAS_ACC_report "onChange";
BA_ "LogSignal" SG_ 905 DAS_csaState "onChange";
BA_ "FieldType" SG_ 905 DAS_radarTelemetry "DAS_radarTelemetry";
BA_ "LogSignal" SG_ 905 DAS_radarTelemetry "onChange";
BA_ "LogSignal" SG_ 905 DAS_robState "onChange";
BA_ "FieldType" SG_ 905 DAS_driverInteractionLevel "DAS_driverInteractionLevel";
BA_ "LogSignal" SG_ 905 DAS_ppOffsetDesiredRamp "periodic ONE_SECOND driveModeModelS";
BA_ "FieldType" SG_ 905 DAS_longCollisionWarning "FCM_longCollisionWarning";
BA_ "GenSigSNA" SG_ 905 DAS_longCollisionWarning "15";
BA_ "LogSignal" SG_ 1160 DAS_steeringAngleRequest "periodic ONE_SECOND driveModeModelS";
BA_ "LogSignal" SG_ 1160 DAS_steeringHapticRequest "onChange";
BA_ "GenSigSNA" SG_ 937 DAS_stopSignLongitudinalDist "1023";
BA_ "GenSigSNA" SG_ 937 DAS_stopSignLateralDist "255";
BA_ "GenSigSNA" SG_ 937 DAS_stopSignHeight "63";
BA_ "GenSigSNA" SG_ 937 DAS_stopSignStopLineDistance "1023";
BA_ "GenSigSNA" SG_ 937 DAS_stopSignCIPVDistance "63";
BA_ "GenSigSNA" SG_ 937 DAS_stopSignHostAccel "1023";
BA_ "GenSigSNA" SG_ 945 DAS_TF_cipvDist "511";
BA_ "GenSigSNA" SG_ 889 DAS_TP_lcState "15";
BA_ "FieldType" SG_ 1545 DAS_TR_Obj00_Class "DAS_radarObjClass";
BA_ "FieldType" SG_ 1545 DAS_TR_Obj00_MovingState "DAS_radarObjMovingState";
BA_ "GenSigSendType" SG_ 1625 DAS_udsResponseData 7;
BA_ "GenSigSNA" SG_ 585 DAS_roadSurfaceType "0";
BA_ "LogSignal" SG_ 585 DAS_plannerState "onChange";
BA_ "FieldType" SG_ 585 DAS_lastAutosteerAbortReason "DAS_lastAutosteerAbortReason";
BA_ "GenSigSNA" SG_ 585 DAS_accSmartSpeedState "7";
BA_ "LogSignal" SG_ 585 DAS_accSmartSpeedState "onChange";
BA_ "LogSignal" SG_ 585 DAS_ulcInProgress "onChange";
BA_ "FieldType" SG_ 585 DAS_ulcType "DAS_ulcType";
BA_ "LogSignal" SG_ 585 DAS_ulcType "onChange";
BA_ "FieldType" SG_ 585 DAS_rearVehDetectedThisCycle "DAS_vehicleDetected";
BA_ "FieldType" SG_ 585 DAS_rearLeftVehDetectedCurrent "DAS_vehicleDetected";
BA_ "FieldType" SG_ 585 DAS_rearRightVehDetectedTrip "DAS_vehicleDetected";
BA_ "LogSignal" SG_ 585 DAS_rearRightVehDetectedTrip "onChange";
BA_ "FieldType" SG_ 585 DAS_rearLeftVehDetectedTrip "DAS_vehicleDetected";
BA_ "LogSignal" SG_ 585 DAS_rearLeftVehDetectedTrip "onChange";
VAL_ 1497 DAS_carLogMultiplexer 3 "PROFILER" 2 "FCM" 1 "RADAR" 0 "FEATURE_STATE" ;
VAL_ 1497 DAS_autosteerUnavailableReason 63 "AUTOSTEER_UNKNOWN" 60 "AUTOSTEER_SYSTEM_HEALTH_CRITICAL" 59 "AUTOSTEER_PERCEPTION_HEALTH_RADAR" 58 "AUTOSTEER_PERCEPTION_HEALTH_VISION" 57 "AUTOSTEER_RADAR_BLIND" 56 "AUTOSTEER_RADAR_FAULT" 55 "AUTOSTEER_RADAR_MIA" 54 "AUTOSTEER_ECU_THERMAL_ISSUE" 53 "AUTOSTEER_AEB_ACTIVE" 52 "AUTOSTEER_AUTOPARK_STATE" 51 "AUTOSTEER_STEERING_WHEEL_ANGLE" 50 "AUTOSTEER_FAILED_AUTOSTEER_ACTIVATION" 49 "AUTOSTEER_INVALID_DI_PEDAL_POS" 48 "AUTOSTEER_INVALID_VEHICLE_SPEED" 47 "AUTOSTEER_AP_NOT_CONFIGURED" 46 "AUTOSTEER_INTEGRATOR_HEALTH_CRITICAL" 45 "AUTOSTEER_RADAR_VERSION_MISMATCH" 44 "AUTOSTEER_TRACKED_OBSTACLE_DETECTED" 43 "AUTOSTEER_SONIC_OBSTACLE_DETECTED" 42 "AUTOSTEER_PEDESTRIAN_PRESENT_OR_NO_VEHICLE" 41 "AUTOSTEER_AVAILABILITY_CHECK_HYSTERESIS" 40 "AUTOSTEER_CAMERA_BLOCKED" 39 "AUTOSTEER_CAMERA_PITCH" 38 "AUTOSTEER_CAMERA_CALIBRATION" 37 "AUTOSTEER_DI_MIA" 36 "AUTOSTEER_GTW_MIA" 35 "AUTOSTEER_EPAS_MIA" 34 "AUTOSTEER_ESP_MIA" 33 "AUTOSTEER_DI_PARTY_MIA" 32 "AUTOSTEER_EPAS_PARTY_MIA" 31 "AUTOSTEER_ESP_PARTY_MIA" 30 "AUTOSTEER_CONTROL_REFERENCE_UNHEALTHY" 29 "AUTOSTEER_CONTROL_STALE_REFERENCE" 28 "AUTOSTEER_CONTROL_STALE_LOCALIZATION" 27 "AUTOSTEER_CONTROL_BAD_UPDATE" 26 "AUTOSTEER_CONTROL_REFERENCE_TOO_SHORT" 25 "AUTOSTEER_CONTROL_INDETERMINATE" 24 "AUTOSTEER_BELOW_MIN_SPEED" 23 "AUTOSTEER_SEATBELT_UNBUCKLED" 22 "AUTOSTEER_EPAS_STEERING_ANGLE_INVALID" 21 "AUTOSTEER_SYNTHESIZED_ACC_LANES_ACTIVE" 20 "AUTOSTEER_MCU_LATERAL_CONTROL_DISABLED" 19 "AUTOSTEER_INVALID_LANE_LINE_TYPE" 18 "AUTOSTEER_ROAD_ESTIMATOR_NOT_ALLOWED" 17 "AUTOSTEER_VEHICLE_SPEED_ABOVE_MAX_HYST" 16 "AUTOSTEER_SPEED_LIMIT_EXCEEDED" 15 "AUTOSTEER_CONTROL_SOLVER_UNHEALTHY" 14 "AUTOSTEER_CONTROL_PATH_UNHEALTHY" 13 "AUTOSTEER_CONTROL_OUTSIDE_LIMITS" 12 "AUTOSTEER_USER_STRIKEOUT" 11 "AUTOSTEER_EAC_REQUEST_TIMEOUT" 10 "AUTOSTEER_HK_RESTRICTED" 9 "AUTOSTEER_TRAILER_MODE_ACTIVE" 8 "AUTOSTEER_CAMERA_FAILSAFES" 7 "AUTOSTEER_STEERING_LIMITS_EXCEEDED" 6 "AUTOSTEER_VEHICLE_SPEED_ABOVE_MAX" 5 "AUTOSTEER_VEHICLE_NOT_IN_DRIVE" 4 "AUTOSTEER_CRUISE_FAULT" 3 "AUTOSTEER_COMPONENT_NOT_READY" 2 "AUTOSTEER_COMPONENT_MIA" 1 "AUTOSTEER_EPAS_EAC_DENIED" 0 "AUTOSTEER_NONE" ;
VAL_ 1497 DAS_alcBehaviorAbortReason 11 "ALC_BEHAVIOR_ABORT_NO_LANE_CHANGE_CONFIRMATION" 10 "ALC_BEHAVIOR_ABORT_REPEATER_DRIVABLE_SPACE" 9 "ALC_BEHAVIOR_ABORT_CLOSE_MOTORCYCLE" 8 "ALC_BEHAVIOR_ABORT_TARGET_ENCROACHMENT" 7 "ALC_BEHAVIOR_ABORT_TARGET_LANE_TOO_FAST" 6 "ALC_BEHAVIOR_ABORT_NO_VALID_INTERVAL" 5 "ALC_BEHAVIOR_ABORT_SLOW_TARGET" 4 "ALC_BEHAVIOR_ABORT_ULTRASOUND" 3 "ALC_BEHAVIOR_ABORT_NO_TARGET_LANE" 2 "ALC_BEHAVIOR_ABORT_HIGH_ALC_PROGRESS_ERROR" 1 "ALC_BEHAVIOR_ABORT_MISSION_PLANNER_REQUEST" 0 "ALC_BEHAVIOR_ABORT_NONE" ;
VAL_ 1497 DAS_alcBehaviorState 6 "ALC_STATE_INVALID" 5 "ALC_STATE_AVAILABLE" 4 "ALC_STATE_TARGET_LANE_BLOCKED" 3 "ALC_STATE_ALIGNING_TO_TRAFFIC" 2 "ALC_STATE_TARGET_LANE_TOO_FAST" 1 "ALC_STATE_IN_PROGRESS" 0 "ALC_STATE_ABORT" ;
VAL_ 1497 DAS_radarTarget5_dx 0 "NO_TARGET" ;
VAL_ 1497 DAS_radarTarget1_dx 0 "NO_TARGET" ;
VAL_ 1497 DAS_radarTarget1_VxRel 0 "NO_TARGET" ;
VAL_ 1497 DAS_fcmThreatAssesmentMode 2 "FCM_STOPLINE_MODE" 1 "FCM_VEHICLE_MODE" 0 "FCM_PEDS_MODE" ;
VAL_ 1497 DAS_constructionArea 3 "BOTH" 2 "RIGHT" 1 "LEFT" 0 "NONE" ;
VAL_ 1497 DAS_associated_rad_object 3 "ACC1" 2 "ACC5" 1 "OTHER" 0 "NONE" ;
VAL_ 1497 DAS_LC_handsOnReason 28 "VISUAL_TRAFFIC_CONTROLS" 27 "CHIME1_EXTREME_WEATHER" 26 "VISUAL_POOR_WEATHER" 25 "VISUAL_STOP_AND_GO" 24 "VISUAL_TIMEOUT_HOMOLOGATION" 23 "VISUAL_ULC_REQUEST" 22 "CHIME1_TOLL_BOOTH" 21 "CHIME1_STATIONARY_RADAR" 20 "CHIME1_DRIVABLE_SPACE_VIOLATION" 19 "CHIME1_RE_DEGRADED_MEASUREMENTS" 18 "CHIME1_NO_LINES" 17 "VISUAL_ALC" 16 "VISUAL_LATERAL_ACCELERATION" 15 "VISUAL_TIMEOUT_ACCELERATOR" 14 "VISUAL_TIMEOUT_RESTRICTED" 13 "VISUAL_TIMEOUT_NO_CIPV" 12 "VISUAL_TIMEOUT_CIPV" 11 "VISUAL_TIMEOUT_CUTOUT_CIPV" 10 "VISUAL_TIMEOUT_CONSTRUCTION" 9 "VISUAL_TIMEOUT_LOW_SPEED" 8 "VISUAL_TIMEOUT_MED_SPEED" 7 "VISUAL_TIMEOUT_HI_SPEED" 6 "VISUAL_TIMEOUT_LONG_TERM" 5 "VISUAL_DRIVER_NOT_PRESENT" 4 "VISUAL_FUSION_MODEL" 3 "VISUAL_FUSION_NAV" 2 "CHIME1_CONSTRUCTION" 1 "CHIME1_ANGLE_SATURATION" 0 "LC_HANDS_ON_REASON_NONE" ;
VAL_ 1497 DAS_ACC_camStatus 3 "ACC_CAM_STATUS_FAULT" 2 "ACC_CAM_STATUS_SQUINTING" 1 "ACC_CAM_STATUS_BLIND" 0 "ACC_CAM_STATUS_HEALTHY" ;
VAL_ 1497 DAS_aeb_not_activating_reason 22 "LCM_AEB_SENSORS_DO_NOT_AGREE" 21 "LCM_AEB_NOT_RADAR_CIPV" 20 "LCM_AEB_LANE_ASSIGNMENT_AGE" 19 "LCM_AEB_COLLISION_COURSE_TIME" 18 "LCM_AEB_TRACK_CONSISTENCY" 17 "LCM_AEB_DRIVABLE_SPACE" 16 "LCM_AEB_PATH_OVERLAP" 15 "LCM_AEB_RAD_NOT_ASSOCIATED" 14 "LCM_AEB_CAM_NOT_ASSOCIATED" 13 "LCM_AEB_CAMERA_CROSS_CHECK" 12 "LCM_AEB_YOUNG_TRACK" 11 "LCM_AEB_OTHER" 10 "LCM_AEB_ACTIVE" 9 "LCM_AEB_OVERRIDE" 8 "LCM_AEB_DELAYED_EVADING_DISTANCE" 7 "LCM_AEB_DELAYED_REQUIRED_ACCELERATION" 6 "LCM_AEB_CURRENT_REQUIRED_ACCELERATION" 5 "LCM_AEB_COLLISION_OVERLAP_RATIO" 4 "LCM_AEB_RELATIVE_VELOCITY" 3 "LCM_AEB_ABSOLUTE_ACCELERATION" 2 "LCM_AEB_NO_COLLISION_OBJECT" 1 "LCM_AEB_UNAVAILABLE" 0 "LCM_AEB_FAULT" ;
VAL_ 1497 DAS_handsOnDetected 2 "HANDS_ON_DETECTED" 1 "HANDS_ON_NOT_DETECTED" 0 "HANDS_ON_SNA" ;
VAL_ 1497 DAS_driveOnNavUnavailableReason 24 "DON_UNAVAILABLE_AUDIO" 23 "DON_SCENE_TAG_SUN_GLARE" 22 "DON_SCENE_TAG_SEVERE_WEATHER" 21 "DON_SCENE_TAG_LENS_FLARE" 20 "DON_SCENE_TAG_FULLY_BLOCKED" 19 "DON_SCENE_TAG_FOG" 18 "DON_SCENE_TAG_BLURRY" 17 "DON_SCENE_TAG_BAD_CAMERA" 16 "DON_NAV_ROUTE_NOT_ACTIVE" 15 "DON_FEATURE_NOT_ENABLED" 14 "DON_AUTOPILOT_UNAVAILABLE" 13 "DON_INCOMPATIBLE_WAY" 12 "DON_HIGH_CURVATURE" 11 "DON_TOLLBOOTH_DETECTED" 10 "DON_CONSTRUCTION_DETECTED" 9 "DON_AUTO_WIPER_ACTIVE" 8 "DON_IMPLAUSIBLE_MAP_DATA" 7 "DON_GPS_DEGRADED" 6 "DON_ULTRASONICS_INVALID" 5 "DON_EDGE_LOCALIZATION_FAILED" 4 "DON_ROUTE_DOWNLOAD_FAILED" 3 "DON_UNAVAILABLE_CAMERA_BLOCKED" 2 "DON_CAMERA_UNAVAILABLE" 1 "DON_INVALID_NAV_GOAL" 0 "DON_UNAVAILABLE_NONE" ;
VAL_ 1497 DAS_accUnavailableReason 47 "ACC_UNAVAILABLE_REASON_IBOOSTER_MIA" 46 "ACC_UNAVAILABLE_INTEGRATOR_HEALTH_CRITICAL" 45 "ACC_UNAVAILABLE_REASON_UNKNOWN" 44 "ACC_UNAVAILABLE_REASON_RADAR_VERSION_MISMATCH" 43 "ACC_UNAVAILABLE_REASON_AP_NOT_CONFIGURED" 42 "ACC_UNAVAILABLE_REASON_INVALID_VEHICLE_SPEED" 41 "ACC_UNAVAILABLE_REASON_INVALID_DI_PEDAL_POS" 40 "ACC_UNAVAILABLE_REASON_W048_FEATURES_DISABLED" 39 "ACC_UNAVAILABLE_REASON_FAILED_AUTOSTEER_ACTIVATION" 38 "ACC_UNAVAILABLE_REASON_AEB_ACTIVE" 37 "ACC_UNAVAILABLE_REASON_AVAILABILITY_CHECK_HYSTERESIS" 36 "ACC_UNAVAILABLE_REASON_SONIC_OBSTACLE_DETECTED" 35 "ACC_UNAVAILABLE_REASON_TRACKED_OBSTACLE_DETECTED" 34 "ACC_UNAVAILABLE_REASON_STEERING_WHEEL_ANGLE" 33 "ACC_UNAVAILABLE_REASON_ROAD_CLASS" 32 "ACC_UNAVAILABLE_REASON_BELOW_MIN_SPEED" 31 "ACC_UNAVAILABLE_REASON_PEDESTRIAN_PRESENT_OR_NO_VEHICLE" 30 "ACC_UNAVAILABLE_REASON_BELOW_MAX_UNAVAILABLE_SPEED" 29 "ACC_UNAVAILABLE_REASON_ESP_PARTY_MIA" 28 "ACC_UNAVAILABLE_REASON_EPAS_PARTY_MIA" 27 "ACC_UNAVAILABLE_REASON_DI_PARTY_MIA" 26 "ACC_UNAVAILABLE_REASON_ECU_THERMAL_ISSUE" 25 "ACC_UNAVAILABLE_REASON_CAMERA_FAILSAFES" 24 "ACC_UNAVAILABLE_REASON_ESP_MIA" 23 "ACC_UNAVAILABLE_REASON_EPAS_MIA" 22 "ACC_UNAVAILABLE_REASON_GTW_MIA" 21 "ACC_UNAVAILABLE_REASON_DI_MIA" 20 "ACC_UNAVAILABLE_REASON_NOT_IN_DRIVE" 19 "ACC_UNAVAILABLE_REASON_CONTROLLER_INDETERMINATE" 18 "ACC_UNAVAILABLE_REASON_CONTROLLER_REFERENCE_TOO_SHORT" 17 "ACC_UNAVAILABLE_REASON_CONTROLLER_BAD_UPDATE" 16 "ACC_UNAVAILABLE_REASON_CONTROLLER_STALE_LOCALIZATION" 15 "ACC_UNAVAILABLE_REASON_CONTROLLER_STALE_REFERENCE" 14 "ACC_UNAVAILABLE_REASON_CONTROLLER_REFERENCE_UNHEALTHY" 13 "ACC_UNAVAILABLE_REASON_CONTROLLER_SOLVER_UNHEALTHY" 12 "ACC_UNAVAILABLE_REASON_CONTROLLER_NOT_ALLOWED" 11 "ACC_UNAVAILABLE_REASON_CAMERA_CALIBRATION" 10 "ACC_UNAVAILABLE_REASON_CAMERA_PITCH" 9 "ACC_UNAVAILABLE_REASON_CAMERA_BLOCKED" 8 "ACC_UNAVAILABLE_REASON_RADAR_MIA" 7 "ACC_UNAVAILABLE_REASON_RADAR_FAULT" 6 "ACC_UNAVAILABLE_REASON_RADAR_BLIND" 5 "ACC_UNAVAILABLE_REASON_PERCEPTION_HEALTH_VISION" 4 "ACC_UNAVAILABLE_REASON_PERCEPTION_HEALTH_RADAR" 3 "ACC_UNAVAILABLE_REASON_DI_CRUISE_STATE_CRITICAL" 2 "ACC_UNAVAILABLE_REASON_AUTOPARK_STATE" 1 "ACC_UNAVAILABLE_REASON_SYSTEM_HEALTH_CRITICAL" 0 "ACC_UNAVAILABLE_REASON_NONE" ;
VAL_ 1497 DAS_desiredTarget_dx 255 "SNA" ;
VAL_ 1497 DAS_radarTarget2_dx 0 "NO_TARGET" ;
VAL_ 1497 DAS_radarTarget3_dx 0 "NO_TARGET" ;
VAL_ 1497 DAS_radarTarget4_dx 0 "NO_TARGET" ;
VAL_ 1033 DAS_nmKeepAwakeReason 2 "DAS_KEEPAWAKE_REASON_TELEMETRY" 1 "DAS_KEEPAWAKE_REASON_PRECONDITIONING" 0 "DAS_KEEPAWAKE_REASON_NONE_SNA" ;
VAL_ 697 DAS_setSpeed 4095 "SNA" ;
VAL_ 697 DAS_accState 15 "FAULT_SNA" 13 "ACC_CANCEL_GENERIC_SILENT" 11 "APC_SELFPARK_START" 10 "APC_UNPARK_COMPLETE" 9 "APC_PAUSE" 8 "APC_ABORT" 7 "APC_COMPLETE" 6 "APC_FORWARD" 5 "APC_BACKWARD" 4 "ACC_ON" 3 "ACC_HOLD" 0 "ACC_CANCEL_GENERIC" ;
VAL_ 697 DAS_aebEvent 3 "AEB_SNA" 2 "AEB_FAULT" 1 "AEB_ACTIVE" 0 "AEB_NOT_ACTIVE" ;
VAL_ 697 DAS_jerkMin 511 "SNA" ;
VAL_ 697 DAS_jerkMax 255 "SNA" ;
VAL_ 697 DAS_accelMin 511 "SNA" ;
VAL_ 697 DAS_accelMax 511 "SNA" ;
VAL_ 1529 DAS_logMltplxr 23 "DAS_L023_PMM_EVENT" 22 "DAS_L022_SCA_EVENT" 21 "DAS_L021_ME_Boot_Msg3" 20 "DAS_L020_ME_Boot_Msg2" 19 "DAS_L019_ME_Boot_Msg1" 18 "DAS_L018_ME_Boot_Msg0" 17 "DAS_L017_MESP_Health_Data" 16 "DAS_L016_Calibration_Reply" 15 "DAS_L015_Vision_Init_Msg_5" 14 "DAS_L014_Vision_Init_Msg_4" 13 "DAS_L013_Vision_Init_Msg_3" 12 "DAS_L012_Vision_Init_Msg_2" 11 "DAS_L011_Vision_Init_Msg_1" 10 "DAS_L010_Vision_Init_Msg_0" ;
VAL_ 1824 DAS_debugMultiplexer 100 "DAS CH Time Sync" 60 "Autowipers" 54 "Virtual Lane Debug5" 53 "Virtual Lane Debug4" 52 "Virtual Lane Debug3" 51 "Virtual Lane Debug2" 50 "Virtual Lane Debug1" 49 "Path_Planner" 48 "TP_LaneChange" 47 "LC_HandsOnDetector" 46 "LC_Planner_Debug" 45 "SCA" 44 "VIRTUAL_WALL_RIGHT" 43 "VIRTUAL_WALL_LEFT" 42 "HEALTH_MONITOR_2" 41 "HEALTH_MONITOR_1" 40 "Lateral Debug1" 33 "FCM Debug4" 32 "FCM Debug3" 31 "FCM Debug2" 30 "FCM Debug1" 29 "ACC Control2" 28 "ACC Control1" 27 "ACC Target6" 26 "ACC Target5" 25 "ACC Target4" 24 "ACC Target3" 23 "ACC Target2" 22 "ACC Target1" 21 "ACC Camera" 20 "ACC State" 12 "I2C debug" 11 "PMM debug" 10 "EyeQ Image Dump" 5 "Road Furniture Debug" 4 "TFL/TSR Debug" 3 "Cam Watchdog Debug" 2 "LDW Debug" 1 "EyeQ Calibrations" 0 "EyeQ Status" ;
VAL_ 1824 DAS_appMobileyeStatus 24 "MOBILEYE_STATUS_UNDEFINED" 23 "MOBILEYE_STATUS_TEARDOWN_FLASH_ACCESS_MODE" 22 "MOBILEYE_STATUS_FLASH_READ_MODE" 21 "MOBILEYE_STATUS_SETUP_FLASH_ACCESS_MODE" 20 "MOBILEYE_STATUS_RUNNING_SPTAC_MODE" 19 "MOBILEYE_STATUS_SPTAC_INIT_SENT" 18 "MOBILEYE_STATUS_WAITING_FOR_SPTAC_INIT" 17 "MOBILEYE_STATUS_BURN_EDR_MODE" 16 "MOBILEYE_STATUS_SPC_INIT_SENT" 15 "MOBILEYE_STATUS_WAITING_FOR_SPC_INIT" 14 "MOBILEYE_STATUS_ERROR" 13 "MOBILEYE_STATUS_LATCHING_FAILURE" 12 "MOBILEYE_STATUS_UPDATING" 11 "MOBILEYE_STATUS_RUNNING_DV_MODE" 10 "MOBILEYE_STATUS_WAITING_FOR_DV" 9 "MOBILEYE_STATUS_RUNNING_TAC_MODE" 8 "MOBILEYE_STATUS_RUNNING_SPC_MODE" 7 "MOBILEYE_STATUS_RUNNING_VISION_MODE" 6 "MOBILEYE_STATUS_TAC_INIT_SENT" 5 "MOBILEYE_STATUS_WAITING_FOR_TAC_INIT" 4 "MOBILEYE_STATUS_VISION_INIT_SENT" 3 "MOBILEYE_STATUS_WAITING_FOR_VISION_INIT" 2 "MOBILEYE_STATUS_WAITING_FOR_BOOT" 1 "MOBILEYE_STATUS_POWER_OFF" 0 "MOBILEYE_STATUS_POWER_CYCLE" ;
VAL_ 1824 DAS_calType 3 "SP-TAC" 2 "SPC" 1 "TAC" 0 "No Cal" ;
VAL_ 1824 DAS_laneMerge 3 "Reserved" 2 "Right Merge" 1 "Left Merge" 0 "No Merge" ;
VAL_ 1824 DAS_Stop_Sign_detected 1 "True" 0 "False" ;
VAL_ 1824 DAS_Stop_Sign_warning 1 "True" 0 "False" ;
VAL_ 1824 DAS_TFL_jnc_status 7 "Reserved_3" 6 "Green" 5 "Yellow" 4 "Red_Yellow" 3 "Red" 2 "Unknown" 1 "Reserved_1" 0 "None" ;
VAL_ 1824 DAS_apcIntState 14 "APC_INT_STATE_CENTER_STW" 13 "APC_INT_STATE_GEAR_CHANGE" 12 "APC_INT_STATE_PARKED" 11 "APC_INT_STATE_COMPLETE_UNPARKED" 10 "APC_INT_STATE_COMPLETE" 9 "APC_INT_STATE_ABORT" 8 "APC_INT_STATE_RESTART" 7 "APC_INT_STATE_PAUSE_USER_CONTROL" 6 "APC_INT_STATE_PAUSE_OBSTACLE_CONTROL" 5 "APC_INT_STATE_REVERSE_CONTROL" 4 "APC_INT_STATE_FORWARD_CONTROL" 3 "APC_INT_STATE_PREGUIDANCE" 2 "APC_INT_STATE_PRECRUISE" 1 "APC_INT_STATE_SEARCHING" 0 "APC_INT_STATE_DISABLED" ;
VAL_ 1824 DAS_SP_instruction 15 "PSC_INSTRUCTION_SNA" 4 "PSC_ABORTED" 3 "PSC_DRIVE_BACKWARD" 2 "PSC_DRIVE_FORWARD" 1 "PSC_STOP" 0 "PSC_NO_INSTRUCTION" ;
VAL_ 1824 DAS_SP_status 6 "SP_GUIDANCE_UNAVAILABLE" 5 "SP_GUIDANCE_FAULT" 4 "SP_GUIDANCE_ABORT" 3 "SP_GUIDANCE_COMPLETE" 2 "SP_GUIDANCE_UNPARK_ACTIVE" 1 "SP_GUIDANCE_PARK_ACTIVE" 0 "SP_GUIDANCE_STANDBY" ;
VAL_ 1824 DAS_estimatedSpeedLimitType 6 "SPEED_LIMIT_TYPE_INVALID" 5 "SPEED_LIMIT_TYPE_RESTRICTED" 4 "SPEED_LIMIT_TYPE_RESUME" 3 "SPEED_LIMIT_TYPE_EGO_VELOCITY" 2 "SPEED_LIMIT_TYPE_FLEET_MEDIAN" 1 "SPEED_LIMIT_TYPE_NAV_MPP" 0 "SPEED_LIMIT_TYPE_VISION" ;
VAL_ 1824 DAS_rampType 2 "RAMP_TYPE_NONE" 1 "RAMP_TYPE_ENTRACE" 0 "RAMP_TYPE_EXIT" ;
VAL_ 1824 DAS_ACC_intState 10 "CANCEL_CAMERAS_NOT_CALIBRATED" 9 "CANCEL_FOR_OBJECT_IN_PATH" 8 "FAULT" 7 "CANCEL_FOR_RADAR_BLINDNESS" 6 "CANCEL_FOR_CAMERA_BLINDNESS" 5 "CANCEL_GENERIC" 4 "READY_TO_RESUME" 3 "HOLD" 2 "STANDSTILL" 1 "ACTIVE" 0 "IDLE" ;
VAL_ 1824 DAS_ACC_camCIPVStatus 4 "FAULT" 3 "CIPV_MATCHES_RAD_CIPV" 2 "CIPV_NOT_RAD_CIPV" 1 "CIPV_NOT_IN_RAD_LIST" 0 "CIPV_NOT_DETECTED" ;
VAL_ 1824 DAS_ACC_radCIPVStatus 3 "FAULT" 2 "CIPV_IN_CAM_LIST" 1 "CIPV_NOT_IN_CAM_LIST" 0 "CIPV_NOT_DETECTED" ;
VAL_ 1824 DAS_ACC_pedestrianStatus 2 "ULTRASONIC_OBJECT" 1 "CAM_FREE_SPACE" 0 "NONE" ;
VAL_ 1824 DAS_ACC_drivingOnHighway 1 "YES" 0 "NO" ;
VAL_ 1824 DAS_ACC_leftLaneExists 1 "YES" 0 "NO" ;
VAL_ 1824 DAS_ACC_rightLaneExists 1 "YES" 0 "NO" ;
VAL_ 1824 DAS_ACC_controlType 4 "ACC_CONTROL_TYPE_MIXED_LC_AND_TARGET" 3 "ACC_CONTROL_TYPE_LC" 2 "ACC_CONTROL_TYPE_TARGET" 1 "ACC_CONTROL_TYPE_CRUISE" 0 "ACC_CONTROL_TYPE_NONE" ;
VAL_ 1824 DAS_ACC_overtakeMode 2 "ACC_OVERTAKE_AUTO_ACTIVE" 1 "ACC_OVERTAKE_AUTO_PENDING" 0 "ACC_OVERTAKE_AUTO_MANUAL" ;
VAL_ 1824 DAS_ACC_camCIPVClass 5 "PEDESTRIAN" 4 "BICYCLE" 3 "MOTORCYCLE" 2 "CAR" 1 "TRUCK" 0 "UNDECIDED" ;
VAL_ 1824 DAS_ACC_camCIPVRelevancy 4 "DANGEROUS" 3 "CUT_IN" 2 "FOLLOWING" 1 "IRRELEVANT" 0 "UNKNOWN" ;
VAL_ 1824 DAS_ACC_camCIPVLane 5 "NEXT_NEXT_RIGHT" 4 "NEXT_NEXT_LEFT" 3 "NEXT_RIGHT" 2 "NEXT_LEFT" 1 "EGO" 0 "NOT_ASSIGNED" ;
VAL_ 1824 DAS_ACC_camCIPVLaneStatus 4 "CUTTING_OUT" 3 "CUTTING_IN" 2 "NOT_IN_EGO_LANE" 1 "IN_EGO_LANE" 0 "UNKNOWN" ;
VAL_ 1824 DAS_ACC_camCIPVBrakeLight 2 "OFF" 1 "ON" 0 "NOT_AVAILABLE" ;
VAL_ 1824 DAS_ACC_camCIPVMotionStatus 8 "ONCOMING_MOVING" 7 "ONCOMING_UNKNOWN" 6 "ONCOMING_STOPPED" 5 "MOVABLE_MOVING" 4 "MOVABLE_UNKNOWN" 3 "MOVABLE_STOPPED" 2 "PARKED" 1 "STANDING" 0 "NOT_DEFINED" ;
VAL_ 1824 DAS_ACC_camCIPVLost 2 "CIPV_LOST" 1 "CIPV_MOVED_OUT_OF_RANGE" 0 "NO_LOSS" ;
VAL_ 1824 DAS_ACC_camCIPVFreeSpace 3 "INVALID" 2 "UNKNOWN" 1 "PEDESTRIAN" 0 "NO_PEDESTRIAN" ;
VAL_ 1824 DAS_ACC_camStopAndGoStatus 3 "NOT_CALCULATED" 2 "UNDECIDED" 1 "RESUME_FROM_STOP" 0 "DO_NOT_RESUME_FROM_STOP" ;
VAL_ 1824 DAS_ACC_camLeftCloseCutin 1 "YES" 0 "NO" ;
VAL_ 1824 DAS_ACC_camRightCloseCutin 1 "YES" 0 "NO" ;
VAL_ 1824 DAS_ACC_camPedestriansPresent 1 "YES" 0 "NO" ;
VAL_ 1824 DAS_ACC_tgt_cipv_camID 0 "SNA" ;
VAL_ 1824 DAS_ACC_tgt_cipv_radID 63 "SNA" ;
VAL_ 1824 DAS_ACC_tgt_cipv_controlState 10 "MCVR_IN_PATH" 9 "MCVR_DPP" 8 "CUT_IN" 7 "CUT_OUT" 6 "OVERTAKE" 5 "PRE_OVERTAKE" 4 "STEADY_STATE" 3 "UNDERTAKE" 2 "DEFAULT" 1 "EVALUATE" 0 "IRRELEVANT" ;
VAL_ 1824 DAS_ACC_tgt_cipv_type 11 "FAULT" 10 "PEDESTRIAN" 9 "IPSO" 8 "TRAFFIC_LIGHT" 7 "STOP_SIGN" 6 "CAMERA_CUTIN" 5 "FUSED_RADAR" 4 "FUSED_CAMERA" 3 "MOVING_RADAR" 2 "STATIONARY_RADAR" 1 "CAMERA" 0 "NONE" ;
VAL_ 1824 DAS_ACC_tgt_cipv2_camID 0 "SNA" ;
VAL_ 1824 DAS_ACC_tgt_cipv2_radID 63 "SNA" ;
VAL_ 1824 DAS_ACC_tgt_cipv2_controlState 10 "MCVR_IN_PATH" 9 "MCVR_DPP" 8 "CUT_IN" 7 "CUT_OUT" 6 "OVERTAKE" 5 "PRE_OVERTAKE" 4 "STEADY_STATE" 3 "UNDERTAKE" 2 "DEFAULT" 1 "EVALUATE" 0 "IRRELEVANT" ;
VAL_ 1824 DAS_ACC_tgt_cipv2_type 11 "FAULT" 10 "PEDESTRIAN" 9 "IPSO" 8 "TRAFFIC_LIGHT" 7 "STOP_SIGN" 6 "CAMERA_CUTIN" 5 "FUSED_RADAR" 4 "FUSED_CAMERA" 3 "MOVING_RADAR" 2 "STATIONARY_RADAR" 1 "CAMERA" 0 "NONE" ;
VAL_ 1824 DAS_ACC_tgt_mcvl_camID 0 "SNA" ;
VAL_ 1824 DAS_ACC_tgt_mcvl_radID 63 "SNA" ;
VAL_ 1824 DAS_ACC_tgt_mcvl_controlState 10 "MCVR_IN_PATH" 9 "MCVR_DPP" 8 "CUT_IN" 7 "CUT_OUT" 6 "OVERTAKE" 5 "PRE_OVERTAKE" 4 "STEADY_STATE" 3 "UNDERTAKE" 2 "DEFAULT" 1 "EVALUATE" 0 "IRRELEVANT" ;
VAL_ 1824 DAS_ACC_tgt_mcvl_type 11 "FAULT" 10 "PEDESTRIAN" 9 "IPSO" 8 "TRAFFIC_LIGHT" 7 "STOP_SIGN" 6 "CAMERA_CUTIN" 5 "FUSED_RADAR" 4 "FUSED_CAMERA" 3 "MOVING_RADAR" 2 "STATIONARY_RADAR" 1 "CAMERA" 0 "NONE" ;
VAL_ 1824 DAS_ACC_tgt_mcvr_camID 0 "SNA" ;
VAL_ 1824 DAS_ACC_tgt_mcvr_radID 63 "SNA" ;
VAL_ 1824 DAS_ACC_tgt_mcvr_controlState 10 "MCVR_IN_PATH" 9 "MCVR_DPP" 8 "CUT_IN" 7 "CUT_OUT" 6 "OVERTAKE" 5 "PRE_OVERTAKE" 4 "STEADY_STATE" 3 "UNDERTAKE" 2 "DEFAULT" 1 "EVALUATE" 0 "IRRELEVANT" ;
VAL_ 1824 DAS_ACC_tgt_mcvr_type 11 "FAULT" 10 "PEDESTRIAN" 9 "IPSO" 8 "TRAFFIC_LIGHT" 7 "STOP_SIGN" 6 "CAMERA_CUTIN" 5 "FUSED_RADAR" 4 "FUSED_CAMERA" 3 "MOVING_RADAR" 2 "STATIONARY_RADAR" 1 "CAMERA" 0 "NONE" ;
VAL_ 1824 DAS_ACC_tgt_cutin_camID 0 "SNA" ;
VAL_ 1824 DAS_ACC_tgt_cutin_radID 63 "SNA" ;
VAL_ 1824 DAS_ACC_tgt_cutin_controlState 10 "MCVR_IN_PATH" 9 "MCVR_DPP" 8 "CUT_IN" 7 "CUT_OUT" 6 "OVERTAKE" 5 "PRE_OVERTAKE" 4 "STEADY_STATE" 3 "UNDERTAKE" 2 "DEFAULT" 1 "EVALUATE" 0 "IRRELEVANT" ;
VAL_ 1824 DAS_ACC_tgt_cutin_type 11 "FAULT" 10 "PEDESTRIAN" 9 "IPSO" 8 "TRAFFIC_LIGHT" 7 "STOP_SIGN" 6 "CAMERA_CUTIN" 5 "FUSED_RADAR" 4 "FUSED_CAMERA" 3 "MOVING_RADAR" 2 "STATIONARY_RADAR" 1 "CAMERA" 0 "NONE" ;
VAL_ 1824 DAS_ACC_Target6_camID 0 "SNA" ;
VAL_ 1824 DAS_ACC_Target6_radID 63 "SNA" ;
VAL_ 1824 DAS_ACC_Target6_controlState 10 "MCVR_IN_PATH" 9 "MCVR_DPP" 8 "CUT_IN" 7 "CUT_OUT" 6 "OVERTAKE" 5 "PRE_OVERTAKE" 4 "STEADY_STATE" 3 "UNDERTAKE" 2 "DEFAULT" 1 "EVALUATE" 0 "IRRELEVANT" ;
VAL_ 1824 DAS_ACC_Target6_type 11 "FAULT" 10 "PEDESTRIAN" 9 "IPSO" 8 "TRAFFIC_LIGHT" 7 "STOP_SIGN" 6 "CAMERA_CUTIN" 5 "FUSED_RADAR" 4 "FUSED_CAMERA" 3 "MOVING_RADAR" 2 "STATIONARY_RADAR" 1 "CAMERA" 0 "NONE" ;
VAL_ 1824 DAS_ACC_Control_targetID 5 "STOP_SIGN_TRAFFIC_LIGHT" 4 "CUT_IN_OR_PEDESTRIAN" 3 "MCVR" 2 "MCVL" 1 "IN_FRONT_OF_CIPV" 0 "CIPV" ;
VAL_ 1824 DAS_ACC_Restrict_targetID 5 "STOP_SIGN_TRAFFIC_LIGHT" 4 "CUT_IN_OR_PEDESTRIAN" 3 "MCVR" 2 "MCVL" 1 "IN_FRONT_OF_CIPV" 0 "CIPV" ;
VAL_ 1824 DAS_IDF_objectClass 5 "PEDESTRIAN" 4 "BICYCLE" 3 "MOTORCYCLE" 2 "CAR" 1 "TRUCK" 0 "UNKNOWN" ;
VAL_ 1824 DAS_IDF_measurementState 2 "EXTRAPOLATED" 1 "MEASURED" 0 "NONE" ;
VAL_ 1824 DAS_LCM_aeb_unavailable_reason 22 "AEB_TRACK_MODE_ACTIVE" 21 "AEB_OFF_ROAD_MODE" 20 "AEB_INERTIATOR_MODE" 19 "AEB_SCENE_ROAD_CONDITIONS" 18 "AEB_ROAD_ESTIMATOR_HEALTH" 17 "AEB_OBJECT_TRACKER_HEALTH" 16 "AEB_DAS_FEATURES_DISABLED" 15 "AEB_STABILITY_CONTROL_FAULT" 14 "AEB_GEAR_ISSUE" 13 "AEB_YAW_RATE_INVALID" 12 "AEB_LONGITUDINAL_ACCELERATION_INVALID" 11 "AEB_VEHICLE_SPEED_INVALID" 10 "AEB_STEERING_ANGLE_RATE_INVALID" 9 "AEB_STEERING_ANGLE_INVALID" 8 "AEB_BRAKE_PEDAL_STATE_INVALID" 7 "AEB_DRIVER_BRAKE_APPLY_INVALID" 6 "AEB_ACCELERATOR_PEDAL_INVALID" 5 "AEB_SEATBELT_STATUS_UNKNOWN" 4 "AEB_TURN_INDICATOR_SNA" 3 "AEB_HIGH_LATERAL_ACCELERATION" 2 "AEB_DI_AEB_STATE_FAULT" 1 "AEB_DI_AEB_STATE_UNAVAILABLE" 0 "AEB_NO_CANCEL" ;
VAL_ 1824 DAS_LCM_fcw_unavailable_reason 18 "FCW_TRACK_MODE_ACTIVE" 17 "FCW_OFF_ROAD_MODE" 16 "FCW_INERTIATOR_MODE" 15 "FCW_SCENE_ROAD_CONDITIONS" 14 "FCW_ROAD_ESTIMATOR_HEALTH" 13 "FCW_OBJECT_TRACKER_HEALTH" 12 "FCW_DAS_FEATURES_DISABLED" 11 "FCW_FCW_SENSITIVITY_INVALID" 10 "FCW_ACCELERATOR_PEDAL_INVALID" 9 "FCW_LONGITUDINAL_ACCELERATION_INVALID" 8 "FCW_YAW_RATE_INVALID" 7 "FCW_TURN_INDICATOR_SNA" 6 "FCW_STABILITY_CONTROL_FAULT" 5 "FCW_GEAR_ISSUE" 4 "FCW_VEHICLE_SPEED_INVALID" 3 "FCW_STEERING_ANGLE_RATE_INVALID" 2 "FCW_STEERING_ANGLE_INVALID" 1 "FCW_DRIVER_BRAKE_APPLY_INVALID" 0 "FCW_NO_CANCEL" ;
VAL_ 1824 DAS_LCM_CIPV_type 3 "TYPE_UNKNOWN" 2 "TYPE_BICYCLIST" 1 "TYPE_PEDESTRIAN" 0 "TYPE_VEHICLE" ;
VAL_ 1824 DAS_LCM_state 10 "LCM_STATE_STATIONARY_MANAGEMENT" 9 "LCM_STATE_AEB_OVERRIDE" 8 "LCM_STATE_AEB_ACTIVE" 7 "LCM_STATE_JERK_OVERRIDE" 6 "LCM_STATE_JERK_ACTIVE" 5 "LCM_STATE_FCW_OVERRIDE" 4 "LCM_STATE_FCW_ACTIVE" 3 "LCM_STATE_AVAILABLE" 2 "LCM_STATE_UNAVAILABLE" 1 "LCM_STATE_OFF" 0 "LCM_STATE_FAULT" ;
VAL_ 1824 DAS_LC_AutopilotInternalState 15 "LC_INTERNAL_STATE_PRECANCEL" 14 "LC_INTERNAL_STATE_DRIVER_STEERING_OVERRIDE" 13 "LC_INTERNAL_STATE_PREABORTED" 12 "LC_INTERNAL_STATE_FAULT" 11 "LC_INTERNAL_STATE_ABORTED" 10 "LC_INTERNAL_STATE_ABORTING" 9 "LC_INTERNAL_STATE_CHECK_ACTIVATION_WHILE_UNAVAILABLE" 8 "LC_INTERNAL_STATE_CHECK_ACTIVATION_WHILE_DISABLED" 7 "LC_INTERNAL_STATE_ACTIVE_RESTRICTED" 6 "LC_INTERNAL_STATE_ACTIVE_NOMINAL" 5 "LC_INTERNAL_STATE_PREACTIVATION" 4 "LC_INTERNAL_STATE_CHECK_FOR_ACTIVATION" 3 "LC_INTERNAL_STATE_AVAILABLE" 2 "LC_INTERNAL_STATE_UNAVAILABLE" 1 "LC_INTERNAL_STATE_DISABLED" 0 "LC_INTERNAL_STATE_NO_AUTOPILOT" ;
VAL_ 1824 DAS_HmLaneViewRangeOAL 5 "ANOMALY_LEVEL_5" 4 "ANOMALY_LEVEL_4" 3 "ANOMALY_LEVEL_3" 2 "ANOMALY_LEVEL_2" 1 "ANOMALY_LEVEL_1" 0 "ANOMALY_LEVEL_0" ;
VAL_ 1824 DAS_HmVlNoInputsOAL 5 "ANOMALY_LEVEL_5" 4 "ANOMALY_LEVEL_4" 3 "ANOMALY_LEVEL_3" 2 "ANOMALY_LEVEL_2" 1 "ANOMALY_LEVEL_1" 0 "ANOMALY_LEVEL_0" ;
VAL_ 1824 DAS_VWall_Left_ultra_dist 500 "NO_OBJECT_DETECTED" ;
VAL_ 1824 DAS_VWall_Right_ultra_dist 500 "NO_OBJECT_DETECTED" ;
VAL_ 1824 DAS_SCA_state 4 "FAULT" 3 "AVOIDANCE" 2 "AVAILABLE" 1 "UNAVAILABLE" 0 "DISABLED" ;
VAL_ 1824 DAS_hands_on_detected 1 "True" 0 "False" ;
VAL_ 1824 DAS_Planner_internalstate 9 "TP_INTSTATE_LANECHANGE_COMPLETE" 8 "TP_INTSTATE_LANECHANGE_JOIN_DEST_LANE" 7 "TP_INTSTATE_LANECHANGE_ABORT" 6 "TP_INTSTATE_LANECHANGE_LEAVE_EGO_LANE" 5 "TP_INTSTATE_LANECHANGE_WAIT_FOR_FWD_OBSTACLE" 4 "TP_INTSTATE_LANECHANGE_WAIT_FOR_SIDE_OBSTACLE" 3 "TP_INTSTATE_LANECHANGE_REQUESTED" 2 "TP_INTSTATE_FOLLOW" 1 "TP_INTSTATE_VL" 0 "TP_INTSTATE_DISABLED" ;
VAL_ 1824 DAS_Planner_externalstate 7 "TP_EXTSTATE_LANECHANGE_ABORT" 6 "TP_EXTSTATE_LANECHANGE_WAIT_FOR_FWD_OBSTACLE" 5 "TP_EXTSTATE_LANECHANGE_WAIT_FOR_SIDE_OBSTACLE" 4 "TP_EXTSTATE_LANECHANGE_IN_PROGRESS" 3 "TP_EXTSTATE_LANECHANGE_REQUESTED" 2 "TP_EXTSTATE_FOLLOW" 1 "TP_EXTSTATE_VL" 0 "TP_EXTSTATE_DISABLED" ;
VAL_ 1824 DAS_csa_internal_state 4 "CSA_INTERNAL_STATE_ENABLE_HOLD" 3 "CSA_INTERNAL_STATE_ENABLE_ACCELEROMETER" 2 "CSA_INTERNAL_STATE_ENABLE_PREDICTED" 1 "CSA_INTERNAL_STATE_AVAILABLE" 0 "CSA_INTERNAL_STATE_UNAVAILABLE" ;
VAL_ 1824 DAS_pp_lanechange_side 2 "NONE" 1 "RIGHT" 0 "LEFT" ;
VAL_ 1824 DAS_VL_WidthMeasType 7 "ONE_LINE_AND_HPP" 6 "NO_MEAS_LOW_SPEED" 5 "HOLDING" 4 "DECAY_TO_NOMINAL" 3 "BOTH_FREESPACE" 2 "RIGHT_LANE_LEFT_FREESPACE" 1 "LEFT_LANE_RIGHT_FREESPACE" 0 "BOTH_LANES" ;
VAL_ 1824 DAS_VL_Mode 9 "FUSED" 8 "NAV" 7 "SUPERNAV" 6 "HPP" 5 "CIPV" 4 "BOTH_LANES" 3 "RIGHT_LANE" 2 "LEFT_LANE" 1 "MODEL" 0 "INIT_SNA" ;
VAL_ 1824 DAS_VL_LinePreference 5 "DRIVING_SIDE" 4 "AVOID_ONCOMING" 3 "NEXT_LANE_EXISTENCE" 2 "NEXT_LANE_LINE_DETECTION" 1 "NEXT_LANE_DEVIATION" 0 "PREFERENCE_NOT_REQUIRED" ;
VAL_ 970 DAS_gpsTransportModeState 1 "DAS_GPS_TRANSPORT_MODE_ON" 0 "DAS_GPS_TRANSPORT_MODE_OFF" ;
VAL_ 970 DAS_gpsWheelsOffMotionDetected 1 "DAS_GPS_MOTION_DETECTED_ON" 0 "DAS_GPS_MOTION_DETECTED_OFF" ;
VAL_ 970 DAS_gpsFixType 6 "DEAD_RECOCKONING_FIX" 5 "FLOAT_RTK_FIX" 4 "REAL_TIME_KINEMATICS_FIX" 3 "PPS_FIX" 2 "DGPS_FIX" 1 "GPS_FIX" 0 "INVALID_FIX" ;
VAL_ 1337 DAS_infoIndex 255 "DAS_INFO_END" 24 "DAS_INFO_EYEQ_FFS" 23 "DAS_INFO_EYEQ_APP" 20 "DAS_INFO_UDS_PROTOCOL_BOOTCRC" 19 "DAS_INFO_VERSION_DEPRECATED" 18 "DAS_INFO_BOOTLOADER_GITHASH" 17 "DAS_INFO_APP_GITHASH" 16 "DAS_INFO_EYEQ_BOOT" 15 "DAS_INFO_BOOTLOADER_CRC" 14 "DAS_INFO_BOOTLOADER_SVN" 13 "DAS_INFO_APP_CRC" 11 "DAS_INFO_PCBAID_ASSYID_USAGEID" 10 "DAS_INFO_BUILD_HWID_COMPONENTID" 9 "DAS_INFO_DEPRECATED_9" 8 "DAS_INFO_DEPRECATED_8" 7 "DAS_INFO_DEPRECATED_7" 6 "DAS_INFO_DEPRECATED_6" 5 "DAS_INFO_DEPRECATED_5" 4 "DAS_INFO_DEPRECATED_4" 3 "DAS_INFO_DEPRECATED_3" 2 "DAS_INFO_DEPRECATED_2" 1 "DAS_INFO_DEPRECATED_1" 0 "DAS_INFO_DEPRECATED_0" ;
VAL_ 1337 DAS_infoHardwareRevision 252 "CONFIGURABLE_HWID_PLACEHOLDER" ;
VAL_ 665 DAS_timeToImpactFront 511 "SNA" ;
VAL_ 665 DAS_timeToImpactFrontQF 1 "NOT_FAULTED" 0 "FAULTED" ;
VAL_ 665 DAS_predictedImpactVelFrontQF 1 "NOT_FAULTED" 0 "FAULTED" ;
VAL_ 665 DAS_relativeVelocityFrontQF 1 "NOT_FAULTED" 0 "FAULTED" ;
VAL_ 665 DAS_targetDistanceFrontQF 1 "NOT_FAULTED" 0 "FAULTED" ;
VAL_ 665 DAS_relativeAccelerationFrontQF 1 "NOT_FAULTED" 0 "FAULTED" ;
VAL_ 665 DAS_imminentCollisionFront 1 "ICF_ACTIVE" 0 "ICF_NOT_ACTIVE" ;
VAL_ 665 DAS_imminentCollisionFrontQF 1 "NOT_FAULTED" 0 "FAULTED" ;
VAL_ 665 DAS_predictedImpactOvrlapFrontQF 1 "NOT_FAULTED" 0 "FAULTED" ;
VAL_ 665 DAS_idfEnableFlag 1 "DAS_IDF_ENABLE_CONTROL" 0 "IDF_DISABLE_CONTROL" ;
VAL_ 569 DAS_leftLineUsage 3 "BLACKLISTED" 2 "FUSED" 1 "AVAILABLE" 0 "REJECTED_UNAVAILABLE" ;
VAL_ 569 DAS_rightLineUsage 3 "BLACKLISTED" 2 "FUSED" 1 "AVAILABLE" 0 "REJECTED_UNAVAILABLE" ;
VAL_ 569 DAS_leftFork 3 "FORK_UNAVAILABLE" 2 "FORK_SELECTED" 1 "FORK_AVAILABLE" 0 "FORK_NONE" ;
VAL_ 569 DAS_rightFork 3 "FORK_UNAVAILABLE" 2 "FORK_SELECTED" 1 "FORK_AVAILABLE" 0 "FORK_NONE" ;
VAL_ 521 DAS_locMode 3 "DAS_LOC_DRIVERLESS" 2 "DAS_LOC_RESTRICTED" 1 "DAS_LOC_NORMAL" 0 "DAS_LOC_OFF" ;
VAL_ 521 DAS_locState 7 "DAS_LOC_FAULT_SNA" 6 "DAS_LOC_AEB_ACTIVE" 2 "DAS_LOC_CANCEL_SILENT" 1 "DAS_LOC_CANCEL_GENERIC" 0 "DAS_LOC_HEALTHY" ;
VAL_ 521 DAS_locRequest 4 "DAS_RQ_PARK" 3 "DAS_RQ_HOLD" 2 "DAS_RQ_BACKWARD" 1 "DAS_RQ_FORWARD" 0 "DAS_RQ_IDLE" ;
VAL_ 521 DAS_locJerkMin 255 "SNA" ;
VAL_ 521 DAS_locJerkMax 255 "SNA" ;
VAL_ 521 DAS_locSpeed 2047 "SNA" ;
VAL_ 521 DAS_locAccelMin 511 "SNA" ;
VAL_ 521 DAS_locAccelMax 511 "SNA" ;
VAL_ 777 DAS_objectId 5 "VEHICLE_HEADINGS" 4 "ROAD_SIGN" 3 "CUTIN_VEHICLE" 2 "RIGHT_VEHICLES" 1 "LEFT_VEHICLES" 0 "LEAD_VEHICLES" ;
VAL_ 777 DAS_leadVehType 6 "IPSO" 5 "PEDESTRIAN" 4 "BICYCLE" 3 "MOTORCYCLE" 2 "CAR" 1 "TRUCK" 0 "UNKNOWN" ;
VAL_ 777 DAS_leadVehDx 255 "SNA" ;
VAL_ 777 DAS_leadVehVxRel 15 "SNA" ;
VAL_ 777 DAS_leadVehId 127 "SNA" ;
VAL_ 777 DAS_leadVeh2Type 5 "PEDESTRIAN" 4 "BICYCLE" 3 "MOTORCYCLE" 2 "CAR" 1 "TRUCK" 0 "UNKNOWN" ;
VAL_ 777 DAS_leadVeh2Dx 255 "SNA" ;
VAL_ 777 DAS_leadVeh2VxRel 15 "SNA" ;
VAL_ 777 DAS_leadVeh2Id 0 "SNA" ;
VAL_ 777 DAS_leftVehType 5 "PEDESTRIAN" 4 "BICYCLE" 3 "MOTORCYCLE" 2 "CAR" 1 "TRUCK" 0 "UNKNOWN" ;
VAL_ 777 DAS_leftVehDx 255 "SNA" ;
VAL_ 777 DAS_leftVehVxRel 15 "SNA" ;
VAL_ 777 DAS_leftVehId 127 "SNA" ;
VAL_ 777 DAS_leftVeh2Type 5 "PEDESTRIAN" 4 "BICYCLE" 3 "MOTORCYCLE" 2 "CAR" 1 "TRUCK" 0 "UNKNOWN" ;
VAL_ 777 DAS_leftVeh2Dx 255 "SNA" ;
VAL_ 777 DAS_leftVeh2VxRel 15 "SNA" ;
VAL_ 777 DAS_leftVeh2Id 0 "SNA" ;
VAL_ 777 DAS_rightVehType 5 "PEDESTRIAN" 4 "BICYCLE" 3 "MOTORCYCLE" 2 "CAR" 1 "TRUCK" 0 "UNKNOWN" ;
VAL_ 777 DAS_rightVehDx 255 "SNA" ;
VAL_ 777 DAS_rightVehVxRel 15 "SNA" ;
VAL_ 777 DAS_rightVehId 127 "SNA" ;
VAL_ 777 DAS_rightVeh2Type 5 "PEDESTRIAN" 4 "BICYCLE" 3 "MOTORCYCLE" 2 "CAR" 1 "TRUCK" 0 "UNKNOWN" ;
VAL_ 777 DAS_rightVeh2Dx 255 "SNA" ;
VAL_ 777 DAS_rightVeh2VxRel 15 "SNA" ;
VAL_ 777 DAS_rightVeh2Id 0 "SNA" ;
VAL_ 777 DAS_cutinVehType 5 "PEDESTRIAN" 4 "BICYCLE" 3 "MOTORCYCLE" 2 "CAR" 1 "TRUCK" 0 "UNKNOWN" ;
VAL_ 777 DAS_cutinVehDx 255 "SNA" ;
VAL_ 777 DAS_cutinVehVxRel 15 "SNA" ;
VAL_ 777 DAS_cutinVehId 127 "SNA" ;
VAL_ 777 DAS_roadSignColor 4 "RED_YELLOW" 3 "GREEN" 2 "YELLOW" 1 "RED" 0 "NONE" ;
VAL_ 777 DAS_roadSignId 255 "SNA" 1 "TRAFFIC_LIGHT" 0 "STOP_SIGN" ;
VAL_ 777 DAS_roadSignStopLineDist 1023 "SNA" ;
VAL_ 777 DAS_roadSignSource 2 "VISION" 1 "NAV" 0 "NONE" ;
VAL_ 777 DAS_roadSignArrow 4 "UNKNOWN" 3 "STRAIGHT" 2 "RIGHT" 1 "LEFT" 0 "CIRCLE" ;
VAL_ 777 DAS_roadSignOrientation 2 "HORIZONTAL_3_LIGHT" 1 "VERTICAL_3_LIGHT" 0 "UNKNOWN" ;
VAL_ 777 DAS_leadVehHeading 255 "SNA" ;
VAL_ 777 DAS_leadVeh2Heading 255 "SNA" ;
VAL_ 777 DAS_leftVehHeading 255 "SNA" ;
VAL_ 777 DAS_leftVeh2Heading 255 "SNA" ;
VAL_ 777 DAS_rightVehHeading 255 "SNA" ;
VAL_ 777 DAS_rightVeh2Heading 255 "SNA" ;
VAL_ 777 DAS_cutinVehHeading 255 "SNA" ;
VAL_ 537 DAS_pscParkState 15 "SNA" 14 "SUMMON" 10 "PAUSE" 9 "SEARCH" 8 "COMPLETE" 7 "ABORT" 6 "PARALLEL_PULL_OUT_TO_RIGHT" 5 "PARALLEL_PULL_OUT_TO_LEFT" 4 "PARK_RIGHT_CROSS" 3 "PARK_RIGHT_PARALLEL" 2 "PARK_LEFT_CROSS" 1 "PARK_LEFT_PARALLEL" 0 "NONE" ;
VAL_ 537 DAS_eacState 4 "SNA" 3 "EAC_FAULT" 2 "EAC_ACTIVE" 1 "EAC_AVAILABLE" 0 "EAC_INHIBITED" ;
VAL_ 1024 DAS_robDebugMultiplexer 5 "ROB_MAP_DEBUG" 4 "ROB_GENERAL_DEBUG" 3 "ROB_EOBJ_03" 2 "ROB_EOBJ_02" 1 "ROB_EOBJ_01" 0 "ROB_EOBJ_00" ;
VAL_ 1024 DAS_robOverlapObstacle 255 "NO_OVERLAP" ;
VAL_ 1024 DAS_robTimeCollision 255 "NO_COLLISION" ;
VAL_ 921 DAS_autopilotState 15 "SNA" 14 "FAULT" 9 "ABORTED" 8 "ABORTING" 5 "ACTIVE_NAV" 4 "ACTIVE_RESTRICTED" 3 "ACTIVE_NOMINAL" 2 "AVAILABLE" 1 "UNAVAILABLE" 0 "DISABLED" ;
VAL_ 921 DAS_blindSpotRearLeft 3 "SNA" 2 "WARNING_LEVEL_2" 1 "WARNING_LEVEL_1" 0 "NO_WARNING" ;
VAL_ 921 DAS_blindSpotRearRight 3 "SNA" 2 "WARNING_LEVEL_2" 1 "WARNING_LEVEL_1" 0 "NO_WARNING" ;
VAL_ 921 DAS_fusedSpeedLimit 31 "NONE" 0 "UNKNOWN_SNA" ;
VAL_ 921 DAS_suppressSpeedWarning 1 "Suppress_Speed_Warning" 0 "Do_Not_Suppress" ;
VAL_ 921 DAS_visionOnlySpeedLimit 31 "NONE" 0 "UNKNOWN_SNA" ;
VAL_ 921 DAS_heaterState 1 "HEATER_ON" 0 "HEATER_OFF_SNA" ;
VAL_ 921 DAS_forwardCollisionWarning 3 "SNA" 1 "FORWARD_COLLISION_WARNING" 0 "NONE" ;
VAL_ 921 DAS_autoparkReady 1 "AUTOPARK_READY" 0 "AUTOPARK_UNAVAILABLE" ;
VAL_ 921 DAS_lssState 7 "LSS_STATE_OFF" 6 "LSS_STATE_ABORT" 5 "LSS_STATE_BLINDSPOT" 4 "LSS_STATE_MONITOR" 3 "LSS_STATE_ELK" 2 "LSS_STATE_LKA" 1 "LSS_STATE_LDW" 0 "LSS_STATE_FAULT" ;
VAL_ 921 DAS_sideCollisionAvoid 3 "SNA" 2 "AVOID_RIGHT" 1 "AVOID_LEFT" 0 "NONE" ;
VAL_ 921 DAS_sideCollisionWarning 3 "WARN_LEFT_RIGHT" 2 "WARN_RIGHT" 1 "WARN_LEFT" 0 "NONE" ;
VAL_ 921 DAS_sideCollisionInhibit 1 "INHIBIT" 0 "NO_INHIBIT" ;
VAL_ 921 DAS_laneDepartureWarning 5 "SNA" 4 "RIGHT_WARNING_SEVERE" 3 "LEFT_WARNING_SEVERE" 2 "RIGHT_WARNING" 1 "LEFT_WARNING" 0 "NONE" ;
VAL_ 921 DAS_fleetSpeedState 3 "FLEETSPEED_HOLD" 2 "FLEETSPEED_ACTIVE" 1 "FLEETSPEED_AVAILABLE" 0 "FLEETSPEED_UNAVAILABLE" ;
VAL_ 921 DAS_autopilotHandsOnState 15 "LC_HANDS_ON_SNA" 10 "LC_HANDS_ON_REQD_ESCALATED_CHIME_2" 9 "LC_HANDS_ON_REQD_ESCALATED_CHIME_1" 8 "LC_HANDS_ON_SUSPENDED" 7 "LC_HANDS_ON_REQD_STRUCK_OUT" 5 "LC_HANDS_ON_REQD_CHIME_2" 4 "LC_HANDS_ON_REQD_CHIME_1" 3 "LC_HANDS_ON_REQD_VISUAL" 2 "LC_HANDS_ON_REQD_NOT_DETECTED" 1 "LC_HANDS_ON_REQD_DETECTED" 0 "LC_HANDS_ON_NOT_REQD" ;
VAL_ 921 DAS_autoLaneChangeState 31 "ALC_SNA" 30 "ALC_ABORT_MISSION_PLAN_INVALID" 29 "ALC_ABORT_TIMEOUT" 28 "ALC_WAITING_HANDS_ON" 27 "ALC_BLOCKED_LANE_TYPE_R" 26 "ALC_BLOCKED_LANE_TYPE_L" 25 "ALC_BLOCKED_VEH_TTC_AND_USS_R" 24 "ALC_BLOCKED_VEH_TTC_R" 23 "ALC_BLOCKED_VEH_TTC_AND_USS_L" 22 "ALC_BLOCKED_VEH_TTC_L" 21 "ALC_UNAVAILABLE_SOLID_LANE_LINE" 20 "ALC_ABORT_OTHER_REASON" 19 "ALC_ABORT_BLINKER_TURNED_OFF" 18 "ALC_ABORT_LC_HEALTH_BAD" 17 "ALC_ABORT_POOR_VIEW_RANGE" 16 "ALC_ABORT_SIDE_OBSTACLE_PRESENT_R" 15 "ALC_ABORT_SIDE_OBSTACLE_PRESENT_L" 14 "ALC_WAITING_FOR_FWD_OBST_TO_PASS_R" 13 "ALC_WAITING_FOR_FWD_OBST_TO_PASS_L" 12 "ALC_WAITING_FOR_SIDE_OBST_TO_PASS_R" 11 "ALC_WAITING_FOR_SIDE_OBST_TO_PASS_L" 10 "ALC_IN_PROGRESS_R" 9 "ALC_IN_PROGRESS_L" 8 "ALC_AVAILABLE_BOTH" 7 "ALC_AVAILABLE_ONLY_R" 6 "ALC_AVAILABLE_ONLY_L" 5 "ALC_UNAVAILABLE_VEHICLE_SPEED" 4 "ALC_UNAVAILABLE_EXITING_HIGHWAY" 3 "ALC_UNAVAILABLE_TP_FOLLOW" 2 "ALC_UNAVAILABLE_SONICS_INVALID" 1 "ALC_UNAVAILABLE_NO_LANES" 0 "ALC_UNAVAILABLE_DISABLED" ;
VAL_ 905 DAS_accSpeedLimit 1023 "SNA" 0 "NONE" ;
VAL_ 905 DAS_pmmObstacleSeverity 7 "PMM_SNA" 6 "PMM_ACCEL_LIMIT" 5 "PMM_CRASH_FRONT" 4 "PMM_CRASH_REAR" 3 "PMM_BRAKE_REQUEST" 2 "PMM_IMMINENT_FRONT" 1 "PMM_IMMINENT_REAR" 0 "PMM_NONE" ;
VAL_ 905 DAS_pmmLoggingRequest 1 "TRUE" 0 "FALSE" ;
VAL_ 905 DAS_activationFailureStatus 2 "LC_ACTIVATION_FAILED_2" 1 "LC_ACTIVATION_FAILED_1" 0 "LC_ACTIVATION_IDLE" ;
VAL_ 905 DAS_pmmUltrasonicsFaultReason 4 "PMM_ULTRASONICS_INVALID_MIA" 3 "PMM_ULTRASONICS_BLOCKED_BOTH" 2 "PMM_ULTRASONICS_BLOCKED_REAR" 1 "PMM_ULTRASONICS_BLOCKED_FRONT" 0 "PMM_ULTRASONICS_NO_FAULT" ;
VAL_ 905 DAS_pmmRadarFaultReason 2 "PMM_RADAR_INVALID_MIA" 1 "PMM_RADAR_BLOCKED_FRONT" 0 "PMM_RADAR_NO_FAULT" ;
VAL_ 905 DAS_pmmSysFaultReason 7 "PMM_FAULT_BRAKE_PEDAL_INHIBIT" 6 "PMM_FAULT_ROAD_TYPE" 5 "PMM_FAULT_DISABLED_BY_USER" 4 "PMM_FAULT_STEERING_ANGLE_RATE" 3 "PMM_FAULT_DI_FAULT" 2 "PMM_FAULT_SPEED" 1 "PMM_FAULT_DAS_DISABLED" 0 "PMM_FAULT_NONE" ;
VAL_ 905 DAS_pmmCameraFaultReason 2 "PMM_CAMERA_INVALID_MIA" 1 "PMM_CAMERA_BLOCKED_FRONT" 0 "PMM_CAMERA_NO_FAULT" ;
VAL_ 905 DAS_ACC_report 24 "ACC_REPORT_BEHAVIOR_REPORT" 23 "ACC_REPORT_CAMERA_ONLY" 22 "ACC_REPORT_RADAR_OBJ_FIVE" 21 "ACC_REPORT_CIPV_CUTTING_OUT" 20 "ACC_REPORT_MCVLR_IN_PATH" 19 "ACC_REPORT_MCVLR_DPP" 18 "ACC_REPORT_FLEET_SPEEDS" 17 "ACC_REPORT_TARGET_MCP" 16 "ACC_REPORT_RADAR_OBJ_TWO" 15 "ACC_REPORT_RADAR_OBJ_ONE" 14 "ACC_REPORT_LC_EXTERNAL_STATE_ACTIVE_RESTRICTED" 13 "ACC_REPORT_LC_EXTERNAL_STATE_ABORTED" 12 "ACC_REPORT_LC_EXTERNAL_STATE_ABORTING" 11 "ACC_REPORT_LC_HANDS_ON_REQD_STRUCK_OUT" 10 "ACC_REPORT_CSA" 9 "ACC_REPORT_TARGET_TYPE_FAULT" 8 "ACC_REPORT_TARGET_TYPE_IPSO" 7 "ACC_REPORT_TARGET_TYPE_TRAFFIC_LIGHT" 6 "ACC_REPORT_TARGET_TYPE_STOP_SIGN" 5 "ACC_REPORT_TARGET_CUTIN" 4 "ACC_REPORT_TARGET_MCVR" 3 "ACC_REPORT_TARGET_MCVL" 2 "ACC_REPORT_TARGET_IN_FRONT_OF_CIPV" 1 "ACC_REPORT_TARGET_CIPV" 0 "ACC_REPORT_TARGET_NONE" ;
VAL_ 905 DAS_csaState 3 "CSA_EXTERNAL_STATE_HOLD" 2 "CSA_EXTERNAL_STATE_ENABLE" 1 "CSA_EXTERNAL_STATE_AVAILABLE" 0 "CSA_EXTERNAL_STATE_UNAVAILABLE" ;
VAL_ 905 DAS_radarTelemetry 2 "RADAR_TELEMETRY_URGENT" 1 "RADAR_TELEMETRY_NORMAL" 0 "RADAR_TELEMETRY_IDLE" ;
VAL_ 905 DAS_robState 3 "ROB_STATE_MAPLESS" 2 "ROB_STATE_ACTIVE" 1 "ROB_STATE_MEASURE" 0 "ROB_STATE_INHIBITED" ;
VAL_ 905 DAS_driverInteractionLevel 2 "CONTINUED_DRIVER_NOT_INTERACTING" 1 "DRIVER_NOT_INTERACTING" 0 "DRIVER_INTERACTING" ;
VAL_ 905 DAS_ppOffsetDesiredRamp 128 "PP_NO_OFFSET" ;
VAL_ 905 DAS_longCollisionWarning 15 "FCM_LONG_COLLISION_WARNING_SNA" 12 "FCM_LONG_COLLISION_WARNING_VEHICLE_CIPV2" 11 "FCM_LONG_COLLISION_WARNING_VEHICLE_MCVR2" 10 "FCM_LONG_COLLISION_WARNING_VEHICLE_MCVR" 9 "FCM_LONG_COLLISION_WARNING_VEHICLE_MCVL2" 8 "FCM_LONG_COLLISION_WARNING_VEHICLE_MCVL" 7 "FCM_LONG_COLLISION_WARNING_VEHICLE_CUTIN" 6 "FCM_LONG_COLLISION_WARNING_VEHICLE_CIPV" 5 "FCM_LONG_COLLISION_WARNING_TFL_STOPLINE" 4 "FCM_LONG_COLLISION_WARNING_STOPSIGN_STOPLINE" 3 "FCM_LONG_COLLISION_WARNING_IPSO" 2 "FCM_LONG_COLLISION_WARNING_PEDESTRIAN" 1 "FCM_LONG_COLLISION_WARNING_VEHICLE_UNKNOWN" 0 "FCM_LONG_COLLISION_WARNING_NONE" ;
VAL_ 1160 DAS_steeringAngleRequest 16384 "ZERO_ANGLE" ;
VAL_ 1160 DAS_steeringHapticRequest 1 "HAPTIC_ACTIVE" 0 "HAPTIC_IDLE" ;
VAL_ 1160 DAS_steeringControlType 3 "EMERGENCY_LANE_KEEP" 2 "LANE_KEEP_ASSIST" 1 "ANGLE_CONTROL" 0 "NONE" ;
VAL_ 937 DAS_telemetryMultiplexer 9 "DAS_TELEMETRY_CRUISE_STALK_INPUT" 8 "DAS_TELEMETRY_STATIONARY_OBST" 7 "DAS_TELEMETRY_CSA_EVENT" 2 "DAS_TELEMETRY_TRAFFIC_SIGNS" 1 "DAS_TELEMETRY_ACC_DRIVER_MONITOR" 0 "DAS_TELEMETRY_ROAD_INFORMATION" ;
VAL_ 937 DAS_telLeftLaneType 6 "BARRIER" 5 "BOTTS DOTS" 4 "DOUBLE" 3 "DASHED" 2 "ROAD EDGE" 1 "SOLID" 0 "UNDECIDED" ;
VAL_ 937 DAS_telRightLaneType 6 "BARRIER" 5 "BOTTS DOTS" 4 "DOUBLE" 3 "DASHED" 2 "ROAD EDGE" 1 "SOLID" 0 "UNDECIDED" ;
VAL_ 937 DAS_telLeftMarkerQuality 3 "HIGH" 2 "MEDIUM" 1 "LOW" 0 "LOWEST" ;
VAL_ 937 DAS_telRightMarkerQuality 3 "HIGH" 2 "MEDIUM" 1 "LOW" 0 "LOWEST" ;
VAL_ 937 DAS_telLeftMarkerColor 3 "BLUE" 2 "YELLOW" 1 "WHITE" 0 "UNKNOWN" ;
VAL_ 937 DAS_telRightMarkerColor 3 "BLUE" 2 "YELLOW" 1 "WHITE" 0 "UNKNOWN" ;
VAL_ 937 DAS_telLeftLaneCrossing 1 "CROSSING" 0 "NOT_CROSSING" ;
VAL_ 937 DAS_telRightLaneCrossing 1 "CROSSING" 0 "NOT_CROSSING" ;
VAL_ 937 DAS_stopSignLongitudinalDist 1023 "SNA" ;
VAL_ 937 DAS_stopSignLateralDist 255 "SNA" ;
VAL_ 937 DAS_stopSignHeight 63 "SNA" ;
VAL_ 937 DAS_stopSignStopLineDistance 1023 "SNA" ;
VAL_ 937 DAS_stopSignCIPVDistance 63 "SNA" ;
VAL_ 937 DAS_stopSignHostAccel 1023 "SNA" ;
VAL_ 937 DAS_csaIntState 4 "CSA_INTERNAL_STATE_ENABLE_HOLD" 3 "CSA_INTERNAL_STATE_ENABLE_ACCELEROMETER" 2 "CSA_INTERNAL_STATE_ENABLE_PREDICTED" 1 "CSA_INTERNAL_STATE_AVAILABLE" 0 "CSA_INTERNAL_STATE_UNAVAILABLE" ;
VAL_ 937 DAS_soCamCipvStatus 3 "CAM_CIPV_FUSED_W_RAD5" 2 "CAM_CIPV_FUSED_W_OTHER_RAD_OBJ" 1 "CAM_CIPV_UNFUSED" 0 "CAM_CIPV_INVALID" ;
VAL_ 937 DAS_soRad5Status 3 "RAD5_FUSED_W_OTHER_CAMOBJ" 2 "RAD5_FUSED_W_CIPV" 1 "RAD5_UNFUSED" 0 "RAD5_INVALID" ;
VAL_ 937 DAS_soRad1Status 3 "RAD1_FUSED_W_OTHER_CAMOBJ" 2 "RAD1_FUSED_W_CIPV" 1 "RAD1_UNFUSED" 0 "RAD1_INVALID" ;
VAL_ 985 DAS_TE_multiplexer 9 "END" 8 "IPSO" 7 "FCM" 6 "ACC" 5 "VL" 4 "NAV" 3 "HPP" 2 "RIGHT_LANE" 1 "LEFT_LANE" 0 "START" ;
VAL_ 985 DAS_TE_eventType 14 "TM_EVENT_ROB" 13 "TM_EVENT_AEB" 12 "TM_EVENT_CRASH" 11 "TM_EVENT_IPSO" 10 "SCA_RIGHT" 9 "SCA_LEFT" 8 "ALC_ABORT_RIGHT" 7 "ALC_ABORT_LEFT" 6 "LDW_RIGHT" 5 "LDW_LEFT" 4 "ANGLE_RATE_SATURATION" 3 "ANGLE_SATURATION" 2 "AUTOSTEER_ABORT" 1 "DRIVER_INTERVENTION" 0 "NONE" ;
VAL_ 985 DAS_TE_lcAbortReason 31 "NO_ABORT" 30 "CAMERA_FAILSAFES" 29 "ACC_CANCEL" 28 "EPAS_ERROR_CODE" 27 "PLANNER_OUTPUT_INVALID" 26 "FOLLOWER_OUTPUT_INVALID" 25 "VEHICLE_SPEED_ABOVE_MAX" 24 "DRIVING_OFF_NAV" 23 "CID_SWITCH_DISABLED" 22 "CRUISE_FAULT" 21 "COMPONENT_MIA" 20 "EPAS_EAC_DENIED" 19 "SIDE_COLLISION_IMMINENT" 18 "TRAILER_MODE" 17 "CAM_WATCHDOG" 16 "CAM_MSG_MIA" 1 "HM_VIRTUAL_LANE_NO_INPUTS" 0 "HM_LANE_VIEW_RANGE" ;
VAL_ 945 DAS_TF_multiplexer 2 "TFL_DATA" 1 "FURNITURE_DATA" 0 "ENVIRONMENT_DATA" ;
VAL_ 945 DAS_TF_llType 7 "INVALID" 6 "BARRIER" 5 "BOTTS_DOTS" 4 "DOUBLE_LANE" 3 "DASHED" 2 "ROAD_EDGE" 1 "SOLID" 0 "UNDECIDED" ;
VAL_ 945 DAS_TF_rlType 7 "INVALID" 6 "BARRIER" 5 "BOTTS_DOTS" 4 "DOUBLE_LANE" 3 "DASHED" 2 "ROAD_EDGE" 1 "SOLID" 0 "UNDECIDED" ;
VAL_ 945 DAS_TF_cipvDist 511 "SNA" ;
VAL_ 945 DAS_TF_transmissionStatus 2 "FINAL" 1 "INTERMEDIATE" 0 "INITIAL" ;
VAL_ 889 DAS_TP_multiplexer 9 "END" 8 "LANE_INFO" 7 "RIGHT_BOTTS_DOTS" 6 "LEFT_BOTTS_DOTS" 5 "VIRTUAL_LANE" 4 "NAV" 3 "HPP" 2 "RIGHT_LANE" 1 "LEFT_LANE" 0 "START" ;
VAL_ 889 DAS_TP_laneChange 2 "RIGHT" 1 "LEFT" 0 "NONE" ;
VAL_ 889 DAS_TP_llType 7 "INVALID" 6 "BARRIER" 5 "BOTTS_DOTS" 4 "DOUBLE_LANE" 3 "DASHED" 2 "ROAD_EDGE" 1 "SOLID" 0 "UNDECIDED" ;
VAL_ 889 DAS_TP_rlType 7 "INVALID" 6 "BARRIER" 5 "BOTTS_DOTS" 4 "DOUBLE_LANE" 3 "DASHED" 2 "ROAD_EDGE" 1 "SOLID" 0 "UNDECIDED" ;
VAL_ 889 DAS_TP_plannerState 7 "LANECHANGE_ABORT" 6 "LANECHANGE_WAIT_FOR_FWD_OBSTACLE" 5 "LANECHANGE_WAIT_FOR_SIDE_OBSTACLE" 4 "LANECHANGE_IN_PROGRESS" 3 "LANECHANGE_REQUESTED" 2 "FOLLOW" 1 "VIRTUAL_LANE" 0 "DISABLED" ;
VAL_ 889 DAS_TP_lcState 15 "SNA" 14 "FAULT" 9 "ABORTED" 8 "ABORTING" 4 "ACTIVE_RESTRICTED" 3 "ACTIVE_NOMINAL" 2 "AVAILABLE" 1 "UNAVAILABLE" 0 "DISABLED" ;
VAL_ 889 DAS_TP_llQltyME 3 "HIGH" 2 "MEDIUM" 1 "LOW" 0 "LOWEST" ;
VAL_ 889 DAS_TP_rlQltyME 3 "HIGH" 2 "MEDIUM" 1 "LOW" 0 "LOWEST" ;
VAL_ 889 DAS_TP_bdlQltyME 3 "HIGH" 2 "MEDIUM" 1 "LOW" 0 "LOWEST" ;
VAL_ 889 DAS_TP_bdrQltyME 3 "HIGH" 2 "MEDIUM" 1 "LOW" 0 "LOWEST" ;
VAL_ 1545 DAS_TR_Obj00_Class 4 "RADAR_CLASS_CONSTRUCTION_ELEMENT" 3 "RADAR_CLASS_MOVING_PEDESTRIAN" 2 "RADAR_CLASS_MOVING_TWO_WHEEL_VEHICLE" 1 "RADAR_CLASS_MOVING_FOUR_WHEEL_VEHICLE" 0 "RADAR_CLASS_UNKNOWN" ;
VAL_ 1545 DAS_TR_Obj00_MovingState 3 "RADAR_MOVESTATE_STANDING" 2 "RADAR_MOVESTATE_STOPPED" 1 "RADAR_MOVESTATE_MOVING" 0 "RADAR_MOVESTATE_INDETERMINATE" ;
VAL_ 1545 DAS_TR_Obj01_Class 4 "RADAR_CLASS_CONSTRUCTION_ELEMENT" 3 "RADAR_CLASS_MOVING_PEDESTRIAN" 2 "RADAR_CLASS_MOVING_TWO_WHEEL_VEHICLE" 1 "RADAR_CLASS_MOVING_FOUR_WHEEL_VEHICLE" 0 "RADAR_CLASS_UNKNOWN" ;
VAL_ 1545 DAS_TR_Obj01_MovingState 3 "RADAR_MOVESTATE_STANDING" 2 "RADAR_MOVESTATE_STOPPED" 1 "RADAR_MOVESTATE_MOVING" 0 "RADAR_MOVESTATE_INDETERMINATE" ;
VAL_ 1545 DAS_TR_Obj02_Class 4 "RADAR_CLASS_CONSTRUCTION_ELEMENT" 3 "RADAR_CLASS_MOVING_PEDESTRIAN" 2 "RADAR_CLASS_MOVING_TWO_WHEEL_VEHICLE" 1 "RADAR_CLASS_MOVING_FOUR_WHEEL_VEHICLE" 0 "RADAR_CLASS_UNKNOWN" ;
VAL_ 1545 DAS_TR_Obj02_MovingState 3 "RADAR_MOVESTATE_STANDING" 2 "RADAR_MOVESTATE_STOPPED" 1 "RADAR_MOVESTATE_MOVING" 0 "RADAR_MOVESTATE_INDETERMINATE" ;
VAL_ 1545 DAS_TR_Obj03_Class 4 "RADAR_CLASS_CONSTRUCTION_ELEMENT" 3 "RADAR_CLASS_MOVING_PEDESTRIAN" 2 "RADAR_CLASS_MOVING_TWO_WHEEL_VEHICLE" 1 "RADAR_CLASS_MOVING_FOUR_WHEEL_VEHICLE" 0 "RADAR_CLASS_UNKNOWN" ;
VAL_ 1545 DAS_TR_Obj03_MovingState 3 "RADAR_MOVESTATE_STANDING" 2 "RADAR_MOVESTATE_STOPPED" 1 "RADAR_MOVESTATE_MOVING" 0 "RADAR_MOVESTATE_INDETERMINATE" ;
VAL_ 1545 DAS_TR_Obj04_Class 4 "RADAR_CLASS_CONSTRUCTION_ELEMENT" 3 "RADAR_CLASS_MOVING_PEDESTRIAN" 2 "RADAR_CLASS_MOVING_TWO_WHEEL_VEHICLE" 1 "RADAR_CLASS_MOVING_FOUR_WHEEL_VEHICLE" 0 "RADAR_CLASS_UNKNOWN" ;
VAL_ 1545 DAS_TR_Obj04_MovingState 3 "RADAR_MOVESTATE_STANDING" 2 "RADAR_MOVESTATE_STOPPED" 1 "RADAR_MOVESTATE_MOVING" 0 "RADAR_MOVESTATE_INDETERMINATE" ;
VAL_ 1545 DAS_TR_Obj05_Class 4 "RADAR_CLASS_CONSTRUCTION_ELEMENT" 3 "RADAR_CLASS_MOVING_PEDESTRIAN" 2 "RADAR_CLASS_MOVING_TWO_WHEEL_VEHICLE" 1 "RADAR_CLASS_MOVING_FOUR_WHEEL_VEHICLE" 0 "RADAR_CLASS_UNKNOWN" ;
VAL_ 1545 DAS_TR_Obj05_MovingState 3 "RADAR_MOVESTATE_STANDING" 2 "RADAR_MOVESTATE_STOPPED" 1 "RADAR_MOVESTATE_MOVING" 0 "RADAR_MOVESTATE_INDETERMINATE" ;
VAL_ 1545 DAS_TR_Obj06_Class 4 "RADAR_CLASS_CONSTRUCTION_ELEMENT" 3 "RADAR_CLASS_MOVING_PEDESTRIAN" 2 "RADAR_CLASS_MOVING_TWO_WHEEL_VEHICLE" 1 "RADAR_CLASS_MOVING_FOUR_WHEEL_VEHICLE" 0 "RADAR_CLASS_UNKNOWN" ;
VAL_ 1545 DAS_TR_Obj06_MovingState 3 "RADAR_MOVESTATE_STANDING" 2 "RADAR_MOVESTATE_STOPPED" 1 "RADAR_MOVESTATE_MOVING" 0 "RADAR_MOVESTATE_INDETERMINATE" ;
VAL_ 1545 DAS_TR_Obj07_Class 4 "RADAR_CLASS_CONSTRUCTION_ELEMENT" 3 "RADAR_CLASS_MOVING_PEDESTRIAN" 2 "RADAR_CLASS_MOVING_TWO_WHEEL_VEHICLE" 1 "RADAR_CLASS_MOVING_FOUR_WHEEL_VEHICLE" 0 "RADAR_CLASS_UNKNOWN" ;
VAL_ 1545 DAS_TR_Obj07_MovingState 3 "RADAR_MOVESTATE_STANDING" 2 "RADAR_MOVESTATE_STOPPED" 1 "RADAR_MOVESTATE_MOVING" 0 "RADAR_MOVESTATE_INDETERMINATE" ;
VAL_ 1545 DAS_TR_Obj08_Class 4 "RADAR_CLASS_CONSTRUCTION_ELEMENT" 3 "RADAR_CLASS_MOVING_PEDESTRIAN" 2 "RADAR_CLASS_MOVING_TWO_WHEEL_VEHICLE" 1 "RADAR_CLASS_MOVING_FOUR_WHEEL_VEHICLE" 0 "RADAR_CLASS_UNKNOWN" ;
VAL_ 1545 DAS_TR_Obj08_MovingState 3 "RADAR_MOVESTATE_STANDING" 2 "RADAR_MOVESTATE_STOPPED" 1 "RADAR_MOVESTATE_MOVING" 0 "RADAR_MOVESTATE_INDETERMINATE" ;
VAL_ 1545 DAS_TR_Obj09_Class 4 "RADAR_CLASS_CONSTRUCTION_ELEMENT" 3 "RADAR_CLASS_MOVING_PEDESTRIAN" 2 "RADAR_CLASS_MOVING_TWO_WHEEL_VEHICLE" 1 "RADAR_CLASS_MOVING_FOUR_WHEEL_VEHICLE" 0 "RADAR_CLASS_UNKNOWN" ;
VAL_ 1545 DAS_TR_Obj09_MovingState 3 "RADAR_MOVESTATE_STANDING" 2 "RADAR_MOVESTATE_STOPPED" 1 "RADAR_MOVESTATE_MOVING" 0 "RADAR_MOVESTATE_INDETERMINATE" ;
VAL_ 1545 DAS_TR_Obj10_Class 4 "RADAR_CLASS_CONSTRUCTION_ELEMENT" 3 "RADAR_CLASS_MOVING_PEDESTRIAN" 2 "RADAR_CLASS_MOVING_TWO_WHEEL_VEHICLE" 1 "RADAR_CLASS_MOVING_FOUR_WHEEL_VEHICLE" 0 "RADAR_CLASS_UNKNOWN" ;
VAL_ 1545 DAS_TR_Obj10_MovingState 3 "RADAR_MOVESTATE_STANDING" 2 "RADAR_MOVESTATE_STOPPED" 1 "RADAR_MOVESTATE_MOVING" 0 "RADAR_MOVESTATE_INDETERMINATE" ;
VAL_ 1545 DAS_TR_Obj11_Class 4 "RADAR_CLASS_CONSTRUCTION_ELEMENT" 3 "RADAR_CLASS_MOVING_PEDESTRIAN" 2 "RADAR_CLASS_MOVING_TWO_WHEEL_VEHICLE" 1 "RADAR_CLASS_MOVING_FOUR_WHEEL_VEHICLE" 0 "RADAR_CLASS_UNKNOWN" ;
VAL_ 1545 DAS_TR_Obj11_MovingState 3 "RADAR_MOVESTATE_STANDING" 2 "RADAR_MOVESTATE_STOPPED" 1 "RADAR_MOVESTATE_MOVING" 0 "RADAR_MOVESTATE_INDETERMINATE" ;
VAL_ 1545 DAS_TR_Obj12_Class 4 "RADAR_CLASS_CONSTRUCTION_ELEMENT" 3 "RADAR_CLASS_MOVING_PEDESTRIAN" 2 "RADAR_CLASS_MOVING_TWO_WHEEL_VEHICLE" 1 "RADAR_CLASS_MOVING_FOUR_WHEEL_VEHICLE" 0 "RADAR_CLASS_UNKNOWN" ;
VAL_ 1545 DAS_TR_Obj12_MovingState 3 "RADAR_MOVESTATE_STANDING" 2 "RADAR_MOVESTATE_STOPPED" 1 "RADAR_MOVESTATE_MOVING" 0 "RADAR_MOVESTATE_INDETERMINATE" ;
VAL_ 1545 DAS_TR_Obj13_Class 4 "RADAR_CLASS_CONSTRUCTION_ELEMENT" 3 "RADAR_CLASS_MOVING_PEDESTRIAN" 2 "RADAR_CLASS_MOVING_TWO_WHEEL_VEHICLE" 1 "RADAR_CLASS_MOVING_FOUR_WHEEL_VEHICLE" 0 "RADAR_CLASS_UNKNOWN" ;
VAL_ 1545 DAS_TR_Obj13_MovingState 3 "RADAR_MOVESTATE_STANDING" 2 "RADAR_MOVESTATE_STOPPED" 1 "RADAR_MOVESTATE_MOVING" 0 "RADAR_MOVESTATE_INDETERMINATE" ;
VAL_ 1545 DAS_TR_Obj14_Class 4 "RADAR_CLASS_CONSTRUCTION_ELEMENT" 3 "RADAR_CLASS_MOVING_PEDESTRIAN" 2 "RADAR_CLASS_MOVING_TWO_WHEEL_VEHICLE" 1 "RADAR_CLASS_MOVING_FOUR_WHEEL_VEHICLE" 0 "RADAR_CLASS_UNKNOWN" ;
VAL_ 1545 DAS_TR_Obj14_MovingState 3 "RADAR_MOVESTATE_STANDING" 2 "RADAR_MOVESTATE_STOPPED" 1 "RADAR_MOVESTATE_MOVING" 0 "RADAR_MOVESTATE_INDETERMINATE" ;
VAL_ 1545 DAS_TR_Obj15_Class 4 "RADAR_CLASS_CONSTRUCTION_ELEMENT" 3 "RADAR_CLASS_MOVING_PEDESTRIAN" 2 "RADAR_CLASS_MOVING_TWO_WHEEL_VEHICLE" 1 "RADAR_CLASS_MOVING_FOUR_WHEEL_VEHICLE" 0 "RADAR_CLASS_UNKNOWN" ;
VAL_ 1545 DAS_TR_Obj15_MovingState 3 "RADAR_MOVESTATE_STANDING" 2 "RADAR_MOVESTATE_STOPPED" 1 "RADAR_MOVESTATE_MOVING" 0 "RADAR_MOVESTATE_INDETERMINATE" ;
VAL_ 1545 DAS_TR_Obj16_Class 4 "RADAR_CLASS_CONSTRUCTION_ELEMENT" 3 "RADAR_CLASS_MOVING_PEDESTRIAN" 2 "RADAR_CLASS_MOVING_TWO_WHEEL_VEHICLE" 1 "RADAR_CLASS_MOVING_FOUR_WHEEL_VEHICLE" 0 "RADAR_CLASS_UNKNOWN" ;
VAL_ 1545 DAS_TR_Obj16_MovingState 3 "RADAR_MOVESTATE_STANDING" 2 "RADAR_MOVESTATE_STOPPED" 1 "RADAR_MOVESTATE_MOVING" 0 "RADAR_MOVESTATE_INDETERMINATE" ;
VAL_ 1545 DAS_TR_Obj17_Class 4 "RADAR_CLASS_CONSTRUCTION_ELEMENT" 3 "RADAR_CLASS_MOVING_PEDESTRIAN" 2 "RADAR_CLASS_MOVING_TWO_WHEEL_VEHICLE" 1 "RADAR_CLASS_MOVING_FOUR_WHEEL_VEHICLE" 0 "RADAR_CLASS_UNKNOWN" ;
VAL_ 1545 DAS_TR_Obj17_MovingState 3 "RADAR_MOVESTATE_STANDING" 2 "RADAR_MOVESTATE_STOPPED" 1 "RADAR_MOVESTATE_MOVING" 0 "RADAR_MOVESTATE_INDETERMINATE" ;
VAL_ 1545 DAS_TR_Obj18_Class 4 "RADAR_CLASS_CONSTRUCTION_ELEMENT" 3 "RADAR_CLASS_MOVING_PEDESTRIAN" 2 "RADAR_CLASS_MOVING_TWO_WHEEL_VEHICLE" 1 "RADAR_CLASS_MOVING_FOUR_WHEEL_VEHICLE" 0 "RADAR_CLASS_UNKNOWN" ;
VAL_ 1545 DAS_TR_Obj18_MovingState 3 "RADAR_MOVESTATE_STANDING" 2 "RADAR_MOVESTATE_STOPPED" 1 "RADAR_MOVESTATE_MOVING" 0 "RADAR_MOVESTATE_INDETERMINATE" ;
VAL_ 1545 DAS_TR_Obj19_Class 4 "RADAR_CLASS_CONSTRUCTION_ELEMENT" 3 "RADAR_CLASS_MOVING_PEDESTRIAN" 2 "RADAR_CLASS_MOVING_TWO_WHEEL_VEHICLE" 1 "RADAR_CLASS_MOVING_FOUR_WHEEL_VEHICLE" 0 "RADAR_CLASS_UNKNOWN" ;
VAL_ 1545 DAS_TR_Obj19_MovingState 3 "RADAR_MOVESTATE_STANDING" 2 "RADAR_MOVESTATE_STOPPED" 1 "RADAR_MOVESTATE_MOVING" 0 "RADAR_MOVESTATE_INDETERMINATE" ;
VAL_ 1545 DAS_TR_Obj20_Class 4 "RADAR_CLASS_CONSTRUCTION_ELEMENT" 3 "RADAR_CLASS_MOVING_PEDESTRIAN" 2 "RADAR_CLASS_MOVING_TWO_WHEEL_VEHICLE" 1 "RADAR_CLASS_MOVING_FOUR_WHEEL_VEHICLE" 0 "RADAR_CLASS_UNKNOWN" ;
VAL_ 1545 DAS_TR_Obj20_MovingState 3 "RADAR_MOVESTATE_STANDING" 2 "RADAR_MOVESTATE_STOPPED" 1 "RADAR_MOVESTATE_MOVING" 0 "RADAR_MOVESTATE_INDETERMINATE" ;
VAL_ 1545 DAS_TR_Obj21_Class 4 "RADAR_CLASS_CONSTRUCTION_ELEMENT" 3 "RADAR_CLASS_MOVING_PEDESTRIAN" 2 "RADAR_CLASS_MOVING_TWO_WHEEL_VEHICLE" 1 "RADAR_CLASS_MOVING_FOUR_WHEEL_VEHICLE" 0 "RADAR_CLASS_UNKNOWN" ;
VAL_ 1545 DAS_TR_Obj21_MovingState 3 "RADAR_MOVESTATE_STANDING" 2 "RADAR_MOVESTATE_STOPPED" 1 "RADAR_MOVESTATE_MOVING" 0 "RADAR_MOVESTATE_INDETERMINATE" ;
VAL_ 1545 DAS_TR_Obj22_Class 4 "RADAR_CLASS_CONSTRUCTION_ELEMENT" 3 "RADAR_CLASS_MOVING_PEDESTRIAN" 2 "RADAR_CLASS_MOVING_TWO_WHEEL_VEHICLE" 1 "RADAR_CLASS_MOVING_FOUR_WHEEL_VEHICLE" 0 "RADAR_CLASS_UNKNOWN" ;
VAL_ 1545 DAS_TR_Obj22_MovingState 3 "RADAR_MOVESTATE_STANDING" 2 "RADAR_MOVESTATE_STOPPED" 1 "RADAR_MOVESTATE_MOVING" 0 "RADAR_MOVESTATE_INDETERMINATE" ;
VAL_ 1545 DAS_TR_Obj23_Class 4 "RADAR_CLASS_CONSTRUCTION_ELEMENT" 3 "RADAR_CLASS_MOVING_PEDESTRIAN" 2 "RADAR_CLASS_MOVING_TWO_WHEEL_VEHICLE" 1 "RADAR_CLASS_MOVING_FOUR_WHEEL_VEHICLE" 0 "RADAR_CLASS_UNKNOWN" ;
VAL_ 1545 DAS_TR_Obj23_MovingState 3 "RADAR_MOVESTATE_STANDING" 2 "RADAR_MOVESTATE_STOPPED" 1 "RADAR_MOVESTATE_MOVING" 0 "RADAR_MOVESTATE_INDETERMINATE" ;
VAL_ 1545 DAS_TR_Obj24_Class 4 "RADAR_CLASS_CONSTRUCTION_ELEMENT" 3 "RADAR_CLASS_MOVING_PEDESTRIAN" 2 "RADAR_CLASS_MOVING_TWO_WHEEL_VEHICLE" 1 "RADAR_CLASS_MOVING_FOUR_WHEEL_VEHICLE" 0 "RADAR_CLASS_UNKNOWN" ;
VAL_ 1545 DAS_TR_Obj24_MovingState 3 "RADAR_MOVESTATE_STANDING" 2 "RADAR_MOVESTATE_STOPPED" 1 "RADAR_MOVESTATE_MOVING" 0 "RADAR_MOVESTATE_INDETERMINATE" ;
VAL_ 1545 DAS_TR_Obj25_Class 4 "RADAR_CLASS_CONSTRUCTION_ELEMENT" 3 "RADAR_CLASS_MOVING_PEDESTRIAN" 2 "RADAR_CLASS_MOVING_TWO_WHEEL_VEHICLE" 1 "RADAR_CLASS_MOVING_FOUR_WHEEL_VEHICLE" 0 "RADAR_CLASS_UNKNOWN" ;
VAL_ 1545 DAS_TR_Obj25_MovingState 3 "RADAR_MOVESTATE_STANDING" 2 "RADAR_MOVESTATE_STOPPED" 1 "RADAR_MOVESTATE_MOVING" 0 "RADAR_MOVESTATE_INDETERMINATE" ;
VAL_ 1545 DAS_TR_Obj26_Class 4 "RADAR_CLASS_CONSTRUCTION_ELEMENT" 3 "RADAR_CLASS_MOVING_PEDESTRIAN" 2 "RADAR_CLASS_MOVING_TWO_WHEEL_VEHICLE" 1 "RADAR_CLASS_MOVING_FOUR_WHEEL_VEHICLE" 0 "RADAR_CLASS_UNKNOWN" ;
VAL_ 1545 DAS_TR_Obj26_MovingState 3 "RADAR_MOVESTATE_STANDING" 2 "RADAR_MOVESTATE_STOPPED" 1 "RADAR_MOVESTATE_MOVING" 0 "RADAR_MOVESTATE_INDETERMINATE" ;
VAL_ 1545 DAS_TR_Obj27_Class 4 "RADAR_CLASS_CONSTRUCTION_ELEMENT" 3 "RADAR_CLASS_MOVING_PEDESTRIAN" 2 "RADAR_CLASS_MOVING_TWO_WHEEL_VEHICLE" 1 "RADAR_CLASS_MOVING_FOUR_WHEEL_VEHICLE" 0 "RADAR_CLASS_UNKNOWN" ;
VAL_ 1545 DAS_TR_Obj27_MovingState 3 "RADAR_MOVESTATE_STANDING" 2 "RADAR_MOVESTATE_STOPPED" 1 "RADAR_MOVESTATE_MOVING" 0 "RADAR_MOVESTATE_INDETERMINATE" ;
VAL_ 1545 DAS_TR_Obj28_Class 4 "RADAR_CLASS_CONSTRUCTION_ELEMENT" 3 "RADAR_CLASS_MOVING_PEDESTRIAN" 2 "RADAR_CLASS_MOVING_TWO_WHEEL_VEHICLE" 1 "RADAR_CLASS_MOVING_FOUR_WHEEL_VEHICLE" 0 "RADAR_CLASS_UNKNOWN" ;
VAL_ 1545 DAS_TR_Obj28_MovingState 3 "RADAR_MOVESTATE_STANDING" 2 "RADAR_MOVESTATE_STOPPED" 1 "RADAR_MOVESTATE_MOVING" 0 "RADAR_MOVESTATE_INDETERMINATE" ;
VAL_ 1545 DAS_TR_Obj29_Class 4 "RADAR_CLASS_CONSTRUCTION_ELEMENT" 3 "RADAR_CLASS_MOVING_PEDESTRIAN" 2 "RADAR_CLASS_MOVING_TWO_WHEEL_VEHICLE" 1 "RADAR_CLASS_MOVING_FOUR_WHEEL_VEHICLE" 0 "RADAR_CLASS_UNKNOWN" ;
VAL_ 1545 DAS_TR_Obj29_MovingState 3 "RADAR_MOVESTATE_STANDING" 2 "RADAR_MOVESTATE_STOPPED" 1 "RADAR_MOVESTATE_MOVING" 0 "RADAR_MOVESTATE_INDETERMINATE" ;
VAL_ 1545 DAS_TR_Obj30_Class 4 "RADAR_CLASS_CONSTRUCTION_ELEMENT" 3 "RADAR_CLASS_MOVING_PEDESTRIAN" 2 "RADAR_CLASS_MOVING_TWO_WHEEL_VEHICLE" 1 "RADAR_CLASS_MOVING_FOUR_WHEEL_VEHICLE" 0 "RADAR_CLASS_UNKNOWN" ;
VAL_ 1545 DAS_TR_Obj30_MovingState 3 "RADAR_MOVESTATE_STANDING" 2 "RADAR_MOVESTATE_STOPPED" 1 "RADAR_MOVESTATE_MOVING" 0 "RADAR_MOVESTATE_INDETERMINATE" ;
VAL_ 1545 DAS_TR_Obj31_Class 4 "RADAR_CLASS_CONSTRUCTION_ELEMENT" 3 "RADAR_CLASS_MOVING_PEDESTRIAN" 2 "RADAR_CLASS_MOVING_TWO_WHEEL_VEHICLE" 1 "RADAR_CLASS_MOVING_FOUR_WHEEL_VEHICLE" 0 "RADAR_CLASS_UNKNOWN" ;
VAL_ 1545 DAS_TR_Obj31_MovingState 3 "RADAR_MOVESTATE_STANDING" 2 "RADAR_MOVESTATE_STOPPED" 1 "RADAR_MOVESTATE_MOVING" 0 "RADAR_MOVESTATE_INDETERMINATE" ;
VAL_ 1825 DAS_ussSensorIdX 5 "FRONT_SIDE" 4 "FRONT_CORNER" 3 "FRONT_INNER" 2 "REAR_SIDE" 1 "REAR_CORNER" 0 "REAR_INNER" ;
VAL_ 1825 DAS_ussThresholdXControl 1 "THRESHOLD_SET" 0 "THRESHOLD_CLEAR" ;
VAL_ 1826 DAS_ussSensorIdY 5 "FRONT_SIDE" 4 "FRONT_CORNER" 3 "FRONT_INNER" 2 "REAR_SIDE" 1 "REAR_CORNER" 0 "REAR_INNER" ;
VAL_ 1826 DAS_ussThresholdYControl 1 "THRESHOLD_SET" 0 "THRESHOLD_CLEAR" ;
VAL_ 585 DAS_autosteerVehiclesUsage 3 "BLACKLISTED" 2 "FUSED" 1 "AVAILABLE" 0 "REJECTED_UNAVAILABLE" ;
VAL_ 585 DAS_autosteerHPPUsage 3 "BLACKLISTED" 2 "FUSED" 1 "AVAILABLE" 0 "REJECTED_UNAVAILABLE" ;
VAL_ 585 DAS_autosteerNavigationUsage 3 "BLACKLISTED" 2 "FUSED" 1 "AVAILABLE" 0 "REJECTED_UNAVAILABLE" ;
VAL_ 585 DAS_autosteerModelUsage 3 "BLACKLISTED" 2 "FUSED" 1 "AVAILABLE" 0 "REJECTED_UNAVAILABLE" ;
VAL_ 585 DAS_autosteerBottsDotsUsage 3 "BLACKLISTED" 2 "FUSED" 1 "AVAILABLE" 0 "REJECTED_UNAVAILABLE" ;
VAL_ 585 DAS_offsetSide 3 "OFFSET_BOTH_OBJECTS" 2 "OFFSET_LEFT_OBJECT" 1 "OFFSET_RIGHT_OBJECT" 0 "NO_OFFSET" ;
VAL_ 585 DAS_roadSurfaceType 2 "ROAD_SURFACE_ENHANCED" 1 "ROAD_SURFACE_NORMAL" 0 "ROAD_SURFACE_SNA" ;
VAL_ 585 DAS_autosteerHealthState 5 "HEALTH_FAULT" 4 "HEALTH_ABORTING" 3 "HEALTH_SEVERELY_DEGRADED" 2 "HEALTH_DEGRADED" 1 "HEALTH_NOMINAL" 0 "HEALTH_UNAVAILABLE" ;
VAL_ 585 DAS_lastLinePreferenceReason 15 "NONE" 5 "COUNTRY_DRIVING_SIDE" 4 "AVOID_ONCOMING_LANES" 3 "NAVIGATION_BRANCH" 2 "NEIGHBOR_LANE_PROBABILIY" 1 "AGREEMENT_WITH_NEIGHBOR_LANES" 0 "OTHER_LANE_DISAGREES_WITH_MODEL" ;
VAL_ 585 DAS_plannerState 7 "TP_EXTSTATE_LANECHANGE_ABORT" 6 "TP_EXTSTATE_LANECHANGE_WAIT_FOR_FWD_OBSTACLE" 5 "TP_EXTSTATE_LANECHANGE_WAIT_FOR_SIDE_OBSTACLE" 4 "TP_EXTSTATE_LANECHANGE_IN_PROGRESS" 3 "TP_EXTSTATE_LANECHANGE_REQUESTED" 2 "TP_EXTSTATE_FOLLOW" 1 "TP_EXTSTATE_VL" 0 "TP_EXTSTATE_DISABLED" ;
VAL_ 585 DAS_lastAutosteerAbortReason 34 "UI_ABORT_REASON_USER_OVERRIDE_STRIKEOUT" 33 "UI_ABORT_REASON_SEATBELT_UNBUCKLED" 32 "UI_ABORT_REASON_AEB" 31 "UI_ABORT_REASON_NO_ABORT" 30 "UI_ABORT_REASON_CAMERA_FAILSAFES" 29 "UI_ABORT_REASON_ACC_CANCEL" 28 "UI_ABORT_REASON_EPAS_ERROR_CODE" 27 "UI_ABORT_REASON_PLANNER_OUTPUT_INVALID" 26 "UI_ABORT_REASON_FOLLOWER_OUTPUT_INVALID" 25 "UI_ABORT_REASON_VEHICLE_SPEED_ABOVE_MAX" 24 "UI_ABORT_REASON_DRIVING_OFF_NAV" 23 "UI_ABORT_REASON_CID_SWITCH_DISABLED" 22 "UI_ABORT_REASON_CRUISE_FAULT" 21 "UI_ABORT_REASON_COMPONENT_MIA" 20 "UI_ABORT_REASON_EPAS_EAC_DENIED" 19 "UI_ABORT_REASON_SIDE_COLLISION_IMMINENT" 18 "UI_ABORT_REASON_TRAILER_MODE" 17 "UI_ABORT_REASON_CAM_WATCHDOG" 16 "UI_ABORT_REASON_CAM_MSG_MIA" 15 "UI_ABORT_REASON_ME_MAIN_STATE_NOT_VISION" 14 "UI_ABORT_REASON_APP_ME_STATE_NOT_VISION" 2 "UI_ABORT_REASON_HM_STEERING_ERROR" 1 "UI_ABORT_REASON_HM_VIRTUAL_LANE_NO_INPUTS" 0 "UI_ABORT_REASON_HM_LANE_VIEW_RANGE" ;
VAL_ 585 DAS_navAvailable 1 "DAS_NAV_AVAILABLE" 0 "DAS_NAV_UNAVAILABLE" ;
VAL_ 585 DAS_accSmartSpeedState 7 "SNA" 5 "OFFRAMP_DELAY" 4 "SET_SPEED_SET_REQUESTED" 3 "ACTIVE_ONRAMP" 2 "ACTIVE_INTEGRATING" 1 "ACTIVE_OFFRAMP" 0 "NOT_ACTIVE" ;
VAL_ 585 DAS_ulcInProgress 1 "ULC_ACTIVE" 0 "ULC_INACTIVE" ;
VAL_ 585 DAS_behaviorType 3 "DAS_BEHAVIOR_LANE_CHANGE_RIGHT" 2 "DAS_BEHAVIOR_LANE_CHANGE_LEFT" 1 "DAS_BEHAVIOR_IN_LANE" 0 "DAS_BEHAVIOR_INVALID" ;
VAL_ 585 DAS_ulcType 2 "ULC_TYPE_SPEED" 1 "ULC_TYPE_NAV" 0 "ULC_TYPE_NONE" ;
VAL_ 585 DAS_rearVehDetectedThisCycle 1 "VEHICLE_DETECTED" 0 "VEHICLE_NOT_DETECTED" ;
VAL_ 585 DAS_rearLeftVehDetectedCurrent 1 "VEHICLE_DETECTED" 0 "VEHICLE_NOT_DETECTED" ;
VAL_ 585 DAS_rearRightVehDetectedTrip 1 "VEHICLE_DETECTED" 0 "VEHICLE_NOT_DETECTED" ;
VAL_ 585 DAS_rearLeftVehDetectedTrip 1 "VEHICLE_DETECTED" 0 "VEHICLE_NOT_DETECTED" ;
